[part 1 of 3: package /STLASWCs]
AUTOSAR XML (schema 00044)
package /STLASWCs
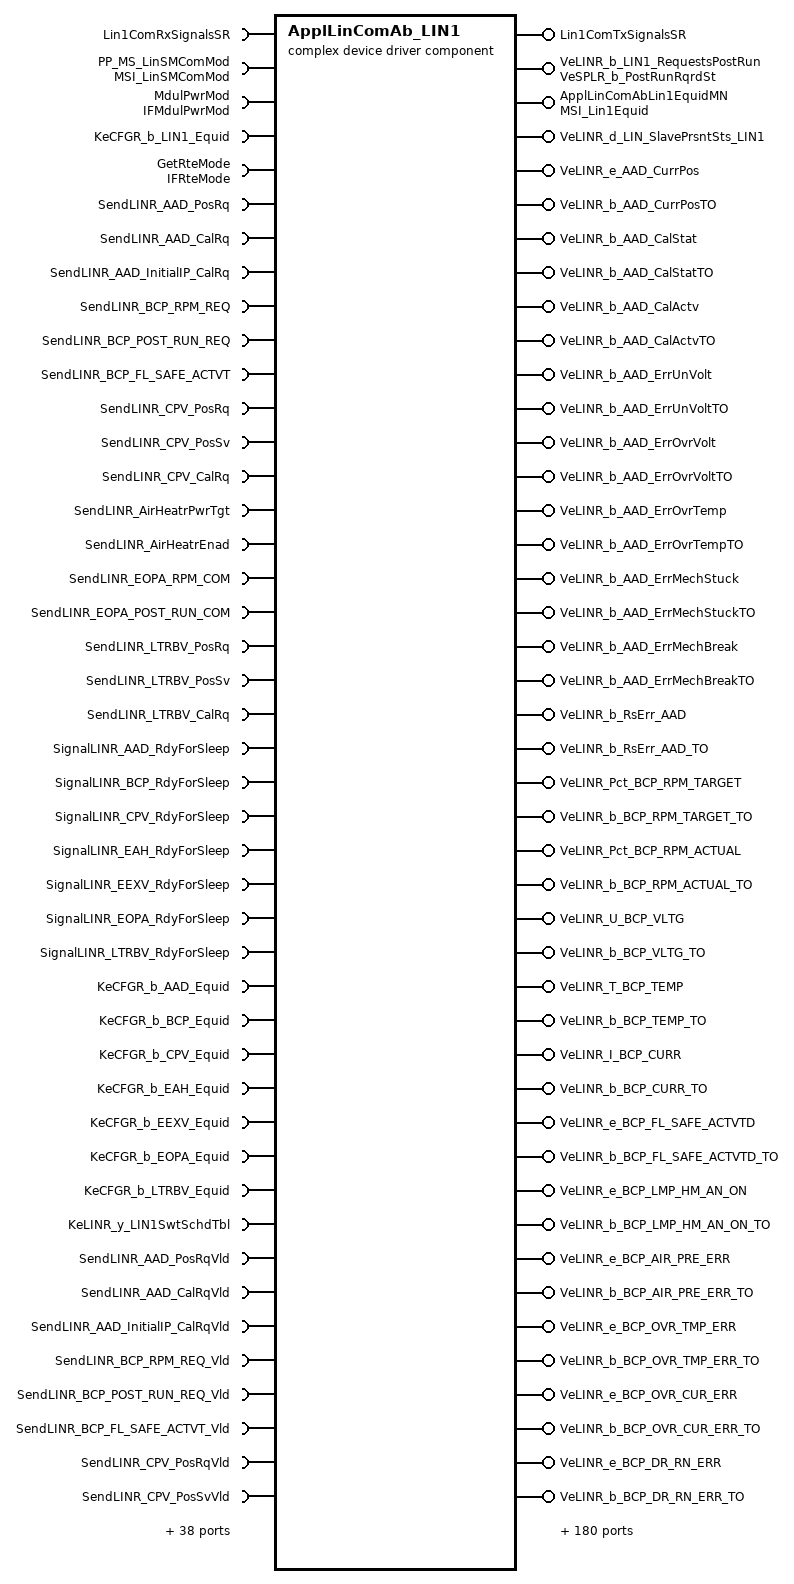
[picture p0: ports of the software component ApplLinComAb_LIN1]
  complex device driver sw component type ApplLinComAb_LIN1  # Application CAN Communication Abstraction Component - is responsible with receiving and sending CAN data from/to the lower BSW COM layers
    provide port Lin1ComTxSignalsSR: provided-interface=Lin1ComTxSignalsSR
      provided-com-specs:
        data-element=COMTXL_AAD_PosRq_ECM_AAD_DEMAND_Lin1, init-value=constant-reference=COMTXL_AAD_PosRq_ECM_AAD_DEMAND_Lin1_Init
        data-element=COMTXL_AAD_CalRq_ECM_AAD_DEMAND_Lin1, init-value=constant-reference=COMTXL_AAD_CalRq_ECM_AAD_DEMAND_Lin1_Init
        data-element=COMTXL_AAD_InitialIP_CalRq_ECM_AAD_DEMAND_Lin1, init-value=constant-reference=COMTXL_AAD_InitialIP_CalRq_ECM_AAD_DEMAND_Lin1_Init
        data-element=COMTXL_BCP_RPM_REQ_BCP_REQ_Lin1, init-value=constant-reference=COMTXL_BCP_RPM_REQ_BCP_REQ_Lin1_Init
        data-element=COMTXL_BCP_POST_RUN_REQ_BCP_REQ_Lin1, init-value=constant-reference=COMTXL_BCP_POST_RUN_REQ_BCP_REQ_Lin1_Init
        data-element=COMTXL_BCP_FL_SAFE_ACTVT_BCP_REQ_Lin1, init-value=constant-reference=COMTXL_BCP_FL_SAFE_ACTVT_BCP_REQ_Lin1_Init
        data-element=COMTXL_CPV_PosRq_CPV_REQ_Lin1, init-value=constant-reference=COMTXL_CPV_PosRq_CPV_REQ_Lin1_Init
        data-element=COMTXL_CPV_PosSv_CPV_REQ_Lin1, init-value=constant-reference=COMTXL_CPV_PosSv_CPV_REQ_Lin1_Init
        data-element=COMTXL_CPV_CalRq_CPV_REQ_Lin1, init-value=constant-reference=COMTXL_CPV_CalRq_CPV_REQ_Lin1_Init
        data-element=COMTXL_AirHeatrPwrTgt_HVEAHLIN18Fr03_Lin1, init-value=constant-reference=COMTXL_AirHeatrPwrTgt_HVEAHLIN18Fr03_Lin1_Init
        data-element=COMTXL_AirHeatrEnad_HVEAHLIN18Fr03_Lin1, init-value=constant-reference=COMTXL_AirHeatrEnad_HVEAHLIN18Fr03_Lin1_Init
        data-element=COMTXL_EOPA_RPM_COM_EOPA_REQ_Lin1, init-value=constant-reference=COMTXL_EOPA_RPM_COM_EOPA_REQ_Lin1_Init
        data-element=COMTXL_EOPA_POST_RUN_COM_EOPA_REQ_Lin1, init-value=constant-reference=COMTXL_EOPA_POST_RUN_COM_EOPA_REQ_Lin1_Init
        data-element=COMTXL_LTRBV_PosRq_LTRBV_REQ_Lin1, init-value=constant-reference=COMTXL_LTRBV_PosRq_LTRBV_REQ_Lin1_Init
        data-element=COMTXL_LTRBV_PosSv_LTRBV_REQ_Lin1, init-value=constant-reference=COMTXL_LTRBV_PosSv_LTRBV_REQ_Lin1_Init
        data-element=COMTXL_LTRBV_CalRq_LTRBV_REQ_Lin1, init-value=constant-reference=COMTXL_LTRBV_CalRq_LTRBV_REQ_Lin1_Init
        data-element=COMTXL_EEXV_PosRq_EEXV_REQ_Lin1, init-value=constant-reference=COMTXL_EEXV_PosRq_EEXV_REQ_Lin1_Init
        data-element=COMTXL_EEXV_CalCmd_EEXV_REQ_Lin1, init-value=constant-reference=COMTXL_EEXV_CalCmd_EEXV_REQ_Lin1_Init
        data-element=COMTXL_EXVM_PosRq_EXVM_REQ_Lin1, init-value=constant-reference=COMTXL_EXVM_PosRq_EXVM_REQ_Lin1_Init
        data-element=COMTXL_EXVM_CalCmd_EXVM_REQ_Lin1, init-value=constant-reference=COMTXL_EXVM_CalCmd_EXVM_REQ_Lin1_Init
        data-element=COMTXL_Control_TargetPos_FCPS_CoolantValve_Control_Lin1, init-value=constant-reference=COMTXL_Control_TargetPos_FCPS_CoolantValve_Control_Lin1_Init
        data-element=COMTXL_Control_Reserved1_FCPS_CoolantValve_Control_Lin1, init-value=constant-reference=COMTXL_Control_Reserved1_FCPS_CoolantValve_Control_Lin1_Init
        data-element=COMTXL_Control_BlockDetEnbl_FCPS_CoolantValve_Control_Lin1, init-value=constant-reference=COMTXL_Control_BlockDetEnbl_FCPS_CoolantValve_Control_Lin1_Init
        data-element=COMTXL_Control_DiagFunctnValue_FCPS_CoolantValve_Control_Lin1, init-value=constant-reference=COMTXL_Control_DiagFunctnValue_FCPS_CoolantValve_Control_Lin1_Init
        data-element=COMTXL_Control_Reserved{2..6}_FCPS_CoolantValve_Control_Lin1, init-value=constant-reference=COMTXL_Control_Reserved{2..6}_FCPS_CoolantValve_Control_Lin1_Init
    provide port VeLINR_b_LIN1_RequestsPostRun: nonqueued-sender-com-spec{data-element=VeSPLR_b_PostRunRqrdSt, init-value=1}, provided-interface=VeSPLR_b_PostRunRqrdSt  # Indicates LIN is ready for power down
    36 x require port:
      Lin1ComRxSignalsSR: required-interface=Lin1ComRxSignalsSR
        required-com-specs:
          data-element=COMRXL_AAD_CurrPos_AAD_ECM_STATUS_Lin1, alive-timeout=2.5, handle-never-received=true, init-value=constant-reference=COMRXL_AAD_CurrPos_AAD_ECM_STATUS_Lin1_Init
          data-element=COMRXL_AAD_CalStat_AAD_ECM_STATUS_Lin1, alive-timeout=2.5, handle-never-received=true, init-value=constant-reference=COMRXL_AAD_CalStat_AAD_ECM_STATUS_Lin1_Init
          data-element=COMRXL_AAD_CalActv_AAD_ECM_STATUS_Lin1, alive-timeout=2.5, handle-never-received=true, init-value=constant-reference=COMRXL_AAD_CalActv_AAD_ECM_STATUS_Lin1_Init
          data-element=COMRXL_AAD_ErrUnVolt_AAD_ECM_STATUS_Lin1, alive-timeout=2.5, handle-never-received=true, init-value=constant-reference=COMRXL_AAD_ErrUnVolt_AAD_ECM_STATUS_Lin1_Init
          data-element=COMRXL_AAD_ErrOvrVolt_AAD_ECM_STATUS_Lin1, alive-timeout=2.5, handle-never-received=true, init-value=constant-reference=COMRXL_AAD_ErrOvrVolt_AAD_ECM_STATUS_Lin1_Init
          data-element=COMRXL_AAD_ErrOvrTemp_AAD_ECM_STATUS_Lin1, alive-timeout=2.5, handle-never-received=true, init-value=constant-reference=COMRXL_AAD_ErrOvrTemp_AAD_ECM_STATUS_Lin1_Init
          data-element=COMRXL_AAD_ErrMechStuck_AAD_ECM_STATUS_Lin1, alive-timeout=2.5, handle-never-received=true, init-value=constant-reference=COMRXL_AAD_ErrMechStuck_AAD_ECM_STATUS_Lin1_Init
          data-element=COMRXL_AAD_ErrMechBreak_AAD_ECM_STATUS_Lin1, alive-timeout=2.5, handle-never-received=true, init-value=constant-reference=COMRXL_AAD_ErrMechBreak_AAD_ECM_STATUS_Lin1_Init
          data-element=COMRXL_RsErr_AAD_AAD_ECM_STATUS_Lin1, alive-timeout=2.5, handle-never-received=true, init-value=constant-reference=COMRXL_RsErr_AAD_AAD_ECM_STATUS_Lin1_Init
          data-element=COMRXL_BCP_RPM_TARGET_BCP_STAT_Lin1, alive-timeout=2.5, handle-never-received=true, init-value=constant-reference=COMRXL_BCP_RPM_TARGET_BCP_STAT_Lin1_Init
          data-element=COMRXL_BCP_RPM_ACTUAL_BCP_STAT_Lin1, alive-timeout=2.5, handle-never-received=true, init-value=constant-reference=COMRXL_BCP_RPM_ACTUAL_BCP_STAT_Lin1_Init
          data-element=COMRXL_BCP_VLTG_BCP_STAT_Lin1, alive-timeout=2.5, handle-never-received=true, init-value=constant-reference=COMRXL_BCP_VLTG_BCP_STAT_Lin1_Init
          data-element=COMRXL_BCP_TEMP_BCP_STAT_Lin1, alive-timeout=2.5, handle-never-received=true, init-value=constant-reference=COMRXL_BCP_TEMP_BCP_STAT_Lin1_Init
          data-element=COMRXL_BCP_CURR_BCP_STAT_Lin1, alive-timeout=2.5, handle-never-received=true, init-value=constant-reference=COMRXL_BCP_CURR_BCP_STAT_Lin1_Init
          data-element=COMRXL_BCP_FL_SAFE_ACTVTD_BCP_STAT_Lin1, alive-timeout=2.5, handle-never-received=true, init-value=constant-reference=COMRXL_BCP_FL_SAFE_ACTVTD_BCP_STAT_Lin1_Init
          data-element=COMRXL_BCP_LMP_HM_AN_ON_BCP_STAT_Lin1, alive-timeout=2.5, handle-never-received=true, init-value=constant-reference=COMRXL_BCP_LMP_HM_AN_ON_BCP_STAT_Lin1_Init
          data-element=COMRXL_BCP_AIR_PRE_ERR_BCP_STAT_Lin1, alive-timeout=2.5, handle-never-received=true, init-value=constant-reference=COMRXL_BCP_AIR_PRE_ERR_BCP_STAT_Lin1_Init
          data-element=COMRXL_BCP_OVR_TMP_ERR_BCP_STAT_Lin1, alive-timeout=2.5, handle-never-received=true, init-value=constant-reference=COMRXL_BCP_OVR_TMP_ERR_BCP_STAT_Lin1_Init
          data-element=COMRXL_BCP_OVR_CUR_ERR_BCP_STAT_Lin1, alive-timeout=2.5, handle-never-received=true, init-value=constant-reference=COMRXL_BCP_OVR_CUR_ERR_BCP_STAT_Lin1_Init
          data-element=COMRXL_BCP_DR_RN_ERR_BCP_STAT_Lin1, alive-timeout=2.5, handle-never-received=true, init-value=constant-reference=COMRXL_BCP_DR_RN_ERR_BCP_STAT_Lin1_Init
          data-element=COMRXL_BCP_VLTG_ERR_BCP_STAT_Lin1, alive-timeout=2.5, handle-never-received=true, init-value=constant-reference=COMRXL_BCP_VLTG_ERR_BCP_STAT_Lin1_Init
          data-element=COMRXL_BCP_DBLK_ACTV_BCP_STAT_Lin1, alive-timeout=2.5, handle-never-received=true, init-value=constant-reference=COMRXL_BCP_DBLK_ACTV_BCP_STAT_Lin1_Init
          data-element=COMRXL_BCP_MONTRNG_RPM_BCP_STAT_Lin1, alive-timeout=2.5, handle-never-received=true, init-value=constant-reference=COMRXL_BCP_MONTRNG_RPM_BCP_STAT_Lin1_Init
          data-element=COMRXL_BCP_NODE_ERR_BCP_STAT_Lin1, alive-timeout=2.5, handle-never-received=true, init-value=constant-reference=COMRXL_BCP_NODE_ERR_BCP_STAT_Lin1_Init
          data-element=COMRXL_BCP_POST_RUN_STAT_BCP_STAT_Lin1, alive-timeout=2.5, handle-never-received=true, init-value=constant-reference=COMRXL_BCP_POST_RUN_STAT_BCP_STAT_Lin1_Init
          data-element=COMRXL_RsErr_BCP_PUMP_BCP_STAT_Lin1, alive-timeout=2.5, handle-never-received=true, init-value=constant-reference=COMRXL_RsErr_BCP_PUMP_BCP_STAT_Lin1_Init
          data-element=COMRXL_BCP_VERSION_BCP_VER_Lin1, alive-timeout=2.5, handle-never-received=true, init-value=constant-reference=COMRXL_BCP_VERSION_BCP_VER_Lin1_Init
          data-element=COMRXL_BCP_SUPPLIER_BCP_VER_Lin1, alive-timeout=2.5, handle-never-received=true, init-value=constant-reference=COMRXL_BCP_SUPPLIER_BCP_VER_Lin1_Init
          data-element=COMRXL_CPV_PosAct_CPV_STAT_V2_Lin1, alive-timeout=2.5, handle-never-received=true, init-value=constant-reference=COMRXL_CPV_PosAct_CPV_STAT_V2_Lin1_Init
          data-element=COMRXL_CPV_ERR_CPV_STAT_V2_Lin1, alive-timeout=2.5, handle-never-received=true, init-value=constant-reference=COMRXL_CPV_ERR_CPV_STAT_V2_Lin1_Init
          data-element=COMRXL_CPV_Sts_CPV_STAT_V2_Lin1, alive-timeout=2.5, handle-never-received=true, init-value=constant-reference=COMRXL_CPV_Sts_CPV_STAT_V2_Lin1_Init
          data-element=COMRXL_RsErr_CPV_CPV_STAT_V2_Lin1, alive-timeout=2.5, handle-never-received=true, init-value=constant-reference=COMRXL_RsErr_CPV_CPV_STAT_V2_Lin1_Init
          data-element=COMRXL_AirHeatrICns_HVEAHLIN18Fr01_Lin1, alive-timeout=2.5, handle-never-received=true, init-value=constant-reference=COMRXL_AirHeatrICns_HVEAHLIN18Fr01_Lin1_Init
          data-element=COMRXL_AirHeatrHVmeas_HVEAHLIN18Fr01_Lin1, alive-timeout=2.5, handle-never-received=true, init-value=constant-reference=COMRXL_AirHeatrHVmeas_HVEAHLIN18Fr01_Lin1_Init
          data-element=COMRXL_AirHeatrPCBTemp_HVEAHLIN18Fr01_Lin1, alive-timeout=2.5, handle-never-received=true, init-value=constant-reference=COMRXL_AirHeatrPCBTemp_HVEAHLIN18Fr01_Lin1_Init
          data-element=COMRXL_AirHeatrCoreTemp_HVEAHLIN18Fr01_Lin1, alive-timeout=2.5, handle-never-received=true, init-value=constant-reference=COMRXL_AirHeatrCoreTemp_HVEAHLIN18Fr01_Lin1_Init
          data-element=COMRXL_RsErr_EAH_HVEAHLIN18Fr02_Lin1, alive-timeout=2.5, handle-never-received=true, init-value=constant-reference=COMRXL_RsErr_EAH_HVEAHLIN18Fr02_Lin1_Init
          data-element=COMRXL_AirHeatrWarnFltInCom_HVEAHLIN18Fr02_Lin1, alive-timeout=2.5, handle-never-received=true, init-value=constant-reference=COMRXL_AirHeatrWarnFltInCom_HVEAHLIN18Fr02_Lin1_Init
          data-element=COMRXL_AirHeatrWarnHvOutOfRng_HVEAHLIN18Fr02_Lin1, alive-timeout=2.5, handle-never-received=true, init-value=constant-reference=COMRXL_AirHeatrWarnHvOutOfRng_HVEAHLIN18Fr02_Lin1_Init
          data-element=COMRXL_AirHeatrWarnULoOutOfRng_HVEAHLIN18Fr02_Lin1, alive-timeout=2.5, handle-never-received=true, init-value=constant-reference=COMRXL_AirHeatrWarnULoOutOfRng_HVEAHLIN18Fr02_Lin1_Init
          data-element=COMRXL_AirHeatrWarnTmpOvrheatg_HVEAHLIN18Fr02_Lin1, alive-timeout=2.5, handle-never-received=true, init-value=constant-reference=COMRXL_AirHeatrWarnTmpOvrheatg_HVEAHLIN18Fr02_Lin1_Init
          data-element=COMRXL_AirHeatrWarnICnsOutOfRng_HVEAHLIN18Fr02_Lin1, alive-timeout=2.5, handle-never-received=true, init-value=constant-reference=COMRXL_AirHeatrWarnICnsOutOfRng_HVEAHLIN18Fr02_Lin1_Init
          data-element=COMRXL_AirHeatrDmgIntHwProtn_HVEAHLIN18Fr02_Lin1, alive-timeout=2.5, handle-never-received=true, init-value=constant-reference=COMRXL_AirHeatrDmgIntHwProtn_HVEAHLIN18Fr02_Lin1_Init
          data-element=COMRXL_AirHeatrDmgPCBTmpSnsrFlt_HVEAHLIN18Fr02_Lin1, alive-timeout=2.5, handle-never-received=true, init-value=constant-reference=COMRXL_AirHeatrDmgPCBTmpSnsrFlt_HVEAHLIN18Fr02_Lin1_Init
          data-element=COMRXL_AirHeatrDmgCircForDrvrShoOrOpen_HVEAHLIN18Fr02_Lin1, alive-timeout=2.5, handle-never-received=true, init-value=constant-reference=COMRXL_AirHeatrDmgCircForDrvrShoOrOpen_HVEAHLIN18Fr02_Lin1_Init
          data-element=COMRXL_AirHeatrDmgHVISnsrFlt_HVEAHLIN18Fr02_Lin1, alive-timeout=2.5, handle-never-received=true, init-value=constant-reference=COMRXL_AirHeatrDmgHVISnsrFlt_HVEAHLIN18Fr02_Lin1_Init
          data-element=COMRXL_AirHeatrDmgMemErr_HVEAHLIN18Fr02_Lin1, alive-timeout=2.5, handle-never-received=true, init-value=constant-reference=COMRXL_AirHeatrDmgMemErr_HVEAHLIN18Fr02_Lin1_Init
          data-element=COMRXL_AirHeatrDmgHtrCoreTmpSnsrFlt_HVEAHLIN18Fr02_Lin1, alive-timeout=2.5, handle-never-received=true, init-value=constant-reference=COMRXL_AirHeatrDmgHtrCoreTmpSnsrFlt_HVEAHLIN18Fr02_Lin1_Init
          data-element=COMRXL_AirHeatrWarnPCBOvrTmp_HVEAHLIN18Fr02_Lin1, alive-timeout=2.5, handle-never-received=true, init-value=constant-reference=COMRXL_AirHeatrWarnPCBOvrTmp_HVEAHLIN18Fr02_Lin1_Init
          data-element=COMRXL_AirHeatrWarnHtrCoreOvrTmp_HVEAHLIN18Fr02_Lin1, alive-timeout=2.5, handle-never-received=true, init-value=constant-reference=COMRXL_AirHeatrWarnHtrCoreOvrTmp_HVEAHLIN18Fr02_Lin1_Init
          data-element=COMRXL_EOPA_RPM_TGT_EOPA_STAT_Lin1, alive-timeout=2.5, handle-never-received=true, init-value=constant-reference=COMRXL_EOPA_RPM_TGT_EOPA_STAT_Lin1_Init
          data-element=COMRXL_EOPA_RPM_ACTL_EOPA_STAT_Lin1, alive-timeout=2.5, handle-never-received=true, init-value=constant-reference=COMRXL_EOPA_RPM_ACTL_EOPA_STAT_Lin1_Init
          data-element=COMRXL_EOPA_VLTG_EOPA_STAT_Lin1, alive-timeout=2.5, handle-never-received=true, init-value=constant-reference=COMRXL_EOPA_VLTG_EOPA_STAT_Lin1_Init
          data-element=COMRXL_EOPA_TEMP_EOPA_STAT_Lin1, alive-timeout=2.5, handle-never-received=true, init-value=constant-reference=COMRXL_EOPA_TEMP_EOPA_STAT_Lin1_Init
          data-element=COMRXL_EOPA_CURR_EOPA_STAT_Lin1, alive-timeout=2.5, handle-never-received=true, init-value=constant-reference=COMRXL_EOPA_CURR_EOPA_STAT_Lin1_Init
          data-element=COMRXL_EOPA_LOW_TMP_STAT_EOPA_STAT_Lin1, alive-timeout=2.5, handle-never-received=true, init-value=constant-reference=COMRXL_EOPA_LOW_TMP_STAT_EOPA_STAT_Lin1_Init
          data-element=COMRXL_EOPA_MONTRNG_RPM_EOPA_STAT_Lin1, alive-timeout=2.5, handle-never-received=true, init-value=constant-reference=COMRXL_EOPA_MONTRNG_RPM_EOPA_STAT_Lin1_Init
          data-element=COMRXL_EOPA_LMP_HM_AN_ON_EOPA_STAT_Lin1, alive-timeout=2.5, handle-never-received=true, init-value=constant-reference=COMRXL_EOPA_LMP_HM_AN_ON_EOPA_STAT_Lin1_Init
          data-element=COMRXL_EOPA_OV_TMP_ER_EOPA_STAT_Lin1, alive-timeout=2.5, handle-never-received=true, init-value=constant-reference=COMRXL_EOPA_OV_TMP_ER_EOPA_STAT_Lin1_Init
          data-element=COMRXL_EOPA_OV_CUR_ER_EOPA_STAT_Lin1, alive-timeout=2.5, handle-never-received=true, init-value=constant-reference=COMRXL_EOPA_OV_CUR_ER_EOPA_STAT_Lin1_Init
          data-element=COMRXL_EOPA_DR_RN_ER_EOPA_STAT_Lin1, alive-timeout=2.5, handle-never-received=true, init-value=constant-reference=COMRXL_EOPA_DR_RN_ER_EOPA_STAT_Lin1_Init
          data-element=COMRXL_EOPA_VLTG_ER_EOPA_STAT_Lin1, alive-timeout=2.5, handle-never-received=true, init-value=constant-reference=COMRXL_EOPA_VLTG_ER_EOPA_STAT_Lin1_Init
          data-element=COMRXL_EOPA_Stall_Event_EOPA_STAT_Lin1, alive-timeout=2.5, handle-never-received=true, init-value=constant-reference=COMRXL_EOPA_Stall_Event_EOPA_STAT_Lin1_Init
          data-element=COMRXL_EOPA_POST_RUN_STAT_EOPA_STAT_Lin1, alive-timeout=2.5, handle-never-received=true, init-value=constant-reference=COMRXL_EOPA_POST_RUN_STAT_EOPA_STAT_Lin1_Init
          data-element=COMRXL_RsErr_EOPA_EOPA_STAT_Lin1, alive-timeout=2.5, handle-never-received=true, init-value=constant-reference=COMRXL_RsErr_EOPA_EOPA_STAT_Lin1_Init
          data-element=COMRXL_EOPA_OIL_TEMP_EOPA_STAT2_Lin1, alive-timeout=2.5, handle-never-received=true, init-value=constant-reference=COMRXL_EOPA_OIL_TEMP_EOPA_STAT2_Lin1_Init
          data-element=COMRXL_EOPA_HW_VER_EOPA_VER_Lin1, alive-timeout=2.5, handle-never-received=true, init-value=constant-reference=COMRXL_EOPA_HW_VER_EOPA_VER_Lin1_Init
          data-element=COMRXL_EOPA_SW_VER_EOPA_VER_Lin1, alive-timeout=2.5, handle-never-received=true, init-value=constant-reference=COMRXL_EOPA_SW_VER_EOPA_VER_Lin1_Init
          data-element=COMRXL_LTRBV_PosAct_LTRBV_STAT_Lin1, alive-timeout=2.5, handle-never-received=true, init-value=constant-reference=COMRXL_LTRBV_PosAct_LTRBV_STAT_Lin1_Init
          data-element=COMRXL_LTRBV_ERR_LTRBV_STAT_Lin1, alive-timeout=2.5, handle-never-received=true, init-value=constant-reference=COMRXL_LTRBV_ERR_LTRBV_STAT_Lin1_Init
          data-element=COMRXL_LTRBV_MotorVolt_LTRBV_STAT_Lin1, alive-timeout=2.5, handle-never-received=true, init-value=constant-reference=COMRXL_LTRBV_MotorVolt_LTRBV_STAT_Lin1_Init
          data-element=COMRXL_LTRBV_Sts_LTRBV_STAT_Lin1, alive-timeout=2.5, handle-never-received=true, init-value=constant-reference=COMRXL_LTRBV_Sts_LTRBV_STAT_Lin1_Init
          data-element=COMRXL_RsErr_LTRBV_LTRBV_STAT_Lin1, alive-timeout=2.5, handle-never-received=true, init-value=constant-reference=COMRXL_RsErr_LTRBV_LTRBV_STAT_Lin1_Init
          data-element=COMRXL_CPV_MotorVolt_CPV_STAT_V2_Lin1, alive-timeout=2.5, handle-never-received=true, init-value=constant-reference=COMRXL_CPV_MotorVolt_CPV_STAT_V2_Lin1_Init
          data-element=COMRXL_CPV_CalStat_CPV_STAT_V2_Lin1, alive-timeout=2.5, handle-never-received=true, init-value=constant-reference=COMRXL_CPV_CalStat_CPV_STAT_V2_Lin1_Init
          data-element=COMRXL_AirHeatrSts_HVEAHLIN18Fr01_Lin1, alive-timeout=2.5, handle-never-received=true, init-value=constant-reference=COMRXL_AirHeatrSts_HVEAHLIN18Fr01_Lin1_Init
          data-element=COMRXL_AirHeatrPwrCns_HVEAHLIN18Fr01_Lin1, alive-timeout=2.5, handle-never-received=true, init-value=constant-reference=COMRXL_AirHeatrPwrCns_HVEAHLIN18Fr01_Lin1_Init
          data-element=COMRXL_EEXV_PosAct_EEXV_STAT_Lin1, alive-timeout=2.5, handle-never-received=true, init-value=constant-reference=COMRXL_EEXV_PosAct_EEXV_STAT_Lin1_Init
          data-element=COMRXL_EEXV_CalStat_EEXV_STAT_Lin1, alive-timeout=2.5, handle-never-received=true, init-value=constant-reference=COMRXL_EEXV_CalStat_EEXV_STAT_Lin1_Init
          data-element=COMRXL_EEXV_CalRq_EEXV_STAT_Lin1, alive-timeout=2.5, handle-never-received=true, init-value=constant-reference=COMRXL_EEXV_CalRq_EEXV_STAT_Lin1_Init
          data-element=COMRXL_RsErr_EEXV_EEXV_STAT_Lin1, alive-timeout=2.5, handle-never-received=true, init-value=constant-reference=COMRXL_RsErr_EEXV_EEXV_STAT_Lin1_Init
          data-element=COMRXL_EEXV_Sts_EEXV_STAT_Lin1, alive-timeout=2.5, handle-never-received=true, init-value=constant-reference=COMRXL_EEXV_Sts_EEXV_STAT_Lin1_Init
          data-element=COMRXL_EEXV_ERR_EEXV_STAT_Lin1, alive-timeout=2.5, handle-never-received=true, init-value=constant-reference=COMRXL_EEXV_ERR_EEXV_STAT_Lin1_Init
          data-element=COMRXL_EEXV_SupplyVolt_EEXV_STAT_Lin1, alive-timeout=2.5, handle-never-received=true, init-value=constant-reference=COMRXL_EEXV_SupplyVolt_EEXV_STAT_Lin1_Init
          data-element=COMRXL_EEXV_Refrigerant_Pressure_EEXV_STAT_Lin1, alive-timeout=2.5, handle-never-received=true, init-value=constant-reference=COMRXL_EEXV_Refrigerant_Pressure_EEXV_STAT_Lin1_Init
          data-element=COMRXL_EEXV_Board_Temp_EEXV_STAT_Lin1, alive-timeout=2.5, handle-never-received=true, init-value=constant-reference=COMRXL_EEXV_Board_Temp_EEXV_STAT_Lin1_Init
          data-element=COMRXL_EEXV_Refrigerant_Temp_EEXV_STAT_Lin1, alive-timeout=2.5, handle-never-received=true, init-value=constant-reference=COMRXL_EEXV_Refrigerant_Temp_EEXV_STAT_Lin1_Init
          data-element=COMRXL_EXVM_PosAct_EXVM_STAT_Lin1, alive-timeout=2.5, handle-never-received=true, init-value=constant-reference=COMRXL_EXVM_PosAct_EXVM_STAT_Lin1_Init
          data-element=COMRXL_EXVM_CalStat_EXVM_STAT_Lin1, alive-timeout=2.5, handle-never-received=true, init-value=constant-reference=COMRXL_EXVM_CalStat_EXVM_STAT_Lin1_Init
          data-element=COMRXL_EXVM_CalRq_EXVM_STAT_Lin1, alive-timeout=2.5, handle-never-received=true, init-value=constant-reference=COMRXL_EXVM_CalRq_EXVM_STAT_Lin1_Init
          data-element=COMRXL_RsErr_EXVM_EXVM_STAT_Lin1, alive-timeout=2.5, handle-never-received=true, init-value=constant-reference=COMRXL_RsErr_EXVM_EXVM_STAT_Lin1_Init
          data-element=COMRXL_EXVM_Sts_EXVM_STAT_Lin1, alive-timeout=2.5, handle-never-received=true, init-value=constant-reference=COMRXL_EXVM_Sts_EXVM_STAT_Lin1_Init
          data-element=COMRXL_EXVM_ERR_EXVM_STAT_Lin1, alive-timeout=2.5, handle-never-received=true, init-value=constant-reference=COMRXL_EXVM_ERR_EXVM_STAT_Lin1_Init
          data-element=COMRXL_EXVM_SupplyVolt_EXVM_STAT_Lin1, alive-timeout=2.5, handle-never-received=true, init-value=constant-reference=COMRXL_EXVM_SupplyVolt_EXVM_STAT_Lin1_Init
          data-element=COMRXL_EXVM_Refrigerant_Pressure_EXVM_STAT_Lin1, alive-timeout=2.5, handle-never-received=true, init-value=constant-reference=COMRXL_EXVM_Refrigerant_Pressure_EXVM_STAT_Lin1_Init
          data-element=COMRXL_EXVM_Board_Temp_EXVM_STAT_Lin1, alive-timeout=2.5, handle-never-received=true, init-value=constant-reference=COMRXL_EXVM_Board_Temp_EXVM_STAT_Lin1_Init
          data-element=COMRXL_EXVM_Refrigerant_Temp_EXVM_STAT_Lin1, alive-timeout=2.5, handle-never-received=true, init-value=constant-reference=COMRXL_EXVM_Refrigerant_Temp_EXVM_STAT_Lin1_Init
          data-element=COMRXL_LTRBV_CalStat_LTRBV_STAT_Lin1, alive-timeout=2.5, handle-never-received=true, init-value=constant-reference=COMRXL_LTRBV_CalStat_LTRBV_STAT_Lin1_Init
          data-element=COMRXL_CoolantValve_ErrLinCom_CoolantValve_Com_Lin1, alive-timeout=2.5, handle-never-received=true, init-value=constant-reference=COMRXL_CoolantValve_ErrLinCom_CoolantValve_Com_Lin1_Init
          data-element=COMRXL_CoolantValve_ErrPosition_CoolantValve_Com_Lin1, alive-timeout=2.5, handle-never-received=true, init-value=constant-reference=COMRXL_CoolantValve_ErrPosition_CoolantValve_Com_Lin1_Init
          data-element=COMRXL_CoolantValve_SelfCalReq_CoolantValve_Com_Lin1, alive-timeout=2.5, handle-never-received=true, init-value=constant-reference=COMRXL_CoolantValve_SelfCalReq_CoolantValve_Com_Lin1_Init
          data-element=COMRXL_CoolantValve_SystemState_CoolantValve_Com_Lin1, alive-timeout=2.5, handle-never-received=true, init-value=constant-reference=COMRXL_CoolantValve_SystemState_CoolantValve_Com_Lin1_Init
          data-element=COMRXL_CoolantValve_EcuVoltage_CoolantValve_Com_Lin1, alive-timeout=2.5, handle-never-received=true, init-value=constant-reference=COMRXL_CoolantValve_EcuVoltage_CoolantValve_Com_Lin1_Init
          data-element=COMRXL_CoolantValve_ActuatorPositionTrgt_CoolantValve_Com_Lin1, alive-timeout=2.5, handle-never-received=true, init-value=constant-reference=COMRXL_CoolantValve_ActuatorPositionTrgt_CoolantValve_Com_Lin1_Init
          data-element=COMRXL_CoolantValve_ActuatorPositionAct_CoolantValve_Com_Lin1, alive-timeout=2.5, handle-never-received=true, init-value=constant-reference=COMRXL_CoolantValve_ActuatorPositionAct_CoolantValve_Com_Lin1_Init
          data-element=COMRXL_CoolantValve_EcuTemperatur_CoolantValve_Com_Lin1, alive-timeout=2.5, handle-never-received=true, init-value=constant-reference=COMRXL_CoolantValve_EcuTemperatur_CoolantValve_Com_Lin1_Init
          data-element=COMRXL_CoolantValve_Err_Motor_CoolantValve_Com_Lin1, alive-timeout=2.5, handle-never-received=true, init-value=constant-reference=COMRXL_CoolantValve_Err_Motor_CoolantValve_Com_Lin1_Init
          data-element=COMRXL_CoolantValve_Err_Voltage_CoolantValve_Com_Lin1, alive-timeout=2.5, handle-never-received=true, init-value=constant-reference=COMRXL_CoolantValve_Err_Voltage_CoolantValve_Com_Lin1_Init
          data-element=COMRXL_CoolantValve_Err_Ecu_CoolantValve_Com_Lin1, alive-timeout=2.5, handle-never-received=true, init-value=constant-reference=COMRXL_CoolantValve_Err_Ecu_CoolantValve_Com_Lin1_Init
          data-element=COMRXL_CoolantValve_ResponseError_CoolantValve_Com_Lin1, alive-timeout=2.5, handle-never-received=true, init-value=constant-reference=COMRXL_CoolantValve_ResponseError_CoolantValve_Com_Lin1_Init
      PP_MS_LinSMComMod: mode-switch-receiver-com-spec=MDGP_MSI_LinSMComMod, required-interface=MSI_LinSMComMod  # Mode switch port used to indicate Linsm comm state
      MdulPwrMod: mode-switch-receiver-com-spec=AppMode_MDGP_ESH_Mode, required-interface=IFMdulPwrMod  # Mode switch port used to indicate ECU state
      KeCFGR_b_LIN1_Equid: parameter-require-com-spec{init-value=Value:1, parameter=KeCFGR_b_LIN1_Equid}, required-interface=KeCFGR_b_LIN1_Equid
      GetRteMode: client-com-spec=GetMODR_b_InPostRunMode, required-interface=IFRteMode
      SendLINR_AAD_PosRq: nonqueued-receiver-com-spec{data-element=SendLINR_AAD_PosRq, init-value=SendLINR_AAD_PosRqValue:15}, required-interface=SendLINR_AAD_PosRq
      SendLINR_AAD_CalRq: nonqueued-receiver-com-spec{data-element=SendLINR_AAD_CalRq, init-value=SendLINR_AAD_CalRqValue:0}, required-interface=SendLINR_AAD_CalRq
      SendLINR_AAD_InitialIP_CalRq: nonqueued-receiver-com-spec{data-element=SendLINR_AAD_InitialIP_CalRq, init-value=0}, required-interface=SendLINR_AAD_InitialIP_CalRq
      SendLINR_BCP_RPM_REQ: nonqueued-receiver-com-spec{data-element=SendLINR_BCP_RPM_REQ, init-value=SendLINR_BCP_RPM_REQValue:100.3935}, required-interface=SendLINR_BCP_RPM_REQ
      SendLINR_BCP_POST_RUN_REQ: nonqueued-receiver-com-spec{data-element=SendLINR_BCP_POST_RUN_REQ, init-value=SendLINR_BCP_POST_RUN_REQValue:7}, required-interface=SendLINR_BCP_POST_RUN_REQ
      SendLINR_BCP_FL_SAFE_ACTVT: nonqueued-receiver-com-spec{data-element=SendLINR_BCP_FL_SAFE_ACTVT, init-value=SendLINR_BCP_FL_SAFE_ACTVTValue:3}, required-interface=SendLINR_BCP_FL_SAFE_ACTVT
      SendLINR_CPV_PosRq: nonqueued-receiver-com-spec{data-element=SendLINR_CPV_PosRq, init-value=SendLINR_CPV_PosRqValue:0}, required-interface=SendLINR_CPV_PosRq
      SendLINR_CPV_PosSv: nonqueued-receiver-com-spec{data-element=SendLINR_CPV_PosSv, init-value=SendLINR_CPV_PosSvValue:0}, required-interface=SendLINR_CPV_PosSv
      SendLINR_CPV_CalRq: nonqueued-receiver-com-spec{data-element=SendLINR_CPV_CalRq, init-value=SendLINR_CPV_CalRqValue:0}, required-interface=SendLINR_CPV_CalRq
      SendLINR_AirHeatrPwrTgt: nonqueued-receiver-com-spec{data-element=SendLINR_AirHeatrPwrTgt, init-value=SendLINR_AirHeatrPwrTgtValue:255}, required-interface=SendLINR_AirHeatrPwrTgt
      SendLINR_AirHeatrEnad: nonqueued-receiver-com-spec{data-element=SendLINR_AirHeatrEnad, init-value=SendLINR_AirHeatrEnadValue:0}, required-interface=SendLINR_AirHeatrEnad
      SendLINR_EOPA_RPM_COM: nonqueued-receiver-com-spec{data-element=SendLINR_EOPA_RPM_COM, init-value=SendLINR_EOPA_RPM_COMValue:6120}, required-interface=SendLINR_EOPA_RPM_COM
      SendLINR_EOPA_POST_RUN_COM: nonqueued-receiver-com-spec{data-element=SendLINR_EOPA_POST_RUN_COM, init-value=SendLINR_EOPA_POST_RUN_COMValue:7}, required-interface=SendLINR_EOPA_POST_RUN_COM
      SendLINR_LTRBV_PosRq: nonqueued-receiver-com-spec{data-element=SendLINR_LTRBV_PosRq, init-value=SendLINR_LTRBV_PosRqValue:0}, required-interface=SendLINR_LTRBV_PosRq
      SendLINR_LTRBV_PosSv: nonqueued-receiver-com-spec{data-element=SendLINR_LTRBV_PosSv, init-value=SendLINR_LTRBV_PosSvValue:0}, required-interface=SendLINR_LTRBV_PosSv
      SendLINR_LTRBV_CalRq: nonqueued-receiver-com-spec{data-element=SendLINR_LTRBV_CalRq, init-value=SendLINR_LTRBV_CalRqValue:0}, required-interface=SendLINR_LTRBV_CalRq
      SignalLINR_AAD_RdyForSleep: nonqueued-receiver-com-spec{data-element=SignalLINR_AAD_RdyForSleep, init-value=SignalLINR_AAD_RdyForSleepValue:0}, required-interface=SignalLINR_AAD_RdyForSleep
      SignalLINR_BCP_RdyForSleep: nonqueued-receiver-com-spec{data-element=SignalLINR_BCP_RdyForSleep, init-value=SignalLINR_BCP_RdyForSleepValue:0}, required-interface=SignalLINR_BCP_RdyForSleep
      SignalLINR_CPV_RdyForSleep: nonqueued-receiver-com-spec{data-element=SignalLINR_CPV_RdyForSleep, init-value=SignalLINR_CPV_RdyForSleepValue:0}, required-interface=SignalLINR_CPV_RdyForSleep
      SignalLINR_EAH_RdyForSleep: nonqueued-receiver-com-spec{data-element=SignalLINR_EAH_RdyForSleep, init-value=SignalLINR_EAH_RdyForSleepValue:0}, required-interface=SignalLINR_EAH_RdyForSleep
      SignalLINR_EEXV_RdyForSleep: nonqueued-receiver-com-spec{data-element=SignalLINR_EEXV_RdyForSleep, init-value=SignalLINR_EEXV_RdyForSleepValue:0}, required-interface=SignalLINR_EEXV_RdyForSleep
      SignalLINR_EOPA_RdyForSleep: nonqueued-receiver-com-spec{data-element=SignalLINR_EOPA_RdyForSleep, init-value=SignalLINR_EOPA_RdyForSleepValue:0}, required-interface=SignalLINR_EOPA_RdyForSleep
      SignalLINR_LTRBV_RdyForSleep: nonqueued-receiver-com-spec{data-element=SignalLINR_LTRBV_RdyForSleep, init-value=SignalLINR_LTRBV_RdyForSleepValue:0}, required-interface=SignalLINR_LTRBV_RdyForSleep
      KeCFGR_b_AAD_Equid: parameter-require-com-spec{init-value=Value:0, parameter=KeCFGR_b_AAD_Equid}, required-interface=KeCFGR_b_AAD_Equid
      KeCFGR_b_BCP_Equid: parameter-require-com-spec{init-value=Value:0, parameter=KeCFGR_b_BCP_Equid}, required-interface=KeCFGR_b_BCP_Equid
      KeCFGR_b_CPV_Equid: parameter-require-com-spec{init-value=Value:0, parameter=KeCFGR_b_CPV_Equid}, required-interface=KeCFGR_b_CPV_Equid
      KeCFGR_b_EAH_Equid: parameter-require-com-spec{init-value=Value:0, parameter=KeCFGR_b_EAH_Equid}, required-interface=KeCFGR_b_EAH_Equid
      KeCFGR_b_EEXV_Equid: parameter-require-com-spec{init-value=Value:0, parameter=KeCFGR_b_EEXV_Equid}, required-interface=KeCFGR_b_EEXV_Equid
      KeCFGR_b_EOPA_Equid: parameter-require-com-spec{init-value=Value:0, parameter=KeCFGR_b_EOPA_Equid}, required-interface=KeCFGR_b_EOPA_Equid
      KeCFGR_b_LTRBV_Equid: parameter-require-com-spec{init-value=Value:0, parameter=KeCFGR_b_LTRBV_Equid}, required-interface=KeCFGR_b_LTRBV_Equid
      KeLINR_y_LIN1SwtSchdTbl: parameter-require-com-spec{init-value=Value:0, parameter=KeLINR_y_LIN1SwtSchdTbl}, required-interface=KeLINR_y_LIN1SwtSchdTbl
    148 x provide port:
      ApplLinComAbLin1EquidMN: mode-switch-sender-com-spec{mode-group=MDGP_MSI_Lin1Equid, queue-length=1}, provided-interface=MSI_Lin1Equid
      VeLINR_d_LIN_SlavePrsntSts_LIN1: nonqueued-sender-com-spec{data-element=VeLINR_d_LIN_SlavePrsntSts_LIN1, init-value=Value:0}, provided-interface=VeLINR_d_LIN_SlavePrsntSts_LIN1
      VeLINR_e_AAD_CurrPos: nonqueued-sender-com-spec{data-element=VeLINR_e_AAD_CurrPos, init-value=VeLINR_e_AAD_CurrPosValue:15}, provided-interface=VeLINR_e_AAD_CurrPos
      VeLINR_b_AAD_CurrPosTO: nonqueued-sender-com-spec{data-element=VeLINR_b_AAD_CurrPosTO, init-value=VeLINR_b_AAD_CurrPosTOValue:0}, provided-interface=VeLINR_b_AAD_CurrPosTO
      VeLINR_b_AAD_CalStat: nonqueued-sender-com-spec{data-element=VeLINR_b_AAD_CalStat, init-value=VeLINR_b_AAD_CalStatValue:0}, provided-interface=VeLINR_b_AAD_CalStat
      VeLINR_b_AAD_CalStatTO: nonqueued-sender-com-spec{data-element=VeLINR_b_AAD_CalStatTO, init-value=VeLINR_b_AAD_CalStatTOValue:0}, provided-interface=VeLINR_b_AAD_CalStatTO
      VeLINR_b_AAD_CalActv: nonqueued-sender-com-spec{data-element=VeLINR_b_AAD_CalActv, init-value=VeLINR_b_AAD_CalActvValue:0}, provided-interface=VeLINR_b_AAD_CalActv
      VeLINR_b_AAD_CalActvTO: nonqueued-sender-com-spec{data-element=VeLINR_b_AAD_CalActvTO, init-value=VeLINR_b_AAD_CalActvTOValue:0}, provided-interface=VeLINR_b_AAD_CalActvTO
      VeLINR_b_AAD_ErrUnVolt: nonqueued-sender-com-spec{data-element=VeLINR_b_AAD_ErrUnVolt, init-value=VeLINR_b_AAD_ErrUnVoltValue:0}, provided-interface=VeLINR_b_AAD_ErrUnVolt
      VeLINR_b_AAD_ErrUnVoltTO: nonqueued-sender-com-spec{data-element=VeLINR_b_AAD_ErrUnVoltTO, init-value=VeLINR_b_AAD_ErrUnVoltTOValue:0}, provided-interface=VeLINR_b_AAD_ErrUnVoltTO
      VeLINR_b_AAD_ErrOvrVolt: nonqueued-sender-com-spec{data-element=VeLINR_b_AAD_ErrOvrVolt, init-value=VeLINR_b_AAD_ErrOvrVoltValue:0}, provided-interface=VeLINR_b_AAD_ErrOvrVolt
      VeLINR_b_AAD_ErrOvrVoltTO: nonqueued-sender-com-spec{data-element=VeLINR_b_AAD_ErrOvrVoltTO, init-value=VeLINR_b_AAD_ErrOvrVoltTOValue:0}, provided-interface=VeLINR_b_AAD_ErrOvrVoltTO
      VeLINR_b_AAD_ErrOvrTemp: nonqueued-sender-com-spec{data-element=VeLINR_b_AAD_ErrOvrTemp, init-value=VeLINR_b_AAD_ErrOvrTempValue:0}, provided-interface=VeLINR_b_AAD_ErrOvrTemp
      VeLINR_b_AAD_ErrOvrTempTO: nonqueued-sender-com-spec{data-element=VeLINR_b_AAD_ErrOvrTempTO, init-value=VeLINR_b_AAD_ErrOvrTempTOValue:0}, provided-interface=VeLINR_b_AAD_ErrOvrTempTO
      VeLINR_b_AAD_ErrMechStuck: nonqueued-sender-com-spec{data-element=VeLINR_b_AAD_ErrMechStuck, init-value=VeLINR_b_AAD_ErrMechStuckValue:0}, provided-interface=VeLINR_b_AAD_ErrMechStuck
      VeLINR_b_AAD_ErrMechStuckTO: nonqueued-sender-com-spec{data-element=VeLINR_b_AAD_ErrMechStuckTO, init-value=VeLINR_b_AAD_ErrMechStuckTOValue:0}, provided-interface=VeLINR_b_AAD_ErrMechStuckTO
      VeLINR_b_AAD_ErrMechBreak: nonqueued-sender-com-spec{data-element=VeLINR_b_AAD_ErrMechBreak, init-value=VeLINR_b_AAD_ErrMechBreakValue:0}, provided-interface=VeLINR_b_AAD_ErrMechBreak
      VeLINR_b_AAD_ErrMechBreakTO: nonqueued-sender-com-spec{data-element=VeLINR_b_AAD_ErrMechBreakTO, init-value=VeLINR_b_AAD_ErrMechBreakTOValue:0}, provided-interface=VeLINR_b_AAD_ErrMechBreakTO
      VeLINR_b_RsErr_AAD: nonqueued-sender-com-spec{data-element=VeLINR_b_RsErr_AAD, init-value=VeLINR_b_RsErr_AADValue:0}, provided-interface=VeLINR_b_RsErr_AAD
      VeLINR_b_RsErr_AAD_TO: nonqueued-sender-com-spec{data-element=VeLINR_b_RsErr_AAD_TO, init-value=VeLINR_b_RsErr_AAD_TOValue:0}, provided-interface=VeLINR_b_RsErr_AAD_TO
      VeLINR_Pct_BCP_RPM_TARGET: nonqueued-sender-com-spec{data-element=VeLINR_Pct_BCP_RPM_TARGET, init-value=VeLINR_Pct_BCP_RPM_TARGETValue:100.3935}, provided-interface=VeLINR_Pct_BCP_RPM_TARGET
      VeLINR_b_BCP_RPM_TARGET_TO: nonqueued-sender-com-spec{data-element=VeLINR_b_BCP_RPM_TARGET_TO, init-value=VeLINR_b_BCP_RPM_TARGET_TOValue:0}, provided-interface=VeLINR_b_BCP_RPM_TARGET_TO
      VeLINR_Pct_BCP_RPM_ACTUAL: nonqueued-sender-com-spec{data-element=VeLINR_Pct_BCP_RPM_ACTUAL, init-value=VeLINR_Pct_BCP_RPM_ACTUALValue:100.3935}, provided-interface=VeLINR_Pct_BCP_RPM_ACTUAL
      VeLINR_b_BCP_RPM_ACTUAL_TO: nonqueued-sender-com-spec{data-element=VeLINR_b_BCP_RPM_ACTUAL_TO, init-value=VeLINR_b_BCP_RPM_ACTUAL_TOValue:0}, provided-interface=VeLINR_b_BCP_RPM_ACTUAL_TO
      VeLINR_U_BCP_VLTG: nonqueued-sender-com-spec{data-element=VeLINR_U_BCP_VLTG, init-value=VeLINR_U_BCP_VLTGValue:25.5}, provided-interface=VeLINR_U_BCP_VLTG
      VeLINR_b_BCP_VLTG_TO: nonqueued-sender-com-spec{data-element=VeLINR_b_BCP_VLTG_TO, init-value=VeLINR_b_BCP_VLTG_TOValue:0}, provided-interface=VeLINR_b_BCP_VLTG_TO
      VeLINR_T_BCP_TEMP: nonqueued-sender-com-spec{data-element=VeLINR_T_BCP_TEMP, init-value=VeLINR_T_BCP_TEMPValue:205}, provided-interface=VeLINR_T_BCP_TEMP
      VeLINR_b_BCP_TEMP_TO: nonqueued-sender-com-spec{data-element=VeLINR_b_BCP_TEMP_TO, init-value=VeLINR_b_BCP_TEMP_TOValue:0}, provided-interface=VeLINR_b_BCP_TEMP_TO
      VeLINR_I_BCP_CURR: nonqueued-sender-com-spec{data-element=VeLINR_I_BCP_CURR, init-value=VeLINR_I_BCP_CURRValue:51}, provided-interface=VeLINR_I_BCP_CURR
      VeLINR_b_BCP_CURR_TO: nonqueued-sender-com-spec{data-element=VeLINR_b_BCP_CURR_TO, init-value=VeLINR_b_BCP_CURR_TOValue:0}, provided-interface=VeLINR_b_BCP_CURR_TO
      VeLINR_e_BCP_FL_SAFE_ACTVTD: nonqueued-sender-com-spec{data-element=VeLINR_e_BCP_FL_SAFE_ACTVTD, init-value=VeLINR_e_BCP_FL_SAFE_ACTVTDValue:3}, provided-interface=VeLINR_e_BCP_FL_SAFE_ACTVTD
      VeLINR_b_BCP_FL_SAFE_ACTVTD_TO: nonqueued-sender-com-spec{data-element=VeLINR_b_BCP_FL_SAFE_ACTVTD_TO, init-value=VeLINR_b_BCP_FL_SAFE_ACTVTD_TOValue:0}, provided-interface=VeLINR_b_BCP_FL_SAFE_ACTVTD_TO
      VeLINR_e_BCP_LMP_HM_AN_ON: nonqueued-sender-com-spec{data-element=VeLINR_e_BCP_LMP_HM_AN_ON, init-value=VeLINR_e_BCP_LMP_HM_AN_ONValue:3}, provided-interface=VeLINR_e_BCP_LMP_HM_AN_ON
      VeLINR_b_BCP_LMP_HM_AN_ON_TO: nonqueued-sender-com-spec{data-element=VeLINR_b_BCP_LMP_HM_AN_ON_TO, init-value=VeLINR_b_BCP_LMP_HM_AN_ON_TOValue:0}, provided-interface=VeLINR_b_BCP_LMP_HM_AN_ON_TO
      VeLINR_e_BCP_AIR_PRE_ERR: nonqueued-sender-com-spec{data-element=VeLINR_e_BCP_AIR_PRE_ERR, init-value=VeLINR_e_BCP_AIR_PRE_ERRValue:3}, provided-interface=VeLINR_e_BCP_AIR_PRE_ERR
      VeLINR_b_BCP_AIR_PRE_ERR_TO: nonqueued-sender-com-spec{data-element=VeLINR_b_BCP_AIR_PRE_ERR_TO, init-value=VeLINR_b_BCP_AIR_PRE_ERR_TOValue:0}, provided-interface=VeLINR_b_BCP_AIR_PRE_ERR_TO
      VeLINR_e_BCP_OVR_TMP_ERR: nonqueued-sender-com-spec{data-element=VeLINR_e_BCP_OVR_TMP_ERR, init-value=VeLINR_e_BCP_OVR_TMP_ERRValue:3}, provided-interface=VeLINR_e_BCP_OVR_TMP_ERR
      VeLINR_b_BCP_OVR_TMP_ERR_TO: nonqueued-sender-com-spec{data-element=VeLINR_b_BCP_OVR_TMP_ERR_TO, init-value=VeLINR_b_BCP_OVR_TMP_ERR_TOValue:0}, provided-interface=VeLINR_b_BCP_OVR_TMP_ERR_TO
      VeLINR_e_BCP_OVR_CUR_ERR: nonqueued-sender-com-spec{data-element=VeLINR_e_BCP_OVR_CUR_ERR, init-value=VeLINR_e_BCP_OVR_CUR_ERRValue:3}, provided-interface=VeLINR_e_BCP_OVR_CUR_ERR
      VeLINR_b_BCP_OVR_CUR_ERR_TO: nonqueued-sender-com-spec{data-element=VeLINR_b_BCP_OVR_CUR_ERR_TO, init-value=VeLINR_b_BCP_OVR_CUR_ERR_TOValue:0}, provided-interface=VeLINR_b_BCP_OVR_CUR_ERR_TO
      VeLINR_e_BCP_DR_RN_ERR: nonqueued-sender-com-spec{data-element=VeLINR_e_BCP_DR_RN_ERR, init-value=VeLINR_e_BCP_DR_RN_ERRValue:3}, provided-interface=VeLINR_e_BCP_DR_RN_ERR
      VeLINR_b_BCP_DR_RN_ERR_TO: nonqueued-sender-com-spec{data-element=VeLINR_b_BCP_DR_RN_ERR_TO, init-value=VeLINR_b_BCP_DR_RN_ERR_TOValue:0}, provided-interface=VeLINR_b_BCP_DR_RN_ERR_TO
      VeLINR_e_BCP_VLTG_ERR: nonqueued-sender-com-spec{data-element=VeLINR_e_BCP_VLTG_ERR, init-value=VeLINR_e_BCP_VLTG_ERRValue:3}, provided-interface=VeLINR_e_BCP_VLTG_ERR
      VeLINR_b_BCP_VLTG_ERR_TO: nonqueued-sender-com-spec{data-element=VeLINR_b_BCP_VLTG_ERR_TO, init-value=VeLINR_b_BCP_VLTG_ERR_TOValue:0}, provided-interface=VeLINR_b_BCP_VLTG_ERR_TO
      VeLINR_e_BCP_DBLK_ACTV: nonqueued-sender-com-spec{data-element=VeLINR_e_BCP_DBLK_ACTV, init-value=VeLINR_e_BCP_DBLK_ACTVValue:3}, provided-interface=VeLINR_e_BCP_DBLK_ACTV
      VeLINR_b_BCP_DBLK_ACTV_TO: nonqueued-sender-com-spec{data-element=VeLINR_b_BCP_DBLK_ACTV_TO, init-value=VeLINR_b_BCP_DBLK_ACTV_TOValue:0}, provided-interface=VeLINR_b_BCP_DBLK_ACTV_TO
      VeLINR_e_BCP_MONTRNG_RPM: nonqueued-sender-com-spec{data-element=VeLINR_e_BCP_MONTRNG_RPM, init-value=VeLINR_e_BCP_MONTRNG_RPMValue:3}, provided-interface=VeLINR_e_BCP_MONTRNG_RPM
      VeLINR_b_BCP_MONTRNG_RPM_TO: nonqueued-sender-com-spec{data-element=VeLINR_b_BCP_MONTRNG_RPM_TO, init-value=VeLINR_b_BCP_MONTRNG_RPM_TOValue:0}, provided-interface=VeLINR_b_BCP_MONTRNG_RPM_TO
      VeLINR_e_BCP_NODE_ERR: nonqueued-sender-com-spec{data-element=VeLINR_e_BCP_NODE_ERR, init-value=VeLINR_e_BCP_NODE_ERRValue:3}, provided-interface=VeLINR_e_BCP_NODE_ERR
      VeLINR_b_BCP_NODE_ERR_TO: nonqueued-sender-com-spec{data-element=VeLINR_b_BCP_NODE_ERR_TO, init-value=VeLINR_b_BCP_NODE_ERR_TOValue:0}, provided-interface=VeLINR_b_BCP_NODE_ERR_TO
      VeLINR_e_BCP_POST_RUN_STAT: nonqueued-sender-com-spec{data-element=VeLINR_e_BCP_POST_RUN_STAT, init-value=VeLINR_e_BCP_POST_RUN_STATValue:7}, provided-interface=VeLINR_e_BCP_POST_RUN_STAT
      VeLINR_b_BCP_POST_RUN_STAT_TO: nonqueued-sender-com-spec{data-element=VeLINR_b_BCP_POST_RUN_STAT_TO, init-value=VeLINR_b_BCP_POST_RUN_STAT_TOValue:0}, provided-interface=VeLINR_b_BCP_POST_RUN_STAT_TO
      VeLINR_b_RsErr_BCP_PUMP: nonqueued-sender-com-spec{data-element=VeLINR_b_RsErr_BCP_PUMP, init-value=VeLINR_b_RsErr_BCP_PUMPValue:0}, provided-interface=VeLINR_b_RsErr_BCP_PUMP
      VeLINR_b_RsErr_BCP_PUMP_TO: nonqueued-sender-com-spec{data-element=VeLINR_b_RsErr_BCP_PUMP_TO, init-value=VeLINR_b_RsErr_BCP_PUMP_TOValue:0}, provided-interface=VeLINR_b_RsErr_BCP_PUMP_TO
      VeLINR_y_BCP_VERSION: nonqueued-sender-com-spec{data-element=VeLINR_y_BCP_VERSION, init-value=VeLINR_y_BCP_VERSIONValue:255}, provided-interface=VeLINR_y_BCP_VERSION
      VeLINR_b_BCP_VERSION_TO: nonqueued-sender-com-spec{data-element=VeLINR_b_BCP_VERSION_TO, init-value=VeLINR_b_BCP_VERSION_TOValue:0}, provided-interface=VeLINR_b_BCP_VERSION_TO
      VeLINR_e_BCP_SUPPLIER: nonqueued-sender-com-spec{data-element=VeLINR_e_BCP_SUPPLIER, init-value=VeLINR_e_BCP_SUPPLIERValue:0}, provided-interface=VeLINR_e_BCP_SUPPLIER
      VeLINR_b_BCP_SUPPLIER_TO: nonqueued-sender-com-spec{data-element=VeLINR_b_BCP_SUPPLIER_TO, init-value=VeLINR_b_BCP_SUPPLIER_TOValue:0}, provided-interface=VeLINR_b_BCP_SUPPLIER_TO
      VeLINR_Pct_CPV_PosAct: nonqueued-sender-com-spec{data-element=VeLINR_Pct_CPV_PosAct, init-value=VeLINR_Pct_CPV_PosActValue:0}, provided-interface=VeLINR_Pct_CPV_PosAct
      VeLINR_b_CPV_PosActTO: nonqueued-sender-com-spec{data-element=VeLINR_b_CPV_PosActTO, init-value=VeLINR_b_CPV_PosActTOValue:0}, provided-interface=VeLINR_b_CPV_PosActTO
      VeLINR_e_CPV_ERR: nonqueued-sender-com-spec{data-element=VeLINR_e_CPV_ERR, init-value=VeLINR_e_CPV_ERRValue:0}, provided-interface=VeLINR_e_CPV_ERR
      VeLINR_b_CPV_ERR_TO: nonqueued-sender-com-spec{data-element=VeLINR_b_CPV_ERR_TO, init-value=VeLINR_b_CPV_ERR_TOValue:0}, provided-interface=VeLINR_b_CPV_ERR_TO
      VeLINR_e_CPV_Sts: nonqueued-sender-com-spec{data-element=VeLINR_e_CPV_Sts, init-value=VeLINR_e_CPV_StsValue:0}, provided-interface=VeLINR_e_CPV_Sts
      VeLINR_b_CPV_StsTO: nonqueued-sender-com-spec{data-element=VeLINR_b_CPV_StsTO, init-value=VeLINR_b_CPV_StsTOValue:0}, provided-interface=VeLINR_b_CPV_StsTO
      VeLINR_b_RsErr_CPV: nonqueued-sender-com-spec{data-element=VeLINR_b_RsErr_CPV, init-value=VeLINR_b_RsErr_CPVValue:0}, provided-interface=VeLINR_b_RsErr_CPV
      VeLINR_b_RsErr_CPV_TO: nonqueued-sender-com-spec{data-element=VeLINR_b_RsErr_CPV_TO, init-value=VeLINR_b_RsErr_CPV_TOValue:0}, provided-interface=VeLINR_b_RsErr_CPV_TO
      VeLINR_I_AirHeatrICns: nonqueued-sender-com-spec{data-element=VeLINR_I_AirHeatrICns, init-value=VeLINR_I_AirHeatrICnsValue:63.75}, provided-interface=VeLINR_I_AirHeatrICns
      VeLINR_b_AirHeatrICnsTO: nonqueued-sender-com-spec{data-element=VeLINR_b_AirHeatrICnsTO, init-value=VeLINR_b_AirHeatrICnsTOValue:0}, provided-interface=VeLINR_b_AirHeatrICnsTO
      VeLINR_U_AirHeatrHVmeas: nonqueued-sender-com-spec{data-element=VeLINR_U_AirHeatrHVmeas, init-value=VeLINR_U_AirHeatrHVmeasValue:1023}, provided-interface=VeLINR_U_AirHeatrHVmeas
      VeLINR_b_AirHeatrHVmeasTO: nonqueued-sender-com-spec{data-element=VeLINR_b_AirHeatrHVmeasTO, init-value=VeLINR_b_AirHeatrHVmeasTOValue:0}, provided-interface=VeLINR_b_AirHeatrHVmeasTO
      VeLINR_T_AirHeatrPCBTemp: nonqueued-sender-com-spec{data-element=VeLINR_T_AirHeatrPCBTemp, init-value=VeLINR_T_AirHeatrPCBTempValue:215}, provided-interface=VeLINR_T_AirHeatrPCBTemp
      VeLINR_b_AirHeatrPCBTempTO: nonqueued-sender-com-spec{data-element=VeLINR_b_AirHeatrPCBTempTO, init-value=VeLINR_b_AirHeatrPCBTempTOValue:0}, provided-interface=VeLINR_b_AirHeatrPCBTempTO
      VeLINR_T_AirHeatrCoreTemp: nonqueued-sender-com-spec{data-element=VeLINR_T_AirHeatrCoreTemp, init-value=VeLINR_T_AirHeatrCoreTempValue:215}, provided-interface=VeLINR_T_AirHeatrCoreTemp
      VeLINR_b_AirHeatrCoreTempTO: nonqueued-sender-com-spec{data-element=VeLINR_b_AirHeatrCoreTempTO, init-value=VeLINR_b_AirHeatrCoreTempTOValue:0}, provided-interface=VeLINR_b_AirHeatrCoreTempTO
      VeLINR_b_RsErr_EAH: nonqueued-sender-com-spec{data-element=VeLINR_b_RsErr_EAH, init-value=VeLINR_b_RsErr_EAHValue:0}, provided-interface=VeLINR_b_RsErr_EAH
      VeLINR_b_RsErr_EAH_TO: nonqueued-sender-com-spec{data-element=VeLINR_b_RsErr_EAH_TO, init-value=VeLINR_b_RsErr_EAH_TOValue:0}, provided-interface=VeLINR_b_RsErr_EAH_TO
      VeLINR_e_AirHeatrWarnFltInCom: nonqueued-sender-com-spec{data-element=VeLINR_e_AirHeatrWarnFltInCom, init-value=VeLINR_e_AirHeatrWarnFltInComValue:3}, provided-interface=VeLINR_e_AirHeatrWarnFltInCom
      VeLINR_b_AirHeatrWarnFltInComTO: nonqueued-sender-com-spec{data-element=VeLINR_b_AirHeatrWarnFltInComTO, init-value=VeLINR_b_AirHeatrWarnFltInComTOValue:0}, provided-interface=VeLINR_b_AirHeatrWarnFltInComTO
      VeLINR_e_AirHeatrWarnHvOutOfRng: nonqueued-sender-com-spec{data-element=VeLINR_e_AirHeatrWarnHvOutOfRng, init-value=VeLINR_e_AirHeatrWarnHvOutOfRngValue:3}, provided-interface=VeLINR_e_AirHeatrWarnHvOutOfRng
      VeLINR_b_AirHeatrWarnHvOutOfRngTO: nonqueued-sender-com-spec{data-element=VeLINR_b_AirHeatrWarnHvOutOfRngTO, init-value=VeLINR_b_AirHeatrWarnHvOutOfRngTOValue:0}, provided-interface=VeLINR_b_AirHeatrWarnHvOutOfRngTO
      VeLINR_e_AirHtrWarnULoOutOfRng: nonqueued-sender-com-spec{data-element=VeLINR_e_AirHtrWarnULoOutOfRng, init-value=VeLINR_e_AirHtrWarnULoOutOfRngValue:3}, provided-interface=VeLINR_e_AirHtrWarnULoOutOfRng
      VeLINR_b_AirHtrWarnULoOutOfRngTO: nonqueued-sender-com-spec{data-element=VeLINR_b_AirHtrWarnULoOutOfRngTO, init-value=VeLINR_b_AirHtrWarnULoOutOfRngTOValue:0}, provided-interface=VeLINR_b_AirHtrWarnULoOutOfRngTO
      VeLINR_e_AirHtrWarnTmpOvrheatg: nonqueued-sender-com-spec{data-element=VeLINR_e_AirHtrWarnTmpOvrheatg, init-value=VeLINR_e_AirHtrWarnTmpOvrheatgValue:3}, provided-interface=VeLINR_e_AirHtrWarnTmpOvrheatg
      VeLINR_b_AirHtrWarnTmpOvrheatgTO: nonqueued-sender-com-spec{data-element=VeLINR_b_AirHtrWarnTmpOvrheatgTO, init-value=VeLINR_b_AirHtrWarnTmpOvrheatgTOValue:0}, provided-interface=VeLINR_b_AirHtrWarnTmpOvrheatgTO
      VeLINR_e_AirHtrWarnICnsOutOfRng: nonqueued-sender-com-spec{data-element=VeLINR_e_AirHtrWarnICnsOutOfRng, init-value=VeLINR_e_AirHtrWarnICnsOutOfRngValue:3}, provided-interface=VeLINR_e_AirHtrWarnICnsOutOfRng
      VeLINR_b_AirHtrWarnICnsOutOfRngTO: nonqueued-sender-com-spec{data-element=VeLINR_b_AirHtrWarnICnsOutOfRngTO, init-value=VeLINR_b_AirHtrWarnICnsOutOfRngTOValue:0}, provided-interface=VeLINR_b_AirHtrWarnICnsOutOfRngTO
      VeLINR_e_AirHeatrDmgIntHwProtn: nonqueued-sender-com-spec{data-element=VeLINR_e_AirHeatrDmgIntHwProtn, init-value=VeLINR_e_AirHeatrDmgIntHwProtnValue:3}, provided-interface=VeLINR_e_AirHeatrDmgIntHwProtn
      VeLINR_b_AirHeatrDmgIntHwProtnTO: nonqueued-sender-com-spec{data-element=VeLINR_b_AirHeatrDmgIntHwProtnTO, init-value=VeLINR_b_AirHeatrDmgIntHwProtnTOValue:0}, provided-interface=VeLINR_b_AirHeatrDmgIntHwProtnTO
      VeLINR_e_AirHtrDmgPCBTmpSnsrFlt: nonqueued-sender-com-spec{data-element=VeLINR_e_AirHtrDmgPCBTmpSnsrFlt, init-value=VeLINR_e_AirHtrDmgPCBTmpSnsrFltValue:3}, provided-interface=VeLINR_e_AirHtrDmgPCBTmpSnsrFlt
      VeLINR_b_AirHtrDmgPCBTmpSnsrFltTO: nonqueued-sender-com-spec{data-element=VeLINR_b_AirHtrDmgPCBTmpSnsrFltTO, init-value=VeLINR_b_AirHtrDmgPCBTmpSnsrFltTOValue:0}, provided-interface=VeLINR_b_AirHtrDmgPCBTmpSnsrFltTO
      VeLINR_e_AirHtrDmgCirDrvrShoOpn: nonqueued-sender-com-spec{data-element=VeLINR_e_AirHtrDmgCirDrvrShoOpn, init-value=VeLINR_e_AirHtrDmgCirDrvrShoOpnValue:3}, provided-interface=VeLINR_e_AirHtrDmgCirDrvrShoOpn
      VeLINR_b_AirHtrDmgCirDrvrShoOpnTO: nonqueued-sender-com-spec{data-element=VeLINR_b_AirHtrDmgCirDrvrShoOpnTO, init-value=VeLINR_b_AirHtrDmgCirDrvrShoOpnTOValue:0}, provided-interface=VeLINR_b_AirHtrDmgCirDrvrShoOpnTO
      VeLINR_e_AirHeatrDmgHVISnsrFlt: nonqueued-sender-com-spec{data-element=VeLINR_e_AirHeatrDmgHVISnsrFlt, init-value=VeLINR_e_AirHeatrDmgHVISnsrFltValue:3}, provided-interface=VeLINR_e_AirHeatrDmgHVISnsrFlt
      VeLINR_b_AirHeatrDmgHVISnsrFltTO: nonqueued-sender-com-spec{data-element=VeLINR_b_AirHeatrDmgHVISnsrFltTO, init-value=VeLINR_b_AirHeatrDmgHVISnsrFltTOValue:0}, provided-interface=VeLINR_b_AirHeatrDmgHVISnsrFltTO
      VeLINR_e_AirHeatrDmgMemErr: nonqueued-sender-com-spec{data-element=VeLINR_e_AirHeatrDmgMemErr, init-value=VeLINR_e_AirHeatrDmgMemErrValue:3}, provided-interface=VeLINR_e_AirHeatrDmgMemErr
      VeLINR_b_AirHeatrDmgMemErrTO: nonqueued-sender-com-spec{data-element=VeLINR_b_AirHeatrDmgMemErrTO, init-value=VeLINR_b_AirHeatrDmgMemErrTOValue:0}, provided-interface=VeLINR_b_AirHeatrDmgMemErrTO
      VeLINR_e_AirHtrDmgHtrCorTS_Flt: nonqueued-sender-com-spec{data-element=VeLINR_e_AirHtrDmgHtrCorTS_Flt, init-value=VeLINR_e_AirHtrDmgHtrCorTS_FltValue:3}, provided-interface=VeLINR_e_AirHtrDmgHtrCorTS_Flt
      VeLINR_b_AirHtrDmgHtrCorTS_FltTO: nonqueued-sender-com-spec{data-element=VeLINR_b_AirHtrDmgHtrCorTS_FltTO, init-value=VeLINR_b_AirHtrDmgHtrCorTS_FltTOValue:0}, provided-interface=VeLINR_b_AirHtrDmgHtrCorTS_FltTO
      VeLINR_e_AirHeatrWarnPCBOvrTmp: nonqueued-sender-com-spec{data-element=VeLINR_e_AirHeatrWarnPCBOvrTmp, init-value=VeLINR_e_AirHeatrWarnPCBOvrTmpValue:3}, provided-interface=VeLINR_e_AirHeatrWarnPCBOvrTmp
      VeLINR_b_AirHeatrWarnPCBOvrTmpTO: nonqueued-sender-com-spec{data-element=VeLINR_b_AirHeatrWarnPCBOvrTmpTO, init-value=VeLINR_b_AirHeatrWarnPCBOvrTmpTOValue:0}, provided-interface=VeLINR_b_AirHeatrWarnPCBOvrTmpTO
      VeLINR_e_AirHtrWrnHtrCorOvrTmp: nonqueued-sender-com-spec{data-element=VeLINR_e_AirHtrWrnHtrCorOvrTmp, init-value=VeLINR_e_AirHtrWrnHtrCorOvrTmpValue:3}, provided-interface=VeLINR_e_AirHtrWrnHtrCorOvrTmp
      VeLINR_b_AirHtrWrnHtrCorOvrTmpTO: nonqueued-sender-com-spec{data-element=VeLINR_b_AirHtrWrnHtrCorOvrTmpTO, init-value=VeLINR_b_AirHtrWrnHtrCorOvrTmpTOValue:0}, provided-interface=VeLINR_b_AirHtrWrnHtrCorOvrTmpTO
      VeLINR_e_EOPA_RPM_TGT: nonqueued-sender-com-spec{data-element=VeLINR_e_EOPA_RPM_TGT, init-value=VeLINR_e_EOPA_RPM_TGTValue:6120}, provided-interface=VeLINR_e_EOPA_RPM_TGT
      VeLINR_b_EOPA_RPM_TGT_TO: nonqueued-sender-com-spec{data-element=VeLINR_b_EOPA_RPM_TGT_TO, init-value=VeLINR_b_EOPA_RPM_TGT_TOValue:0}, provided-interface=VeLINR_b_EOPA_RPM_TGT_TO
      VeLINR_e_EOPA_RPM_ACTL: nonqueued-sender-com-spec{data-element=VeLINR_e_EOPA_RPM_ACTL, init-value=VeLINR_e_EOPA_RPM_ACTLValue:6120}, provided-interface=VeLINR_e_EOPA_RPM_ACTL
      VeLINR_b_EOPA_RPM_ACTL_TO: nonqueued-sender-com-spec{data-element=VeLINR_b_EOPA_RPM_ACTL_TO, init-value=VeLINR_b_EOPA_RPM_ACTL_TOValue:0}, provided-interface=VeLINR_b_EOPA_RPM_ACTL_TO
      VeLINR_U_EOPA_VLTG: nonqueued-sender-com-spec{data-element=VeLINR_U_EOPA_VLTG, init-value=VeLINR_U_EOPA_VLTGValue:25.5}, provided-interface=VeLINR_U_EOPA_VLTG
      VeLINR_b_EOPA_VLTG_TO: nonqueued-sender-com-spec{data-element=VeLINR_b_EOPA_VLTG_TO, init-value=VeLINR_b_EOPA_VLTG_TOValue:0}, provided-interface=VeLINR_b_EOPA_VLTG_TO
      VeLINR_T_EOPA_TEMP: nonqueued-sender-com-spec{data-element=VeLINR_T_EOPA_TEMP, init-value=VeLINR_T_EOPA_TEMPValue:205}, provided-interface=VeLINR_T_EOPA_TEMP
      VeLINR_b_EOPA_TEMP_TO: nonqueued-sender-com-spec{data-element=VeLINR_b_EOPA_TEMP_TO, init-value=VeLINR_b_EOPA_TEMP_TOValue:0}, provided-interface=VeLINR_b_EOPA_TEMP_TO
      VeLINR_I_EOPA_CURR: nonqueued-sender-com-spec{data-element=VeLINR_I_EOPA_CURR, init-value=VeLINR_I_EOPA_CURRValue:51}, provided-interface=VeLINR_I_EOPA_CURR
      VeLINR_b_EOPA_CURR_TO: nonqueued-sender-com-spec{data-element=VeLINR_b_EOPA_CURR_TO, init-value=VeLINR_b_EOPA_CURR_TOValue:0}, provided-interface=VeLINR_b_EOPA_CURR_TO
      VeLINR_e_EOPA_LOW_TMP_STAT: nonqueued-sender-com-spec{data-element=VeLINR_e_EOPA_LOW_TMP_STAT, init-value=VeLINR_e_EOPA_LOW_TMP_STATValue:3}, provided-interface=VeLINR_e_EOPA_LOW_TMP_STAT
      VeLINR_b_EOPA_LOW_TMP_STAT_TO: nonqueued-sender-com-spec{data-element=VeLINR_b_EOPA_LOW_TMP_STAT_TO, init-value=VeLINR_b_EOPA_LOW_TMP_STAT_TOValue:0}, provided-interface=VeLINR_b_EOPA_LOW_TMP_STAT_TO
      VeLINR_e_EOPA_MONTRNG_RPM: nonqueued-sender-com-spec{data-element=VeLINR_e_EOPA_MONTRNG_RPM, init-value=VeLINR_e_EOPA_MONTRNG_RPMValue:3}, provided-interface=VeLINR_e_EOPA_MONTRNG_RPM
      VeLINR_b_EOPA_MONTRNG_RPM_TO: nonqueued-sender-com-spec{data-element=VeLINR_b_EOPA_MONTRNG_RPM_TO, init-value=VeLINR_b_EOPA_MONTRNG_RPM_TOValue:0}, provided-interface=VeLINR_b_EOPA_MONTRNG_RPM_TO
      VeLINR_e_EOPA_LMP_HM_AN_ON: nonqueued-sender-com-spec{data-element=VeLINR_e_EOPA_LMP_HM_AN_ON, init-value=VeLINR_e_EOPA_LMP_HM_AN_ONValue:3}, provided-interface=VeLINR_e_EOPA_LMP_HM_AN_ON
      VeLINR_b_EOPA_LMP_HM_AN_ON_TO: nonqueued-sender-com-spec{data-element=VeLINR_b_EOPA_LMP_HM_AN_ON_TO, init-value=VeLINR_b_EOPA_LMP_HM_AN_ON_TOValue:0}, provided-interface=VeLINR_b_EOPA_LMP_HM_AN_ON_TO
      VeLINR_e_EOPA_OV_TMP_ER: nonqueued-sender-com-spec{data-element=VeLINR_e_EOPA_OV_TMP_ER, init-value=VeLINR_e_EOPA_OV_TMP_ERValue:3}, provided-interface=VeLINR_e_EOPA_OV_TMP_ER
      VeLINR_b_EOPA_OV_TMP_ER_TO: nonqueued-sender-com-spec{data-element=VeLINR_b_EOPA_OV_TMP_ER_TO, init-value=VeLINR_b_EOPA_OV_TMP_ER_TOValue:0}, provided-interface=VeLINR_b_EOPA_OV_TMP_ER_TO
      VeLINR_e_EOPA_OV_CUR_ER: nonqueued-sender-com-spec{data-element=VeLINR_e_EOPA_OV_CUR_ER, init-value=VeLINR_e_EOPA_OV_CUR_ERValue:3}, provided-interface=VeLINR_e_EOPA_OV_CUR_ER
      VeLINR_b_EOPA_OV_CUR_ER_TO: nonqueued-sender-com-spec{data-element=VeLINR_b_EOPA_OV_CUR_ER_TO, init-value=VeLINR_b_EOPA_OV_CUR_ER_TOValue:0}, provided-interface=VeLINR_b_EOPA_OV_CUR_ER_TO
      VeLINR_e_EOPA_DR_RN_ER: nonqueued-sender-com-spec{data-element=VeLINR_e_EOPA_DR_RN_ER, init-value=VeLINR_e_EOPA_DR_RN_ERValue:3}, provided-interface=VeLINR_e_EOPA_DR_RN_ER
      VeLINR_b_EOPA_DR_RN_ER_TO: nonqueued-sender-com-spec{data-element=VeLINR_b_EOPA_DR_RN_ER_TO, init-value=VeLINR_b_EOPA_DR_RN_ER_TOValue:0}, provided-interface=VeLINR_b_EOPA_DR_RN_ER_TO
      VeLINR_e_EOPA_VLTG_ER: nonqueued-sender-com-spec{data-element=VeLINR_e_EOPA_VLTG_ER, init-value=VeLINR_e_EOPA_VLTG_ERValue:3}, provided-interface=VeLINR_e_EOPA_VLTG_ER
      VeLINR_b_EOPA_VLTG_ER_TO: nonqueued-sender-com-spec{data-element=VeLINR_b_EOPA_VLTG_ER_TO, init-value=VeLINR_b_EOPA_VLTG_ER_TOValue:0}, provided-interface=VeLINR_b_EOPA_VLTG_ER_TO
      VeLINR_e_EOPA_Stall_Event: nonqueued-sender-com-spec{data-element=VeLINR_e_EOPA_Stall_Event, init-value=VeLINR_e_EOPA_Stall_EventValue:3}, provided-interface=VeLINR_e_EOPA_Stall_Event
      VeLINR_b_EOPA_Stall_EventTO: nonqueued-sender-com-spec{data-element=VeLINR_b_EOPA_Stall_EventTO, init-value=VeLINR_b_EOPA_Stall_EventTOValue:0}, provided-interface=VeLINR_b_EOPA_Stall_EventTO
      VeLINR_e_EOPA_POST_RUN_STAT: nonqueued-sender-com-spec{data-element=VeLINR_e_EOPA_POST_RUN_STAT, init-value=VeLINR_e_EOPA_POST_RUN_STATValue:7}, provided-interface=VeLINR_e_EOPA_POST_RUN_STAT
      VeLINR_b_EOPA_POST_RUN_STAT_TO: nonqueued-sender-com-spec{data-element=VeLINR_b_EOPA_POST_RUN_STAT_TO, init-value=VeLINR_b_EOPA_POST_RUN_STAT_TOValue:0}, provided-interface=VeLINR_b_EOPA_POST_RUN_STAT_TO
      VeLINR_b_RsErr_EOPA: nonqueued-sender-com-spec{data-element=VeLINR_b_RsErr_EOPA, init-value=VeLINR_b_RsErr_EOPAValue:0}, provided-interface=VeLINR_b_RsErr_EOPA
      VeLINR_b_RsErr_EOPA_TO: nonqueued-sender-com-spec{data-element=VeLINR_b_RsErr_EOPA_TO, init-value=VeLINR_b_RsErr_EOPA_TOValue:0}, provided-interface=VeLINR_b_RsErr_EOPA_TO
      VeLINR_T_EOPA_OIL_TEMP: nonqueued-sender-com-spec{data-element=VeLINR_T_EOPA_OIL_TEMP, init-value=VeLINR_T_EOPA_OIL_TEMPValue:205}, provided-interface=VeLINR_T_EOPA_OIL_TEMP
      VeLINR_b_EOPA_OIL_TEMP_TO: nonqueued-sender-com-spec{data-element=VeLINR_b_EOPA_OIL_TEMP_TO, init-value=VeLINR_b_EOPA_OIL_TEMP_TOValue:0}, provided-interface=VeLINR_b_EOPA_OIL_TEMP_TO
      VeLINR_y_EOPA_HW_VER: nonqueued-sender-com-spec{data-element=VeLINR_y_EOPA_HW_VER, init-value=VeLINR_y_EOPA_HW_VERValue:255}, provided-interface=VeLINR_y_EOPA_HW_VER
      VeLINR_b_EOPA_HW_VER_TO: nonqueued-sender-com-spec{data-element=VeLINR_b_EOPA_HW_VER_TO, init-value=VeLINR_b_EOPA_HW_VER_TOValue:0}, provided-interface=VeLINR_b_EOPA_HW_VER_TO
      VeLINR_y_EOPA_SW_VER: nonqueued-sender-com-spec{data-element=VeLINR_y_EOPA_SW_VER, init-value=VeLINR_y_EOPA_SW_VERValue:255}, provided-interface=VeLINR_y_EOPA_SW_VER
      VeLINR_b_EOPA_SW_VER_TO: nonqueued-sender-com-spec{data-element=VeLINR_b_EOPA_SW_VER_TO, init-value=VeLINR_b_EOPA_SW_VER_TOValue:0}, provided-interface=VeLINR_b_EOPA_SW_VER_TO
      VeLINR_Pct_LTRBV_PosAct: nonqueued-sender-com-spec{data-element=VeLINR_Pct_LTRBV_PosAct, init-value=VeLINR_Pct_LTRBV_PosActValue:0}, provided-interface=VeLINR_Pct_LTRBV_PosAct
      VeLINR_b_LTRBV_PosActTO: nonqueued-sender-com-spec{data-element=VeLINR_b_LTRBV_PosActTO, init-value=VeLINR_b_LTRBV_PosActTOValue:0}, provided-interface=VeLINR_b_LTRBV_PosActTO
      VeLINR_e_LTRBV_ERR: nonqueued-sender-com-spec{data-element=VeLINR_e_LTRBV_ERR, init-value=VeLINR_e_LTRBV_ERRValue:0}, provided-interface=VeLINR_e_LTRBV_ERR
      VeLINR_b_LTRBV_ERR_TO: nonqueued-sender-com-spec{data-element=VeLINR_b_LTRBV_ERR_TO, init-value=VeLINR_b_LTRBV_ERR_TOValue:0}, provided-interface=VeLINR_b_LTRBV_ERR_TO
      VeLINR_U_LTRBV_MotorVolt: nonqueued-sender-com-spec{data-element=VeLINR_U_LTRBV_MotorVolt, init-value=VeLINR_U_LTRBV_MotorVoltValue:0}, provided-interface=VeLINR_U_LTRBV_MotorVolt
      VeLINR_b_LTRBV_MotorVoltTO: nonqueued-sender-com-spec{data-element=VeLINR_b_LTRBV_MotorVoltTO, init-value=VeLINR_b_LTRBV_MotorVoltTOValue:0}, provided-interface=VeLINR_b_LTRBV_MotorVoltTO
      VeLINR_e_LTRBV_Sts: nonqueued-sender-com-spec{data-element=VeLINR_e_LTRBV_Sts, init-value=VeLINR_e_LTRBV_StsValue:0}, provided-interface=VeLINR_e_LTRBV_Sts
      VeLINR_b_LTRBV_StsTO: nonqueued-sender-com-spec{data-element=VeLINR_b_LTRBV_StsTO, init-value=VeLINR_b_LTRBV_StsTOValue:0}, provided-interface=VeLINR_b_LTRBV_StsTO
      VeLINR_b_RsErr_LTRBV: nonqueued-sender-com-spec{data-element=VeLINR_b_RsErr_LTRBV, init-value=VeLINR_b_RsErr_LTRBVValue:0}, provided-interface=VeLINR_b_RsErr_LTRBV
      VeLINR_b_RsErr_LTRBV_TO: nonqueued-sender-com-spec{data-element=VeLINR_b_RsErr_LTRBV_TO, init-value=VeLINR_b_RsErr_LTRBV_TOValue:0}, provided-interface=VeLINR_b_RsErr_LTRBV_TO
    16 x require port:
      SendLINR_AAD_PosRqVld: nonqueued-receiver-com-spec{data-element=SendLINR_AAD_PosRqVld, init-value=SendLINR_AAD_PosRqVldValue:1}, required-interface=SendLINR_AAD_PosRqVld
      SendLINR_AAD_CalRqVld: nonqueued-receiver-com-spec{data-element=SendLINR_AAD_CalRqVld, init-value=SendLINR_AAD_CalRqVldValue:1}, required-interface=SendLINR_AAD_CalRqVld
      SendLINR_AAD_InitialIP_CalRqVld: nonqueued-receiver-com-spec{data-element=SendLINR_AAD_InitialIP_CalRqVld, init-value=1}, required-interface=SendLINR_AAD_InitialIP_CalRqVld
      SendLINR_BCP_RPM_REQ_Vld: nonqueued-receiver-com-spec{data-element=SendLINR_BCP_RPM_REQ_Vld, init-value=SendLINR_BCP_RPM_REQ_VldValue:1}, required-interface=SendLINR_BCP_RPM_REQ_Vld
      SendLINR_BCP_POST_RUN_REQ_Vld: nonqueued-receiver-com-spec{data-element=SendLINR_BCP_POST_RUN_REQ_Vld, init-value=SendLINR_BCP_POST_RUN_REQ_VldValue:1}, required-interface=SendLINR_BCP_POST_RUN_REQ_Vld
      SendLINR_BCP_FL_SAFE_ACTVT_Vld: nonqueued-receiver-com-spec{data-element=SendLINR_BCP_FL_SAFE_ACTVT_Vld, init-value=SendLINR_BCP_FL_SAFE_ACTVT_VldValue:1}, required-interface=SendLINR_BCP_FL_SAFE_ACTVT_Vld
      SendLINR_CPV_PosRqVld: nonqueued-receiver-com-spec{data-element=SendLINR_CPV_PosRqVld, init-value=SendLINR_CPV_PosRqVldValue:1}, required-interface=SendLINR_CPV_PosRqVld
      SendLINR_CPV_PosSvVld: nonqueued-receiver-com-spec{data-element=SendLINR_CPV_PosSvVld, init-value=SendLINR_CPV_PosSvVldValue:1}, required-interface=SendLINR_CPV_PosSvVld
      SendLINR_CPV_CalRqVld: nonqueued-receiver-com-spec{data-element=SendLINR_CPV_CalRqVld, init-value=SendLINR_CPV_CalRqVldValue:1}, required-interface=SendLINR_CPV_CalRqVld
      SendLINR_AirHeatrPwrTgtVld: nonqueued-receiver-com-spec{data-element=SendLINR_AirHeatrPwrTgtVld, init-value=SendLINR_AirHeatrPwrTgtVldValue:1}, required-interface=SendLINR_AirHeatrPwrTgtVld
      SendLINR_AirHeatrEnadVld: nonqueued-receiver-com-spec{data-element=SendLINR_AirHeatrEnadVld, init-value=SendLINR_AirHeatrEnadVldValue:1}, required-interface=SendLINR_AirHeatrEnadVld
      SendLINR_EOPA_RPM_COM_Vld: nonqueued-receiver-com-spec{data-element=SendLINR_EOPA_RPM_COM_Vld, init-value=SendLINR_EOPA_RPM_COM_VldValue:1}, required-interface=SendLINR_EOPA_RPM_COM_Vld
      SendLINR_EOPA_POST_RUN_COM_Vld: nonqueued-receiver-com-spec{data-element=SendLINR_EOPA_POST_RUN_COM_Vld, init-value=SendLINR_EOPA_POST_RUN_COM_VldValue:1}, required-interface=SendLINR_EOPA_POST_RUN_COM_Vld
      SendLINR_LTRBV_PosRqVld: nonqueued-receiver-com-spec{data-element=SendLINR_LTRBV_PosRqVld, init-value=SendLINR_LTRBV_PosRqVldValue:1}, required-interface=SendLINR_LTRBV_PosRqVld
      SendLINR_LTRBV_PosSvVld: nonqueued-receiver-com-spec{data-element=SendLINR_LTRBV_PosSvVld, init-value=SendLINR_LTRBV_PosSvVldValue:1}, required-interface=SendLINR_LTRBV_PosSvVld
      SendLINR_LTRBV_CalRqVld: nonqueued-receiver-com-spec{data-element=SendLINR_LTRBV_CalRqVld, init-value=SendLINR_LTRBV_CalRqVldValue:1}, required-interface=SendLINR_LTRBV_CalRqVld
    50 x provide port:
      VeLINR_U_CPV_MotorVolt: nonqueued-sender-com-spec{data-element=VeLINR_U_CPV_MotorVolt, init-value=VeLINR_U_CPV_MotorVoltValue:0}, provided-interface=VeLINR_U_CPV_MotorVolt
      VeLINR_b_CPV_MotorVoltTO: nonqueued-sender-com-spec{data-element=VeLINR_b_CPV_MotorVoltTO, init-value=VeLINR_b_CPV_MotorVoltTOValue:0}, provided-interface=VeLINR_b_CPV_MotorVoltTO
      VeLINR_e_CPV_CalStat: nonqueued-sender-com-spec{data-element=VeLINR_e_CPV_CalStat, init-value=VeLINR_e_CPV_CalStatValue:0}, provided-interface=VeLINR_e_CPV_CalStat
      VeLINR_b_CPV_CalStatTO: nonqueued-sender-com-spec{data-element=VeLINR_b_CPV_CalStatTO, init-value=VeLINR_b_CPV_CalStatTOValue:0}, provided-interface=VeLINR_b_CPV_CalStatTO
      VeLINR_e_AirHeatrSts: nonqueued-sender-com-spec{data-element=VeLINR_e_AirHeatrSts, init-value=VeLINR_e_AirHeatrStsValue:0}, provided-interface=VeLINR_e_AirHeatrSts
      VeLINR_b_AirHeatrStsTO: nonqueued-sender-com-spec{data-element=VeLINR_b_AirHeatrStsTO, init-value=VeLINR_b_AirHeatrStsTOValue:0}, provided-interface=VeLINR_b_AirHeatrStsTO
      VeLINR_Pct_AirHeatrPwrCns: nonqueued-sender-com-spec{data-element=VeLINR_Pct_AirHeatrPwrCns, init-value=VeLINR_Pct_AirHeatrPwrCnsValue:255}, provided-interface=VeLINR_Pct_AirHeatrPwrCns
      VeLINR_b_AirHeatrPwrCnsTO: nonqueued-sender-com-spec{data-element=VeLINR_b_AirHeatrPwrCnsTO, init-value=VeLINR_b_AirHeatrPwrCnsTOValue:0}, provided-interface=VeLINR_b_AirHeatrPwrCnsTO
      VeLINR_Pct_EEXV_PosAct: nonqueued-sender-com-spec{data-element=VeLINR_Pct_EEXV_PosAct, init-value=VeLINR_Pct_EEXV_PosActValue:0}, provided-interface=VeLINR_Pct_EEXV_PosAct
      VeLINR_b_EEXV_PosActTO: nonqueued-sender-com-spec{data-element=VeLINR_b_EEXV_PosActTO, init-value=VeLINR_b_EEXV_PosActTOValue:0}, provided-interface=VeLINR_b_EEXV_PosActTO
      VeLINR_e_EEXV_CalStat: nonqueued-sender-com-spec{data-element=VeLINR_e_EEXV_CalStat, init-value=VeLINR_e_EEXV_CalStatValue:0}, provided-interface=VeLINR_e_EEXV_CalStat
      VeLINR_b_EEXV_CalStatTO: nonqueued-sender-com-spec{data-element=VeLINR_b_EEXV_CalStatTO, init-value=VeLINR_b_EEXV_CalStatTOValue:0}, provided-interface=VeLINR_b_EEXV_CalStatTO
      VeLINR_b_EEXV_CalRq: nonqueued-sender-com-spec{data-element=VeLINR_b_EEXV_CalRq, init-value=VeLINR_b_EEXV_CalRqValue:0}, provided-interface=VeLINR_b_EEXV_CalRq
      VeLINR_b_EEXV_CalRqTO: nonqueued-sender-com-spec{data-element=VeLINR_b_EEXV_CalRqTO, init-value=VeLINR_b_EEXV_CalRqTOValue:0}, provided-interface=VeLINR_b_EEXV_CalRqTO
      VeLINR_b_RsErr_EEXV: nonqueued-sender-com-spec{data-element=VeLINR_b_RsErr_EEXV, init-value=VeLINR_b_RsErr_EEXVValue:0}, provided-interface=VeLINR_b_RsErr_EEXV
      VeLINR_b_RsErr_EEXV_TO: nonqueued-sender-com-spec{data-element=VeLINR_b_RsErr_EEXV_TO, init-value=VeLINR_b_RsErr_EEXV_TOValue:0}, provided-interface=VeLINR_b_RsErr_EEXV_TO
      VeLINR_e_EEXV_Sts: nonqueued-sender-com-spec{data-element=VeLINR_e_EEXV_Sts, init-value=VeLINR_e_EEXV_StsValue:0}, provided-interface=VeLINR_e_EEXV_Sts
      VeLINR_b_EEXV_StsTO: nonqueued-sender-com-spec{data-element=VeLINR_b_EEXV_StsTO, init-value=VeLINR_b_EEXV_StsTOValue:0}, provided-interface=VeLINR_b_EEXV_StsTO
      VeLINR_e_EEXV_ERR: nonqueued-sender-com-spec{data-element=VeLINR_e_EEXV_ERR, init-value=VeLINR_e_EEXV_ERRValue:0}, provided-interface=VeLINR_e_EEXV_ERR
      VeLINR_b_EEXV_ERR_TO: nonqueued-sender-com-spec{data-element=VeLINR_b_EEXV_ERR_TO, init-value=VeLINR_b_EEXV_ERR_TOValue:0}, provided-interface=VeLINR_b_EEXV_ERR_TO
      VeLINR_U_EEXV_SupplyVolt: nonqueued-sender-com-spec{data-element=VeLINR_U_EEXV_SupplyVolt, init-value=VeLINR_U_EEXV_SupplyVoltValue:0}, provided-interface=VeLINR_U_EEXV_SupplyVolt
      VeLINR_b_EEXV_SupplyVoltTO: nonqueued-sender-com-spec{data-element=VeLINR_b_EEXV_SupplyVoltTO, init-value=VeLINR_b_EEXV_SupplyVoltTOValue:0}, provided-interface=VeLINR_b_EEXV_SupplyVoltTO
      VeLINR_e_EEXV_Refrig_Pressure: nonqueued-sender-com-spec{data-element=VeLINR_e_EEXV_Refrig_Pressure, init-value=VeLINR_e_EEXV_Refrig_PressureValue:1638.3}, provided-interface=VeLINR_e_EEXV_Refrig_Pressure
      VeLINR_b_EEXV_Refrig_PressureTO: nonqueued-sender-com-spec{data-element=VeLINR_b_EEXV_Refrig_PressureTO, init-value=VeLINR_b_EEXV_Refrig_PressureTOValue:0}, provided-interface=VeLINR_b_EEXV_Refrig_PressureTO
      VeLINR_T_EEXV_Board_Temp: nonqueued-sender-com-spec{data-element=VeLINR_T_EEXV_Board_Temp, init-value=VeLINR_T_EEXV_Board_TempValue:-40}, provided-interface=VeLINR_T_EEXV_Board_Temp
      VeLINR_b_EEXV_Board_TempTO: nonqueued-sender-com-spec{data-element=VeLINR_b_EEXV_Board_TempTO, init-value=VeLINR_b_EEXV_Board_TempTOValue:0}, provided-interface=VeLINR_b_EEXV_Board_TempTO
      VeLINR_e_EEXV_Refrigerant_Temp: nonqueued-sender-com-spec{data-element=VeLINR_e_EEXV_Refrigerant_Temp, init-value=VeLINR_e_EEXV_Refrigerant_TempValue:-40}, provided-interface=VeLINR_e_EEXV_Refrigerant_Temp
      VeLINR_b_EEXV_Refrigerant_TempTO: nonqueued-sender-com-spec{data-element=VeLINR_b_EEXV_Refrigerant_TempTO, init-value=VeLINR_b_EEXV_Refrigerant_TempTOValue:0}, provided-interface=VeLINR_b_EEXV_Refrigerant_TempTO
      VeLINR_Pct_EXVM_PosAct: nonqueued-sender-com-spec{data-element=VeLINR_Pct_EXVM_PosAct, init-value=VeLINR_Pct_EXVM_PosActValue:0}, provided-interface=VeLINR_Pct_EXVM_PosAct
      VeLINR_b_EXVM_PosActTO: nonqueued-sender-com-spec{data-element=VeLINR_b_EXVM_PosActTO, init-value=VeLINR_b_EXVM_PosActTOValue:0}, provided-interface=VeLINR_b_EXVM_PosActTO
      VeLINR_e_EXVM_CalStat: nonqueued-sender-com-spec{data-element=VeLINR_e_EXVM_CalStat, init-value=VeLINR_e_EXVM_CalStatValue:0}, provided-interface=VeLINR_e_EXVM_CalStat
      VeLINR_b_EXVM_CalStatTO: nonqueued-sender-com-spec{data-element=VeLINR_b_EXVM_CalStatTO, init-value=VeLINR_b_EXVM_CalStatTOValue:0}, provided-interface=VeLINR_b_EXVM_CalStatTO
      VeLINR_b_EXVM_CalRq: nonqueued-sender-com-spec{data-element=VeLINR_b_EXVM_CalRq, init-value=VeLINR_b_EXVM_CalRqValue:0}, provided-interface=VeLINR_b_EXVM_CalRq
      VeLINR_b_EXVM_CalRqTO: nonqueued-sender-com-spec{data-element=VeLINR_b_EXVM_CalRqTO, init-value=VeLINR_b_EXVM_CalRqTOValue:0}, provided-interface=VeLINR_b_EXVM_CalRqTO
      VeLINR_b_RsErr_EXVM: nonqueued-sender-com-spec{data-element=VeLINR_b_RsErr_EXVM, init-value=VeLINR_b_RsErr_EXVMValue:0}, provided-interface=VeLINR_b_RsErr_EXVM
      VeLINR_b_RsErr_EXVM_TO: nonqueued-sender-com-spec{data-element=VeLINR_b_RsErr_EXVM_TO, init-value=VeLINR_b_RsErr_EXVM_TOValue:0}, provided-interface=VeLINR_b_RsErr_EXVM_TO
      VeLINR_e_EXVM_Sts: nonqueued-sender-com-spec{data-element=VeLINR_e_EXVM_Sts, init-value=VeLINR_e_EXVM_StsValue:0}, provided-interface=VeLINR_e_EXVM_Sts
      VeLINR_b_EXVM_StsTO: nonqueued-sender-com-spec{data-element=VeLINR_b_EXVM_StsTO, init-value=VeLINR_b_EXVM_StsTOValue:0}, provided-interface=VeLINR_b_EXVM_StsTO
      VeLINR_e_EXVM_ERR: nonqueued-sender-com-spec{data-element=VeLINR_e_EXVM_ERR, init-value=VeLINR_e_EXVM_ERRValue:0}, provided-interface=VeLINR_e_EXVM_ERR
      VeLINR_b_EXVM_ERR_TO: nonqueued-sender-com-spec{data-element=VeLINR_b_EXVM_ERR_TO, init-value=VeLINR_b_EXVM_ERR_TOValue:0}, provided-interface=VeLINR_b_EXVM_ERR_TO
      VeLINR_U_EXVM_SupplyVolt: nonqueued-sender-com-spec{data-element=VeLINR_U_EXVM_SupplyVolt, init-value=VeLINR_U_EXVM_SupplyVoltValue:0}, provided-interface=VeLINR_U_EXVM_SupplyVolt
      VeLINR_b_EXVM_SupplyVoltTO: nonqueued-sender-com-spec{data-element=VeLINR_b_EXVM_SupplyVoltTO, init-value=VeLINR_b_EXVM_SupplyVoltTOValue:0}, provided-interface=VeLINR_b_EXVM_SupplyVoltTO
      VeLINR_e_EXVM_Refrig_Pressure: nonqueued-sender-com-spec{data-element=VeLINR_e_EXVM_Refrig_Pressure, init-value=VeLINR_e_EXVM_Refrig_PressureValue:1638.3}, provided-interface=VeLINR_e_EXVM_Refrig_Pressure
      VeLINR_b_EXVM_Refrig_PressureTO: nonqueued-sender-com-spec{data-element=VeLINR_b_EXVM_Refrig_PressureTO, init-value=VeLINR_b_EXVM_Refrig_PressureTOValue:0}, provided-interface=VeLINR_b_EXVM_Refrig_PressureTO
      VeLINR_T_EXVM_Board_Temp: nonqueued-sender-com-spec{data-element=VeLINR_T_EXVM_Board_Temp, init-value=VeLINR_T_EXVM_Board_TempValue:-40}, provided-interface=VeLINR_T_EXVM_Board_Temp
      VeLINR_b_EXVM_Board_TempTO: nonqueued-sender-com-spec{data-element=VeLINR_b_EXVM_Board_TempTO, init-value=VeLINR_b_EXVM_Board_TempTOValue:0}, provided-interface=VeLINR_b_EXVM_Board_TempTO
      VeLINR_e_EXVM_Refrigerant_Temp: nonqueued-sender-com-spec{data-element=VeLINR_e_EXVM_Refrigerant_Temp, init-value=VeLINR_e_EXVM_Refrigerant_TempValue:-40}, provided-interface=VeLINR_e_EXVM_Refrigerant_Temp
      VeLINR_b_EXVM_Refrigerant_TempTO: nonqueued-sender-com-spec{data-element=VeLINR_b_EXVM_Refrigerant_TempTO, init-value=VeLINR_b_EXVM_Refrigerant_TempTOValue:0}, provided-interface=VeLINR_b_EXVM_Refrigerant_TempTO
      VeLINR_e_LTRBV_CalStat: nonqueued-sender-com-spec{data-element=VeLINR_e_LTRBV_CalStat, init-value=VeLINR_e_LTRBV_CalStatValue:0}, provided-interface=VeLINR_e_LTRBV_CalStat
      VeLINR_b_LTRBV_CalStatTO: nonqueued-sender-com-spec{data-element=VeLINR_b_LTRBV_CalStatTO, init-value=VeLINR_b_LTRBV_CalStatTOValue:0}, provided-interface=VeLINR_b_LTRBV_CalStatTO
    10 x require port:
      SendLINR_EEXV_PosRq: nonqueued-receiver-com-spec{data-element=SendLINR_EEXV_PosRq, init-value=SendLINR_EEXV_PosRqValue:0}, required-interface=SendLINR_EEXV_PosRq
      SendLINR_EEXV_PosRqVld: nonqueued-receiver-com-spec{data-element=SendLINR_EEXV_PosRqVld, init-value=SendLINR_EEXV_PosRqVldValue:1}, required-interface=SendLINR_EEXV_PosRqVld
      SendLINR_EEXV_CalCmd: nonqueued-receiver-com-spec{data-element=SendLINR_EEXV_CalCmd, init-value=SendLINR_EEXV_CalCmdValue:0}, required-interface=SendLINR_EEXV_CalCmd
      SendLINR_EEXV_CalCmdVld: nonqueued-receiver-com-spec{data-element=SendLINR_EEXV_CalCmdVld, init-value=SendLINR_EEXV_CalCmdVldValue:1}, required-interface=SendLINR_EEXV_CalCmdVld
      SendLINR_EXVM_PosRq: nonqueued-receiver-com-spec{data-element=SendLINR_EXVM_PosRq, init-value=SendLINR_EXVM_PosRqValue:0}, required-interface=SendLINR_EXVM_PosRq
      SendLINR_EXVM_PosRqVld: nonqueued-receiver-com-spec{data-element=SendLINR_EXVM_PosRqVld, init-value=SendLINR_EXVM_PosRqVldValue:1}, required-interface=SendLINR_EXVM_PosRqVld
      SendLINR_EXVM_CalCmd: nonqueued-receiver-com-spec{data-element=SendLINR_EXVM_CalCmd, init-value=SendLINR_EXVM_CalCmdValue:0}, required-interface=SendLINR_EXVM_CalCmd
      SendLINR_EXVM_CalCmdVld: nonqueued-receiver-com-spec{data-element=SendLINR_EXVM_CalCmdVld, init-value=SendLINR_EXVM_CalCmdVldValue:1}, required-interface=SendLINR_EXVM_CalCmdVld
      SignalLINR_EXVM_RdyForSleep: nonqueued-receiver-com-spec{data-element=SignalLINR_EXVM_RdyForSleep, init-value=SignalLINR_EXVM_RdyForSleepValue:0}, required-interface=SignalLINR_EXVM_RdyForSleep
      KeCFGR_b_EXVM_Equid: parameter-require-com-spec{init-value=Value:0, parameter=KeCFGR_b_EXVM_Equid}, required-interface=KeCFGR_b_EXVM_Equid
    24 x provide port:
      VeLINR_e_CoolantValve_ErrLinCom: nonqueued-sender-com-spec{data-element=VeLINR_e_CoolantValve_ErrLinCom, init-value=VeLINR_e_CoolantValve_ErrLinComValue:0}, provided-interface=VeLINR_e_CoolantValve_ErrLinCom
      VeLINR_b_CoolantValve_ErrLinComTO: nonqueued-sender-com-spec{data-element=VeLINR_b_CoolantValve_ErrLinComTO, init-value=VeLINR_b_CoolantValve_ErrLinComTOValue:0}, provided-interface=VeLINR_b_CoolantValve_ErrLinComTO
      VeLINR_e_CoolantValve_ErrPos: nonqueued-sender-com-spec{data-element=VeLINR_e_CoolantValve_ErrPos, init-value=VeLINR_e_CoolantValve_ErrPosValue:0}, provided-interface=VeLINR_e_CoolantValve_ErrPos
      VeLINR_b_CoolantValve_ErrPosTO: nonqueued-sender-com-spec{data-element=VeLINR_b_CoolantValve_ErrPosTO, init-value=VeLINR_b_CoolantValve_ErrPosTOValue:0}, provided-interface=VeLINR_b_CoolantValve_ErrPosTO
      VeLINR_b_CoolantVal_SelfCalReq: nonqueued-sender-com-spec{data-element=VeLINR_b_CoolantVal_SelfCalReq, init-value=VeLINR_b_CoolantVal_SelfCalReqValue:0}, provided-interface=VeLINR_b_CoolantVal_SelfCalReq
      VeLINR_b_CoolantVal_SelfCalReqTO: nonqueued-sender-com-spec{data-element=VeLINR_b_CoolantVal_SelfCalReqTO, init-value=VeLINR_b_CoolantVal_SelfCalReqTOValue:0}, provided-interface=VeLINR_b_CoolantVal_SelfCalReqTO
      VeLINR_e_CoolantVal_SystemState: nonqueued-sender-com-spec{data-element=VeLINR_e_CoolantVal_SystemState, init-value=VeLINR_e_CoolantVal_SystemStateValue:0}, provided-interface=VeLINR_e_CoolantVal_SystemState
      VeLINR_b_CoolantVal_SystemStateTO: nonqueued-sender-com-spec{data-element=VeLINR_b_CoolantVal_SystemStateTO, init-value=VeLINR_b_CoolantVal_SystemStateTOValue:0}, provided-interface=VeLINR_b_CoolantVal_SystemStateTO
      VeLINR_y_CoolantVal_EcuVoltage: nonqueued-sender-com-spec{data-element=VeLINR_y_CoolantVal_EcuVoltage, init-value=VeLINR_y_CoolantVal_EcuVoltageValue:0}, provided-interface=VeLINR_y_CoolantVal_EcuVoltage
      VeLINR_b_CoolantVal_EcuVoltageTO: nonqueued-sender-com-spec{data-element=VeLINR_b_CoolantVal_EcuVoltageTO, init-value=VeLINR_b_CoolantVal_EcuVoltageTOValue:0}, provided-interface=VeLINR_b_CoolantVal_EcuVoltageTO
      VeLINR_d_CoolVal_ActuatPosTrgt: nonqueued-sender-com-spec{data-element=VeLINR_d_CoolVal_ActuatPosTrgt, init-value=VeLINR_d_CoolVal_ActuatPosTrgtValue:0}, provided-interface=VeLINR_d_CoolVal_ActuatPosTrgt
      VeLINR_b_CoolVal_ActuatPosTrgtTO: nonqueued-sender-com-spec{data-element=VeLINR_b_CoolVal_ActuatPosTrgtTO, init-value=VeLINR_b_CoolVal_ActuatPosTrgtTOValue:0}, provided-interface=VeLINR_b_CoolVal_ActuatPosTrgtTO
      VeLINR_d_CoolantVal_ActuPosAct: nonqueued-sender-com-spec{data-element=VeLINR_d_CoolantVal_ActuPosAct, init-value=VeLINR_d_CoolantVal_ActuPosActValue:0}, provided-interface=VeLINR_d_CoolantVal_ActuPosAct
      VeLINR_b_CoolantVal_ActuPosActTO: nonqueued-sender-com-spec{data-element=VeLINR_b_CoolantVal_ActuPosActTO, init-value=VeLINR_b_CoolantVal_ActuPosActTOValue:0}, provided-interface=VeLINR_b_CoolantVal_ActuPosActTO
      VeLINR_y_CoolantValve_EcuTemp: nonqueued-sender-com-spec{data-element=VeLINR_y_CoolantValve_EcuTemp, init-value=VeLINR_y_CoolantValve_EcuTempValue:-40}, provided-interface=VeLINR_y_CoolantValve_EcuTemp
      VeLINR_b_CoolantValve_EcuTempTO: nonqueued-sender-com-spec{data-element=VeLINR_b_CoolantValve_EcuTempTO, init-value=VeLINR_b_CoolantValve_EcuTempTOValue:0}, provided-interface=VeLINR_b_CoolantValve_EcuTempTO
      VeLINR_e_CoolantValve_Err_Motor: nonqueued-sender-com-spec{data-element=VeLINR_e_CoolantValve_Err_Motor, init-value=VeLINR_e_CoolantValve_Err_MotorValue:0}, provided-interface=VeLINR_e_CoolantValve_Err_Motor
      VeLINR_b_CoolantValve_Err_MotorTO: nonqueued-sender-com-spec{data-element=VeLINR_b_CoolantValve_Err_MotorTO, init-value=VeLINR_b_CoolantValve_Err_MotorTOValue:0}, provided-interface=VeLINR_b_CoolantValve_Err_MotorTO
      VeLINR_e_CoolantValve_Err_Volt: nonqueued-sender-com-spec{data-element=VeLINR_e_CoolantValve_Err_Volt, init-value=VeLINR_e_CoolantValve_Err_VoltValue:0}, provided-interface=VeLINR_e_CoolantValve_Err_Volt
      VeLINR_b_CoolantValve_Err_VoltTO: nonqueued-sender-com-spec{data-element=VeLINR_b_CoolantValve_Err_VoltTO, init-value=VeLINR_b_CoolantValve_Err_VoltTOValue:0}, provided-interface=VeLINR_b_CoolantValve_Err_VoltTO
      VeLINR_e_CoolantValve_Err_Ecu: nonqueued-sender-com-spec{data-element=VeLINR_e_CoolantValve_Err_Ecu, init-value=VeLINR_e_CoolantValve_Err_EcuValue:0}, provided-interface=VeLINR_e_CoolantValve_Err_Ecu
      VeLINR_b_CoolantValve_Err_EcuTO: nonqueued-sender-com-spec{data-element=VeLINR_b_CoolantValve_Err_EcuTO, init-value=VeLINR_b_CoolantValve_Err_EcuTOValue:0}, provided-interface=VeLINR_b_CoolantValve_Err_EcuTO
      VeLINR_b_CoolantVal_ResponseErr: nonqueued-sender-com-spec{data-element=VeLINR_b_CoolantVal_ResponseErr, init-value=VeLINR_b_CoolantVal_ResponseErrValue:0}, provided-interface=VeLINR_b_CoolantVal_ResponseErr
      VeLINR_b_CoolantVal_ResponseErrTO: nonqueued-sender-com-spec{data-element=VeLINR_b_CoolantVal_ResponseErrTO, init-value=VeLINR_b_CoolantVal_ResponseErrTOValue:0}, provided-interface=VeLINR_b_CoolantVal_ResponseErrTO
    20 x require port:
      SendLINR_Control_TargetPos: nonqueued-receiver-com-spec{data-element=SendLINR_Control_TargetPos, init-value=SendLINR_Control_TargetPosValue:0}, required-interface=SendLINR_Control_TargetPos
      SendLINR_Control_TargetPosVld: nonqueued-receiver-com-spec{data-element=SendLINR_Control_TargetPosVld, init-value=SendLINR_Control_TargetPosVldValue:1}, required-interface=SendLINR_Control_TargetPosVld
      SendLINR_Control_Reserved1: nonqueued-receiver-com-spec{data-element=SendLINR_Control_Reserved1, init-value=SendLINR_Control_Reserved1Value:0}, required-interface=SendLINR_Control_Reserved1
      SendLINR_Control_Reserved1Vld: nonqueued-receiver-com-spec{data-element=SendLINR_Control_Reserved1Vld, init-value=SendLINR_Control_Reserved1VldValue:1}, required-interface=SendLINR_Control_Reserved1Vld
      SendLINR_Control_BlockDetEnbl: nonqueued-receiver-com-spec{data-element=SendLINR_Control_BlockDetEnbl, init-value=SendLINR_Control_BlockDetEnblValue:0}, required-interface=SendLINR_Control_BlockDetEnbl
      SendLINR_Control_BlockDetEnblVld: nonqueued-receiver-com-spec{data-element=SendLINR_Control_BlockDetEnblVld, init-value=SendLINR_Control_BlockDetEnblVldValue:1}, required-interface=SendLINR_Control_BlockDetEnblVld
      SendLINR_Control_DiagFunctnVal: nonqueued-receiver-com-spec{data-element=SendLINR_Control_DiagFunctnVal, init-value=SendLINR_Control_DiagFunctnValValue:0}, required-interface=SendLINR_Control_DiagFunctnVal
      SendLINR_Control_DiagFunctnValVld: nonqueued-receiver-com-spec{data-element=SendLINR_Control_DiagFunctnValVld, init-value=SendLINR_Control_DiagFunctnValVldValue:1}, required-interface=SendLINR_Control_DiagFunctnValVld
      SendLINR_Control_Reserved2: nonqueued-receiver-com-spec{data-element=SendLINR_Control_Reserved2, init-value=SendLINR_Control_Reserved2Value:0}, required-interface=SendLINR_Control_Reserved2
      SendLINR_Control_Reserved2Vld: nonqueued-receiver-com-spec{data-element=SendLINR_Control_Reserved2Vld, init-value=SendLINR_Control_Reserved2VldValue:1}, required-interface=SendLINR_Control_Reserved2Vld
      SendLINR_Control_Reserved3: nonqueued-receiver-com-spec{data-element=SendLINR_Control_Reserved3, init-value=SendLINR_Control_Reserved3Value:0}, required-interface=SendLINR_Control_Reserved3
      SendLINR_Control_Reserved3Vld: nonqueued-receiver-com-spec{data-element=SendLINR_Control_Reserved3Vld, init-value=SendLINR_Control_Reserved3VldValue:1}, required-interface=SendLINR_Control_Reserved3Vld
      SendLINR_Control_Reserved4: nonqueued-receiver-com-spec{data-element=SendLINR_Control_Reserved4, init-value=SendLINR_Control_Reserved4Value:0}, required-interface=SendLINR_Control_Reserved4
      SendLINR_Control_Reserved4Vld: nonqueued-receiver-com-spec{data-element=SendLINR_Control_Reserved4Vld, init-value=SendLINR_Control_Reserved4VldValue:1}, required-interface=SendLINR_Control_Reserved4Vld
      SendLINR_Control_Reserved5: nonqueued-receiver-com-spec{data-element=SendLINR_Control_Reserved5, init-value=SendLINR_Control_Reserved5Value:0}, required-interface=SendLINR_Control_Reserved5
      SendLINR_Control_Reserved5Vld: nonqueued-receiver-com-spec{data-element=SendLINR_Control_Reserved5Vld, init-value=SendLINR_Control_Reserved5VldValue:1}, required-interface=SendLINR_Control_Reserved5Vld
      SendLINR_Control_Reserved6: nonqueued-receiver-com-spec{data-element=SendLINR_Control_Reserved6, init-value=SendLINR_Control_Reserved6Value:0}, required-interface=SendLINR_Control_Reserved6
      SendLINR_Control_Reserved6Vld: nonqueued-receiver-com-spec{data-element=SendLINR_Control_Reserved6Vld, init-value=SendLINR_Control_Reserved6VldValue:1}, required-interface=SendLINR_Control_Reserved6Vld
      SignalLINR_HTRBV_RdyForSleep: nonqueued-receiver-com-spec{data-element=SignalLINR_HTRBV_RdyForSleep, init-value=SignalLINR_HTRBV_RdyForSleepValue:0}, required-interface=SignalLINR_HTRBV_RdyForSleep
      KeCFGR_b_HTRBV_Equid: parameter-require-com-spec{init-value=Value:0, parameter=KeCFGR_b_HTRBV_Equid}, required-interface=KeCFGR_b_HTRBV_Equid
    behavior IBApplLinComAb_LIN1: data-type-mapping=[MG_LinEquid_Mapping, ADTtoIDTMapping, BswMMappingSet], handle-termination-and-restart=NO-SUPPORT
      init event IninEve: start-on-event=ApplLinComAb_LIN1Inin
      swc mode switch event MSELinsmComMod: disabled-mode=[MdulPwrMod.AppMode_MDGP_ESH_Mode.POSTRUN, MdulPwrMod.AppMode_MDGP_ESH_Mode.SHUTDOWN], start-on-event=LinsmComModSetScheduleTbl, activation=ON-ENTRY, mode=PP_MS_LinSMComMod.MDGP_MSI_LinSMComMod.LinSMComMod_FULL_COMM  # Triggered when Linsm goes to FULL COMM mode. Used to set the schedule table based on the equipped/learned state of the slaves.
      swc mode switch event MSELinsmInNoComMod: start-on-event=LinsmComModNotifyRdyToPwrDwn, activation=ON-ENTRY, mode=PP_MS_LinSMComMod.MDGP_MSI_LinSMComMod.LinSMComMod_NO_COMM  # When LinSM goes to NO COMM mode
        disabled-mode:
          MdulPwrMod.AppMode_MDGP_ESH_Mode.RUN
          MdulPwrMod.AppMode_MDGP_ESH_Mode.STARTUP
          MdulPwrMod.AppMode_MDGP_ESH_Mode.WAKEUP
      swc mode switch event MSEMdulInPostrun: start-on-event=LinsmComModPostrun, activation=ON-ENTRY, mode=MdulPwrMod.AppMode_MDGP_ESH_Mode.POSTRUN
      9 x data received event:
        DRESignalLINR_AAD_RdyForSleep: start-on-event=SignalLINR_AAD_RdyForSleep, data=SignalLINR_AAD_RdyForSleep.SignalLINR_AAD_RdyForSleep
          disabled-mode:
            MdulPwrMod.AppMode_MDGP_ESH_Mode.RUN
            MdulPwrMod.AppMode_MDGP_ESH_Mode.STARTUP
            MdulPwrMod.AppMode_MDGP_ESH_Mode.SHUTDOWN
            MdulPwrMod.AppMode_MDGP_ESH_Mode.WAKEUP
        DRESignalLINR_BCP_RdyForSleep: start-on-event=SignalLINR_BCP_RdyForSleep, data=SignalLINR_BCP_RdyForSleep.SignalLINR_BCP_RdyForSleep
          disabled-mode:
            MdulPwrMod.AppMode_MDGP_ESH_Mode.RUN
            MdulPwrMod.AppMode_MDGP_ESH_Mode.STARTUP
            MdulPwrMod.AppMode_MDGP_ESH_Mode.SHUTDOWN
            MdulPwrMod.AppMode_MDGP_ESH_Mode.WAKEUP
        DRESignalLINR_CPV_RdyForSleep: start-on-event=SignalLINR_CPV_RdyForSleep, data=SignalLINR_CPV_RdyForSleep.SignalLINR_CPV_RdyForSleep
          disabled-mode:
            MdulPwrMod.AppMode_MDGP_ESH_Mode.RUN
            MdulPwrMod.AppMode_MDGP_ESH_Mode.STARTUP
            MdulPwrMod.AppMode_MDGP_ESH_Mode.SHUTDOWN
            MdulPwrMod.AppMode_MDGP_ESH_Mode.WAKEUP
        DRESignalLINR_EAH_RdyForSleep: start-on-event=SignalLINR_EAH_RdyForSleep, data=SignalLINR_EAH_RdyForSleep.SignalLINR_EAH_RdyForSleep
          disabled-mode:
            MdulPwrMod.AppMode_MDGP_ESH_Mode.RUN
            MdulPwrMod.AppMode_MDGP_ESH_Mode.STARTUP
            MdulPwrMod.AppMode_MDGP_ESH_Mode.SHUTDOWN
            MdulPwrMod.AppMode_MDGP_ESH_Mode.WAKEUP
        DRESignalLINR_EEXV_RdyForSleep: start-on-event=SignalLINR_EEXV_RdyForSleep, data=SignalLINR_EEXV_RdyForSleep.SignalLINR_EEXV_RdyForSleep
          disabled-mode:
            MdulPwrMod.AppMode_MDGP_ESH_Mode.RUN
            MdulPwrMod.AppMode_MDGP_ESH_Mode.STARTUP
            MdulPwrMod.AppMode_MDGP_ESH_Mode.SHUTDOWN
            MdulPwrMod.AppMode_MDGP_ESH_Mode.WAKEUP
        DRESignalLINR_EOPA_RdyForSleep: start-on-event=SignalLINR_EOPA_RdyForSleep, data=SignalLINR_EOPA_RdyForSleep.SignalLINR_EOPA_RdyForSleep
          disabled-mode:
            MdulPwrMod.AppMode_MDGP_ESH_Mode.RUN
            MdulPwrMod.AppMode_MDGP_ESH_Mode.STARTUP
            MdulPwrMod.AppMode_MDGP_ESH_Mode.SHUTDOWN
            MdulPwrMod.AppMode_MDGP_ESH_Mode.WAKEUP
        DRESignalLINR_EXVM_RdyForSleep: start-on-event=SignalLINR_EXVM_RdyForSleep, data=SignalLINR_EXVM_RdyForSleep.SignalLINR_EXVM_RdyForSleep
          disabled-mode:
            MdulPwrMod.AppMode_MDGP_ESH_Mode.RUN
            MdulPwrMod.AppMode_MDGP_ESH_Mode.STARTUP
            MdulPwrMod.AppMode_MDGP_ESH_Mode.SHUTDOWN
            MdulPwrMod.AppMode_MDGP_ESH_Mode.WAKEUP
        DRESignalLINR_LTRBV_RdyForSleep: start-on-event=SignalLINR_LTRBV_RdyForSleep, data=SignalLINR_LTRBV_RdyForSleep.SignalLINR_LTRBV_RdyForSleep
          disabled-mode:
            MdulPwrMod.AppMode_MDGP_ESH_Mode.RUN
            MdulPwrMod.AppMode_MDGP_ESH_Mode.STARTUP
            MdulPwrMod.AppMode_MDGP_ESH_Mode.SHUTDOWN
            MdulPwrMod.AppMode_MDGP_ESH_Mode.WAKEUP
        DRECOMRXL_AAD_CurrPos_AAD_ECM_STATUS_Lin1: start-on-event=COMRXL_AAD_CurrPos_AAD_ECM_STATUS_Lin1_Received, data=Lin1ComRxSignalsSR.COMRXL_AAD_CurrPos_AAD_ECM_STATUS_Lin1
      data receive error event DEECOMRXL_AAD_CurrPos_AAD_ECM_STATUS_Lin1: start-on-event=COMRXL_AAD_CurrPos_AAD_ECM_STATUS_Lin1_Error, data=Lin1ComRxSignalsSR.COMRXL_AAD_CurrPos_AAD_ECM_STATUS_Lin1
      data received event DRECOMRXL_AAD_CalStat_AAD_ECM_STATUS_Lin1: start-on-event=COMRXL_AAD_CalStat_AAD_ECM_STATUS_Lin1_Received, data=Lin1ComRxSignalsSR.COMRXL_AAD_CalStat_AAD_ECM_STATUS_Lin1
      data receive error event DEECOMRXL_AAD_CalStat_AAD_ECM_STATUS_Lin1: start-on-event=COMRXL_AAD_CalStat_AAD_ECM_STATUS_Lin1_Error, data=Lin1ComRxSignalsSR.COMRXL_AAD_CalStat_AAD_ECM_STATUS_Lin1
      data received event DRECOMRXL_AAD_CalActv_AAD_ECM_STATUS_Lin1: start-on-event=COMRXL_AAD_CalActv_AAD_ECM_STATUS_Lin1_Received, data=Lin1ComRxSignalsSR.COMRXL_AAD_CalActv_AAD_ECM_STATUS_Lin1
      data receive error event DEECOMRXL_AAD_CalActv_AAD_ECM_STATUS_Lin1: start-on-event=COMRXL_AAD_CalActv_AAD_ECM_STATUS_Lin1_Error, data=Lin1ComRxSignalsSR.COMRXL_AAD_CalActv_AAD_ECM_STATUS_Lin1
      data received event DRECOMRXL_AAD_ErrUnVolt_AAD_ECM_STATUS_Lin1: start-on-event=COMRXL_AAD_ErrUnVolt_AAD_ECM_STATUS_Lin1_Received, data=Lin1ComRxSignalsSR.COMRXL_AAD_ErrUnVolt_AAD_ECM_STATUS_Lin1
      data receive error event DEECOMRXL_AAD_ErrUnVolt_AAD_ECM_STATUS_Lin1: start-on-event=COMRXL_AAD_ErrUnVolt_AAD_ECM_STATUS_Lin1_Error, data=Lin1ComRxSignalsSR.COMRXL_AAD_ErrUnVolt_AAD_ECM_STATUS_Lin1
      data received event DRECOMRXL_AAD_ErrOvrVolt_AAD_ECM_STATUS_Lin1: start-on-event=COMRXL_AAD_ErrOvrVolt_AAD_ECM_STATUS_Lin1_Received, data=Lin1ComRxSignalsSR.COMRXL_AAD_ErrOvrVolt_AAD_ECM_STATUS_Lin1
      data receive error event DEECOMRXL_AAD_ErrOvrVolt_AAD_ECM_STATUS_Lin1: start-on-event=COMRXL_AAD_ErrOvrVolt_AAD_ECM_STATUS_Lin1_Error, data=Lin1ComRxSignalsSR.COMRXL_AAD_ErrOvrVolt_AAD_ECM_STATUS_Lin1
      data received event DRECOMRXL_AAD_ErrOvrTemp_AAD_ECM_STATUS_Lin1: start-on-event=COMRXL_AAD_ErrOvrTemp_AAD_ECM_STATUS_Lin1_Received, data=Lin1ComRxSignalsSR.COMRXL_AAD_ErrOvrTemp_AAD_ECM_STATUS_Lin1
      data receive error event DEECOMRXL_AAD_ErrOvrTemp_AAD_ECM_STATUS_Lin1: start-on-event=COMRXL_AAD_ErrOvrTemp_AAD_ECM_STATUS_Lin1_Error, data=Lin1ComRxSignalsSR.COMRXL_AAD_ErrOvrTemp_AAD_ECM_STATUS_Lin1
      data received event DRECOMRXL_AAD_ErrMechStuck_AAD_ECM_STATUS_Lin1: start-on-event=COMRXL_AAD_ErrMechStuck_AAD_ECM_STATUS_Lin1_Received, data=Lin1ComRxSignalsSR.COMRXL_AAD_ErrMechStuck_AAD_ECM_STATUS_Lin1
      data receive error event DEECOMRXL_AAD_ErrMechStuck_AAD_ECM_STATUS_Lin1: start-on-event=COMRXL_AAD_ErrMechStuck_AAD_ECM_STATUS_Lin1_Error, data=Lin1ComRxSignalsSR.COMRXL_AAD_ErrMechStuck_AAD_ECM_STATUS_Lin1
      data received event DRECOMRXL_AAD_ErrMechBreak_AAD_ECM_STATUS_Lin1: start-on-event=COMRXL_AAD_ErrMechBreak_AAD_ECM_STATUS_Lin1_Received, data=Lin1ComRxSignalsSR.COMRXL_AAD_ErrMechBreak_AAD_ECM_STATUS_Lin1
      data receive error event DEECOMRXL_AAD_ErrMechBreak_AAD_ECM_STATUS_Lin1: start-on-event=COMRXL_AAD_ErrMechBreak_AAD_ECM_STATUS_Lin1_Error, data=Lin1ComRxSignalsSR.COMRXL_AAD_ErrMechBreak_AAD_ECM_STATUS_Lin1
      data received event DRECOMRXL_RsErr_AAD_AAD_ECM_STATUS_Lin1: start-on-event=COMRXL_RsErr_AAD_AAD_ECM_STATUS_Lin1_Received, data=Lin1ComRxSignalsSR.COMRXL_RsErr_AAD_AAD_ECM_STATUS_Lin1
      data receive error event DEECOMRXL_RsErr_AAD_AAD_ECM_STATUS_Lin1: start-on-event=COMRXL_RsErr_AAD_AAD_ECM_STATUS_Lin1_Error, data=Lin1ComRxSignalsSR.COMRXL_RsErr_AAD_AAD_ECM_STATUS_Lin1
      data received event DRECOMRXL_BCP_RPM_TARGET_BCP_STAT_Lin1: start-on-event=COMRXL_BCP_RPM_TARGET_BCP_STAT_Lin1_Received, data=Lin1ComRxSignalsSR.COMRXL_BCP_RPM_TARGET_BCP_STAT_Lin1
      data receive error event DEECOMRXL_BCP_RPM_TARGET_BCP_STAT_Lin1: start-on-event=COMRXL_BCP_RPM_TARGET_BCP_STAT_Lin1_Error, data=Lin1ComRxSignalsSR.COMRXL_BCP_RPM_TARGET_BCP_STAT_Lin1
      data received event DRECOMRXL_BCP_RPM_ACTUAL_BCP_STAT_Lin1: start-on-event=COMRXL_BCP_RPM_ACTUAL_BCP_STAT_Lin1_Received, data=Lin1ComRxSignalsSR.COMRXL_BCP_RPM_ACTUAL_BCP_STAT_Lin1
      data receive error event DEECOMRXL_BCP_RPM_ACTUAL_BCP_STAT_Lin1: start-on-event=COMRXL_BCP_RPM_ACTUAL_BCP_STAT_Lin1_Error, data=Lin1ComRxSignalsSR.COMRXL_BCP_RPM_ACTUAL_BCP_STAT_Lin1
      data received event DRECOMRXL_BCP_VLTG_BCP_STAT_Lin1: start-on-event=COMRXL_BCP_VLTG_BCP_STAT_Lin1_Received, data=Lin1ComRxSignalsSR.COMRXL_BCP_VLTG_BCP_STAT_Lin1
      data receive error event DEECOMRXL_BCP_VLTG_BCP_STAT_Lin1: start-on-event=COMRXL_BCP_VLTG_BCP_STAT_Lin1_Error, data=Lin1ComRxSignalsSR.COMRXL_BCP_VLTG_BCP_STAT_Lin1
      data received event DRECOMRXL_BCP_TEMP_BCP_STAT_Lin1: start-on-event=COMRXL_BCP_TEMP_BCP_STAT_Lin1_Received, data=Lin1ComRxSignalsSR.COMRXL_BCP_TEMP_BCP_STAT_Lin1
      data receive error event DEECOMRXL_BCP_TEMP_BCP_STAT_Lin1: start-on-event=COMRXL_BCP_TEMP_BCP_STAT_Lin1_Error, data=Lin1ComRxSignalsSR.COMRXL_BCP_TEMP_BCP_STAT_Lin1
      data received event DRECOMRXL_BCP_CURR_BCP_STAT_Lin1: start-on-event=COMRXL_BCP_CURR_BCP_STAT_Lin1_Received, data=Lin1ComRxSignalsSR.COMRXL_BCP_CURR_BCP_STAT_Lin1
      data receive error event DEECOMRXL_BCP_CURR_BCP_STAT_Lin1: start-on-event=COMRXL_BCP_CURR_BCP_STAT_Lin1_Error, data=Lin1ComRxSignalsSR.COMRXL_BCP_CURR_BCP_STAT_Lin1
      data received event DRECOMRXL_BCP_FL_SAFE_ACTVTD_BCP_STAT_Lin1: start-on-event=COMRXL_BCP_FL_SAFE_ACTVTD_BCP_STAT_Lin1_Received, data=Lin1ComRxSignalsSR.COMRXL_BCP_FL_SAFE_ACTVTD_BCP_STAT_Lin1
      data receive error event DEECOMRXL_BCP_FL_SAFE_ACTVTD_BCP_STAT_Lin1: start-on-event=COMRXL_BCP_FL_SAFE_ACTVTD_BCP_STAT_Lin1_Error, data=Lin1ComRxSignalsSR.COMRXL_BCP_FL_SAFE_ACTVTD_BCP_STAT_Lin1
      data received event DRECOMRXL_BCP_LMP_HM_AN_ON_BCP_STAT_Lin1: start-on-event=COMRXL_BCP_LMP_HM_AN_ON_BCP_STAT_Lin1_Received, data=Lin1ComRxSignalsSR.COMRXL_BCP_LMP_HM_AN_ON_BCP_STAT_Lin1
      data receive error event DEECOMRXL_BCP_LMP_HM_AN_ON_BCP_STAT_Lin1: start-on-event=COMRXL_BCP_LMP_HM_AN_ON_BCP_STAT_Lin1_Error, data=Lin1ComRxSignalsSR.COMRXL_BCP_LMP_HM_AN_ON_BCP_STAT_Lin1
      data received event DRECOMRXL_BCP_AIR_PRE_ERR_BCP_STAT_Lin1: start-on-event=COMRXL_BCP_AIR_PRE_ERR_BCP_STAT_Lin1_Received, data=Lin1ComRxSignalsSR.COMRXL_BCP_AIR_PRE_ERR_BCP_STAT_Lin1
      data receive error event DEECOMRXL_BCP_AIR_PRE_ERR_BCP_STAT_Lin1: start-on-event=COMRXL_BCP_AIR_PRE_ERR_BCP_STAT_Lin1_Error, data=Lin1ComRxSignalsSR.COMRXL_BCP_AIR_PRE_ERR_BCP_STAT_Lin1
      data received event DRECOMRXL_BCP_OVR_TMP_ERR_BCP_STAT_Lin1: start-on-event=COMRXL_BCP_OVR_TMP_ERR_BCP_STAT_Lin1_Received, data=Lin1ComRxSignalsSR.COMRXL_BCP_OVR_TMP_ERR_BCP_STAT_Lin1
      data receive error event DEECOMRXL_BCP_OVR_TMP_ERR_BCP_STAT_Lin1: start-on-event=COMRXL_BCP_OVR_TMP_ERR_BCP_STAT_Lin1_Error, data=Lin1ComRxSignalsSR.COMRXL_BCP_OVR_TMP_ERR_BCP_STAT_Lin1
      data received event DRECOMRXL_BCP_OVR_CUR_ERR_BCP_STAT_Lin1: start-on-event=COMRXL_BCP_OVR_CUR_ERR_BCP_STAT_Lin1_Received, data=Lin1ComRxSignalsSR.COMRXL_BCP_OVR_CUR_ERR_BCP_STAT_Lin1
      data receive error event DEECOMRXL_BCP_OVR_CUR_ERR_BCP_STAT_Lin1: start-on-event=COMRXL_BCP_OVR_CUR_ERR_BCP_STAT_Lin1_Error, data=Lin1ComRxSignalsSR.COMRXL_BCP_OVR_CUR_ERR_BCP_STAT_Lin1
      data received event DRECOMRXL_BCP_DR_RN_ERR_BCP_STAT_Lin1: start-on-event=COMRXL_BCP_DR_RN_ERR_BCP_STAT_Lin1_Received, data=Lin1ComRxSignalsSR.COMRXL_BCP_DR_RN_ERR_BCP_STAT_Lin1
      data receive error event DEECOMRXL_BCP_DR_RN_ERR_BCP_STAT_Lin1: start-on-event=COMRXL_BCP_DR_RN_ERR_BCP_STAT_Lin1_Error, data=Lin1ComRxSignalsSR.COMRXL_BCP_DR_RN_ERR_BCP_STAT_Lin1
      data received event DRECOMRXL_BCP_VLTG_ERR_BCP_STAT_Lin1: start-on-event=COMRXL_BCP_VLTG_ERR_BCP_STAT_Lin1_Received, data=Lin1ComRxSignalsSR.COMRXL_BCP_VLTG_ERR_BCP_STAT_Lin1
      data receive error event DEECOMRXL_BCP_VLTG_ERR_BCP_STAT_Lin1: start-on-event=COMRXL_BCP_VLTG_ERR_BCP_STAT_Lin1_Error, data=Lin1ComRxSignalsSR.COMRXL_BCP_VLTG_ERR_BCP_STAT_Lin1
      data received event DRECOMRXL_BCP_DBLK_ACTV_BCP_STAT_Lin1: start-on-event=COMRXL_BCP_DBLK_ACTV_BCP_STAT_Lin1_Received, data=Lin1ComRxSignalsSR.COMRXL_BCP_DBLK_ACTV_BCP_STAT_Lin1
      data receive error event DEECOMRXL_BCP_DBLK_ACTV_BCP_STAT_Lin1: start-on-event=COMRXL_BCP_DBLK_ACTV_BCP_STAT_Lin1_Error, data=Lin1ComRxSignalsSR.COMRXL_BCP_DBLK_ACTV_BCP_STAT_Lin1
      data received event DRECOMRXL_BCP_MONTRNG_RPM_BCP_STAT_Lin1: start-on-event=COMRXL_BCP_MONTRNG_RPM_BCP_STAT_Lin1_Received, data=Lin1ComRxSignalsSR.COMRXL_BCP_MONTRNG_RPM_BCP_STAT_Lin1
      data receive error event DEECOMRXL_BCP_MONTRNG_RPM_BCP_STAT_Lin1: start-on-event=COMRXL_BCP_MONTRNG_RPM_BCP_STAT_Lin1_Error, data=Lin1ComRxSignalsSR.COMRXL_BCP_MONTRNG_RPM_BCP_STAT_Lin1
      data received event DRECOMRXL_BCP_NODE_ERR_BCP_STAT_Lin1: start-on-event=COMRXL_BCP_NODE_ERR_BCP_STAT_Lin1_Received, data=Lin1ComRxSignalsSR.COMRXL_BCP_NODE_ERR_BCP_STAT_Lin1
      data receive error event DEECOMRXL_BCP_NODE_ERR_BCP_STAT_Lin1: start-on-event=COMRXL_BCP_NODE_ERR_BCP_STAT_Lin1_Error, data=Lin1ComRxSignalsSR.COMRXL_BCP_NODE_ERR_BCP_STAT_Lin1
      data received event DRECOMRXL_BCP_POST_RUN_STAT_BCP_STAT_Lin1: start-on-event=COMRXL_BCP_POST_RUN_STAT_BCP_STAT_Lin1_Received, data=Lin1ComRxSignalsSR.COMRXL_BCP_POST_RUN_STAT_BCP_STAT_Lin1
      data receive error event DEECOMRXL_BCP_POST_RUN_STAT_BCP_STAT_Lin1: start-on-event=COMRXL_BCP_POST_RUN_STAT_BCP_STAT_Lin1_Error, data=Lin1ComRxSignalsSR.COMRXL_BCP_POST_RUN_STAT_BCP_STAT_Lin1
      data received event DRECOMRXL_RsErr_BCP_PUMP_BCP_STAT_Lin1: start-on-event=COMRXL_RsErr_BCP_PUMP_BCP_STAT_Lin1_Received, data=Lin1ComRxSignalsSR.COMRXL_RsErr_BCP_PUMP_BCP_STAT_Lin1
      data receive error event DEECOMRXL_RsErr_BCP_PUMP_BCP_STAT_Lin1: start-on-event=COMRXL_RsErr_BCP_PUMP_BCP_STAT_Lin1_Error, data=Lin1ComRxSignalsSR.COMRXL_RsErr_BCP_PUMP_BCP_STAT_Lin1
      data received event DRECOMRXL_BCP_VERSION_BCP_VER_Lin1: start-on-event=COMRXL_BCP_VERSION_BCP_VER_Lin1_Received, data=Lin1ComRxSignalsSR.COMRXL_BCP_VERSION_BCP_VER_Lin1
      data receive error event DEECOMRXL_BCP_VERSION_BCP_VER_Lin1: start-on-event=COMRXL_BCP_VERSION_BCP_VER_Lin1_Error, data=Lin1ComRxSignalsSR.COMRXL_BCP_VERSION_BCP_VER_Lin1
      data received event DRECOMRXL_BCP_SUPPLIER_BCP_VER_Lin1: start-on-event=COMRXL_BCP_SUPPLIER_BCP_VER_Lin1_Received, data=Lin1ComRxSignalsSR.COMRXL_BCP_SUPPLIER_BCP_VER_Lin1
      data receive error event DEECOMRXL_BCP_SUPPLIER_BCP_VER_Lin1: start-on-event=COMRXL_BCP_SUPPLIER_BCP_VER_Lin1_Error, data=Lin1ComRxSignalsSR.COMRXL_BCP_SUPPLIER_BCP_VER_Lin1
      data received event DRECOMRXL_CPV_PosAct_CPV_STAT_V2_Lin1: start-on-event=COMRXL_CPV_PosAct_CPV_STAT_V2_Lin1_Received, data=Lin1ComRxSignalsSR.COMRXL_CPV_PosAct_CPV_STAT_V2_Lin1
      data receive error event DEECOMRXL_CPV_PosAct_CPV_STAT_V2_Lin1: start-on-event=COMRXL_CPV_PosAct_CPV_STAT_V2_Lin1_Error, data=Lin1ComRxSignalsSR.COMRXL_CPV_PosAct_CPV_STAT_V2_Lin1
      data received event DRECOMRXL_CPV_ERR_CPV_STAT_V2_Lin1: start-on-event=COMRXL_CPV_ERR_CPV_STAT_V2_Lin1_Received, data=Lin1ComRxSignalsSR.COMRXL_CPV_ERR_CPV_STAT_V2_Lin1
      data receive error event DEECOMRXL_CPV_ERR_CPV_STAT_V2_Lin1: start-on-event=COMRXL_CPV_ERR_CPV_STAT_V2_Lin1_Error, data=Lin1ComRxSignalsSR.COMRXL_CPV_ERR_CPV_STAT_V2_Lin1
      data received event DRECOMRXL_CPV_Sts_CPV_STAT_V2_Lin1: start-on-event=COMRXL_CPV_Sts_CPV_STAT_V2_Lin1_Received, data=Lin1ComRxSignalsSR.COMRXL_CPV_Sts_CPV_STAT_V2_Lin1
      data receive error event DEECOMRXL_CPV_Sts_CPV_STAT_V2_Lin1: start-on-event=COMRXL_CPV_Sts_CPV_STAT_V2_Lin1_Error, data=Lin1ComRxSignalsSR.COMRXL_CPV_Sts_CPV_STAT_V2_Lin1
      data received event DRECOMRXL_RsErr_CPV_CPV_STAT_V2_Lin1: start-on-event=COMRXL_RsErr_CPV_CPV_STAT_V2_Lin1_Received, data=Lin1ComRxSignalsSR.COMRXL_RsErr_CPV_CPV_STAT_V2_Lin1
      data receive error event DEECOMRXL_RsErr_CPV_CPV_STAT_V2_Lin1: start-on-event=COMRXL_RsErr_CPV_CPV_STAT_V2_Lin1_Error, data=Lin1ComRxSignalsSR.COMRXL_RsErr_CPV_CPV_STAT_V2_Lin1
      data received event DRECOMRXL_AirHeatrICns_HVEAHLIN18Fr01_Lin1: start-on-event=COMRXL_AirHeatrICns_HVEAHLIN18Fr01_Lin1_Received, data=Lin1ComRxSignalsSR.COMRXL_AirHeatrICns_HVEAHLIN18Fr01_Lin1
      data receive error event DEECOMRXL_AirHeatrICns_HVEAHLIN18Fr01_Lin1: start-on-event=COMRXL_AirHeatrICns_HVEAHLIN18Fr01_Lin1_Error, data=Lin1ComRxSignalsSR.COMRXL_AirHeatrICns_HVEAHLIN18Fr01_Lin1
      data received event DRECOMRXL_AirHeatrHVmeas_HVEAHLIN18Fr01_Lin1: start-on-event=COMRXL_AirHeatrHVmeas_HVEAHLIN18Fr01_Lin1_Received, data=Lin1ComRxSignalsSR.COMRXL_AirHeatrHVmeas_HVEAHLIN18Fr01_Lin1
      data receive error event DEECOMRXL_AirHeatrHVmeas_HVEAHLIN18Fr01_Lin1: start-on-event=COMRXL_AirHeatrHVmeas_HVEAHLIN18Fr01_Lin1_Error, data=Lin1ComRxSignalsSR.COMRXL_AirHeatrHVmeas_HVEAHLIN18Fr01_Lin1
      data received event DRECOMRXL_AirHeatrPCBTemp_HVEAHLIN18Fr01_Lin1: start-on-event=COMRXL_AirHeatrPCBTemp_HVEAHLIN18Fr01_Lin1_Received, data=Lin1ComRxSignalsSR.COMRXL_AirHeatrPCBTemp_HVEAHLIN18Fr01_Lin1
      data receive error event DEECOMRXL_AirHeatrPCBTemp_HVEAHLIN18Fr01_Lin1: start-on-event=COMRXL_AirHeatrPCBTemp_HVEAHLIN18Fr01_Lin1_Error, data=Lin1ComRxSignalsSR.COMRXL_AirHeatrPCBTemp_HVEAHLIN18Fr01_Lin1
      data received event DRECOMRXL_AirHeatrCoreTemp_HVEAHLIN18Fr01_Lin1: start-on-event=COMRXL_AirHeatrCoreTemp_HVEAHLIN18Fr01_Lin1_Received, data=Lin1ComRxSignalsSR.COMRXL_AirHeatrCoreTemp_HVEAHLIN18Fr01_Lin1
      data receive error event DEECOMRXL_AirHeatrCoreTemp_HVEAHLIN18Fr01_Lin1: start-on-event=COMRXL_AirHeatrCoreTemp_HVEAHLIN18Fr01_Lin1_Error, data=Lin1ComRxSignalsSR.COMRXL_AirHeatrCoreTemp_HVEAHLIN18Fr01_Lin1
      data received event DRECOMRXL_RsErr_EAH_HVEAHLIN18Fr02_Lin1: start-on-event=COMRXL_RsErr_EAH_HVEAHLIN18Fr02_Lin1_Received, data=Lin1ComRxSignalsSR.COMRXL_RsErr_EAH_HVEAHLIN18Fr02_Lin1
      data receive error event DEECOMRXL_RsErr_EAH_HVEAHLIN18Fr02_Lin1: start-on-event=COMRXL_RsErr_EAH_HVEAHLIN18Fr02_Lin1_Error, data=Lin1ComRxSignalsSR.COMRXL_RsErr_EAH_HVEAHLIN18Fr02_Lin1
      data received event DRECOMRXL_AirHeatrWarnFltInCom_HVEAHLIN18Fr02_Lin1: start-on-event=COMRXL_AirHeatrWarnFltInCom_HVEAHLIN18Fr02_Lin1_Received, data=Lin1ComRxSignalsSR.COMRXL_AirHeatrWarnFltInCom_HVEAHLIN18Fr02_Lin1
      data receive error event DEECOMRXL_AirHeatrWarnFltInCom_HVEAHLIN18Fr02_Lin1: start-on-event=COMRXL_AirHeatrWarnFltInCom_HVEAHLIN18Fr02_Lin1_Error, data=Lin1ComRxSignalsSR.COMRXL_AirHeatrWarnFltInCom_HVEAHLIN18Fr02_Lin1
      data received event DRECOMRXL_AirHeatrWarnHvOutOfRng_HVEAHLIN18Fr02_Lin1: start-on-event=COMRXL_AirHeatrWarnHvOutOfRng_HVEAHLIN18Fr02_Lin1_Received, data=Lin1ComRxSignalsSR.COMRXL_AirHeatrWarnHvOutOfRng_HVEAHLIN18Fr02_Lin1
      data receive error event DEECOMRXL_AirHeatrWarnHvOutOfRng_HVEAHLIN18Fr02_Lin1: start-on-event=COMRXL_AirHeatrWarnHvOutOfRng_HVEAHLIN18Fr02_Lin1_Error, data=Lin1ComRxSignalsSR.COMRXL_AirHeatrWarnHvOutOfRng_HVEAHLIN18Fr02_Lin1
      data received event DRECOMRXL_AirHeatrWarnULoOutOfRng_HVEAHLIN18Fr02_Lin1: start-on-event=COMRXL_AirHeatrWarnULoOutOfRng_HVEAHLIN18Fr02_Lin1_Received, data=Lin1ComRxSignalsSR.COMRXL_AirHeatrWarnULoOutOfRng_HVEAHLIN18Fr02_Lin1
      data receive error event DEECOMRXL_AirHeatrWarnULoOutOfRng_HVEAHLIN18Fr02_Lin1: start-on-event=COMRXL_AirHeatrWarnULoOutOfRng_HVEAHLIN18Fr02_Lin1_Error, data=Lin1ComRxSignalsSR.COMRXL_AirHeatrWarnULoOutOfRng_HVEAHLIN18Fr02_Lin1
      data received event DRECOMRXL_AirHeatrWarnTmpOvrheatg_HVEAHLIN18Fr02_Lin1: start-on-event=COMRXL_AirHeatrWarnTmpOvrheatg_HVEAHLIN18Fr02_Lin1_Received, data=Lin1ComRxSignalsSR.COMRXL_AirHeatrWarnTmpOvrheatg_HVEAHLIN18Fr02_Lin1
      data receive error event DEECOMRXL_AirHeatrWarnTmpOvrheatg_HVEAHLIN18Fr02_Lin1: start-on-event=COMRXL_AirHeatrWarnTmpOvrheatg_HVEAHLIN18Fr02_Lin1_Error, data=Lin1ComRxSignalsSR.COMRXL_AirHeatrWarnTmpOvrheatg_HVEAHLIN18Fr02_Lin1
      data received event DRECOMRXL_AirHeatrWarnICnsOutOfRng_HVEAHLIN18Fr02_Lin1: start-on-event=COMRXL_AirHeatrWarnICnsOutOfRng_HVEAHLIN18Fr02_Lin1_Received, data=Lin1ComRxSignalsSR.COMRXL_AirHeatrWarnICnsOutOfRng_HVEAHLIN18Fr02_Lin1
      data receive error event DEECOMRXL_AirHeatrWarnICnsOutOfRng_HVEAHLIN18Fr02_Lin1: start-on-event=COMRXL_AirHeatrWarnICnsOutOfRng_HVEAHLIN18Fr02_Lin1_Error, data=Lin1ComRxSignalsSR.COMRXL_AirHeatrWarnICnsOutOfRng_HVEAHLIN18Fr02_Lin1
      data received event DRECOMRXL_AirHeatrDmgIntHwProtn_HVEAHLIN18Fr02_Lin1: start-on-event=COMRXL_AirHeatrDmgIntHwProtn_HVEAHLIN18Fr02_Lin1_Received, data=Lin1ComRxSignalsSR.COMRXL_AirHeatrDmgIntHwProtn_HVEAHLIN18Fr02_Lin1
      data receive error event DEECOMRXL_AirHeatrDmgIntHwProtn_HVEAHLIN18Fr02_Lin1: start-on-event=COMRXL_AirHeatrDmgIntHwProtn_HVEAHLIN18Fr02_Lin1_Error, data=Lin1ComRxSignalsSR.COMRXL_AirHeatrDmgIntHwProtn_HVEAHLIN18Fr02_Lin1
      data received event DRECOMRXL_AirHeatrDmgPCBTmpSnsrFlt_HVEAHLIN18Fr02_Lin1: start-on-event=COMRXL_AirHeatrDmgPCBTmpSnsrFlt_HVEAHLIN18Fr02_Lin1_Received, data=Lin1ComRxSignalsSR.COMRXL_AirHeatrDmgPCBTmpSnsrFlt_HVEAHLIN18Fr02_Lin1
      data receive error event DEECOMRXL_AirHeatrDmgPCBTmpSnsrFlt_HVEAHLIN18Fr02_Lin1: start-on-event=COMRXL_AirHeatrDmgPCBTmpSnsrFlt_HVEAHLIN18Fr02_Lin1_Error, data=Lin1ComRxSignalsSR.COMRXL_AirHeatrDmgPCBTmpSnsrFlt_HVEAHLIN18Fr02_Lin1
      data received event DRECOMRXL_AirHeatrDmgCircForDrvrShoOrOpen_HVEAHLIN18Fr02_Lin1: start-on-event=COMRXL_AirHeatrDmgCircForDrvrShoOrOpen_HVEAHLIN18Fr02_Lin1_Received, data=Lin1ComRxSignalsSR.COMRXL_AirHeatrDmgCircForDrvrShoOrOpen_HVEAHLIN18Fr02_Lin1
      data receive error event DEECOMRXL_AirHeatrDmgCircForDrvrShoOrOpen_HVEAHLIN18Fr02_Lin1: start-on-event=COMRXL_AirHeatrDmgCircForDrvrShoOrOpen_HVEAHLIN18Fr02_Lin1_Error, data=Lin1ComRxSignalsSR.COMRXL_AirHeatrDmgCircForDrvrShoOrOpen_HVEAHLIN18Fr02_Lin1
      data received event DRECOMRXL_AirHeatrDmgHVISnsrFlt_HVEAHLIN18Fr02_Lin1: start-on-event=COMRXL_AirHeatrDmgHVISnsrFlt_HVEAHLIN18Fr02_Lin1_Received, data=Lin1ComRxSignalsSR.COMRXL_AirHeatrDmgHVISnsrFlt_HVEAHLIN18Fr02_Lin1
      data receive error event DEECOMRXL_AirHeatrDmgHVISnsrFlt_HVEAHLIN18Fr02_Lin1: start-on-event=COMRXL_AirHeatrDmgHVISnsrFlt_HVEAHLIN18Fr02_Lin1_Error, data=Lin1ComRxSignalsSR.COMRXL_AirHeatrDmgHVISnsrFlt_HVEAHLIN18Fr02_Lin1
      data received event DRECOMRXL_AirHeatrDmgMemErr_HVEAHLIN18Fr02_Lin1: start-on-event=COMRXL_AirHeatrDmgMemErr_HVEAHLIN18Fr02_Lin1_Received, data=Lin1ComRxSignalsSR.COMRXL_AirHeatrDmgMemErr_HVEAHLIN18Fr02_Lin1
      data receive error event DEECOMRXL_AirHeatrDmgMemErr_HVEAHLIN18Fr02_Lin1: start-on-event=COMRXL_AirHeatrDmgMemErr_HVEAHLIN18Fr02_Lin1_Error, data=Lin1ComRxSignalsSR.COMRXL_AirHeatrDmgMemErr_HVEAHLIN18Fr02_Lin1
      data received event DRECOMRXL_AirHeatrDmgHtrCoreTmpSnsrFlt_HVEAHLIN18Fr02_Lin1: start-on-event=COMRXL_AirHeatrDmgHtrCoreTmpSnsrFlt_HVEAHLIN18Fr02_Lin1_Received, data=Lin1ComRxSignalsSR.COMRXL_AirHeatrDmgHtrCoreTmpSnsrFlt_HVEAHLIN18Fr02_Lin1
      data receive error event DEECOMRXL_AirHeatrDmgHtrCoreTmpSnsrFlt_HVEAHLIN18Fr02_Lin1: start-on-event=COMRXL_AirHeatrDmgHtrCoreTmpSnsrFlt_HVEAHLIN18Fr02_Lin1_Error, data=Lin1ComRxSignalsSR.COMRXL_AirHeatrDmgHtrCoreTmpSnsrFlt_HVEAHLIN18Fr02_Lin1
      data received event DRECOMRXL_AirHeatrWarnPCBOvrTmp_HVEAHLIN18Fr02_Lin1: start-on-event=COMRXL_AirHeatrWarnPCBOvrTmp_HVEAHLIN18Fr02_Lin1_Received, data=Lin1ComRxSignalsSR.COMRXL_AirHeatrWarnPCBOvrTmp_HVEAHLIN18Fr02_Lin1
      data receive error event DEECOMRXL_AirHeatrWarnPCBOvrTmp_HVEAHLIN18Fr02_Lin1: start-on-event=COMRXL_AirHeatrWarnPCBOvrTmp_HVEAHLIN18Fr02_Lin1_Error, data=Lin1ComRxSignalsSR.COMRXL_AirHeatrWarnPCBOvrTmp_HVEAHLIN18Fr02_Lin1
      data received event DRECOMRXL_AirHeatrWarnHtrCoreOvrTmp_HVEAHLIN18Fr02_Lin1: start-on-event=COMRXL_AirHeatrWarnHtrCoreOvrTmp_HVEAHLIN18Fr02_Lin1_Received, data=Lin1ComRxSignalsSR.COMRXL_AirHeatrWarnHtrCoreOvrTmp_HVEAHLIN18Fr02_Lin1
      data receive error event DEECOMRXL_AirHeatrWarnHtrCoreOvrTmp_HVEAHLIN18Fr02_Lin1: start-on-event=COMRXL_AirHeatrWarnHtrCoreOvrTmp_HVEAHLIN18Fr02_Lin1_Error, data=Lin1ComRxSignalsSR.COMRXL_AirHeatrWarnHtrCoreOvrTmp_HVEAHLIN18Fr02_Lin1
      data received event DRECOMRXL_EOPA_RPM_TGT_EOPA_STAT_Lin1: start-on-event=COMRXL_EOPA_RPM_TGT_EOPA_STAT_Lin1_Received, data=Lin1ComRxSignalsSR.COMRXL_EOPA_RPM_TGT_EOPA_STAT_Lin1
      data receive error event DEECOMRXL_EOPA_RPM_TGT_EOPA_STAT_Lin1: start-on-event=COMRXL_EOPA_RPM_TGT_EOPA_STAT_Lin1_Error, data=Lin1ComRxSignalsSR.COMRXL_EOPA_RPM_TGT_EOPA_STAT_Lin1
      data received event DRECOMRXL_EOPA_RPM_ACTL_EOPA_STAT_Lin1: start-on-event=COMRXL_EOPA_RPM_ACTL_EOPA_STAT_Lin1_Received, data=Lin1ComRxSignalsSR.COMRXL_EOPA_RPM_ACTL_EOPA_STAT_Lin1
      data receive error event DEECOMRXL_EOPA_RPM_ACTL_EOPA_STAT_Lin1: start-on-event=COMRXL_EOPA_RPM_ACTL_EOPA_STAT_Lin1_Error, data=Lin1ComRxSignalsSR.COMRXL_EOPA_RPM_ACTL_EOPA_STAT_Lin1
      data received event DRECOMRXL_EOPA_VLTG_EOPA_STAT_Lin1: start-on-event=COMRXL_EOPA_VLTG_EOPA_STAT_Lin1_Received, data=Lin1ComRxSignalsSR.COMRXL_EOPA_VLTG_EOPA_STAT_Lin1
      data receive error event DEECOMRXL_EOPA_VLTG_EOPA_STAT_Lin1: start-on-event=COMRXL_EOPA_VLTG_EOPA_STAT_Lin1_Error, data=Lin1ComRxSignalsSR.COMRXL_EOPA_VLTG_EOPA_STAT_Lin1
      data received event DRECOMRXL_EOPA_TEMP_EOPA_STAT_Lin1: start-on-event=COMRXL_EOPA_TEMP_EOPA_STAT_Lin1_Received, data=Lin1ComRxSignalsSR.COMRXL_EOPA_TEMP_EOPA_STAT_Lin1
      data receive error event DEECOMRXL_EOPA_TEMP_EOPA_STAT_Lin1: start-on-event=COMRXL_EOPA_TEMP_EOPA_STAT_Lin1_Error, data=Lin1ComRxSignalsSR.COMRXL_EOPA_TEMP_EOPA_STAT_Lin1
      data received event DRECOMRXL_EOPA_CURR_EOPA_STAT_Lin1: start-on-event=COMRXL_EOPA_CURR_EOPA_STAT_Lin1_Received, data=Lin1ComRxSignalsSR.COMRXL_EOPA_CURR_EOPA_STAT_Lin1
      data receive error event DEECOMRXL_EOPA_CURR_EOPA_STAT_Lin1: start-on-event=COMRXL_EOPA_CURR_EOPA_STAT_Lin1_Error, data=Lin1ComRxSignalsSR.COMRXL_EOPA_CURR_EOPA_STAT_Lin1
      data received event DRECOMRXL_EOPA_LOW_TMP_STAT_EOPA_STAT_Lin1: start-on-event=COMRXL_EOPA_LOW_TMP_STAT_EOPA_STAT_Lin1_Received, data=Lin1ComRxSignalsSR.COMRXL_EOPA_LOW_TMP_STAT_EOPA_STAT_Lin1
      data receive error event DEECOMRXL_EOPA_LOW_TMP_STAT_EOPA_STAT_Lin1: start-on-event=COMRXL_EOPA_LOW_TMP_STAT_EOPA_STAT_Lin1_Error, data=Lin1ComRxSignalsSR.COMRXL_EOPA_LOW_TMP_STAT_EOPA_STAT_Lin1
      data received event DRECOMRXL_EOPA_MONTRNG_RPM_EOPA_STAT_Lin1: start-on-event=COMRXL_EOPA_MONTRNG_RPM_EOPA_STAT_Lin1_Received, data=Lin1ComRxSignalsSR.COMRXL_EOPA_MONTRNG_RPM_EOPA_STAT_Lin1
      data receive error event DEECOMRXL_EOPA_MONTRNG_RPM_EOPA_STAT_Lin1: start-on-event=COMRXL_EOPA_MONTRNG_RPM_EOPA_STAT_Lin1_Error, data=Lin1ComRxSignalsSR.COMRXL_EOPA_MONTRNG_RPM_EOPA_STAT_Lin1
      data received event DRECOMRXL_EOPA_LMP_HM_AN_ON_EOPA_STAT_Lin1: start-on-event=COMRXL_EOPA_LMP_HM_AN_ON_EOPA_STAT_Lin1_Received, data=Lin1ComRxSignalsSR.COMRXL_EOPA_LMP_HM_AN_ON_EOPA_STAT_Lin1
      data receive error event DEECOMRXL_EOPA_LMP_HM_AN_ON_EOPA_STAT_Lin1: start-on-event=COMRXL_EOPA_LMP_HM_AN_ON_EOPA_STAT_Lin1_Error, data=Lin1ComRxSignalsSR.COMRXL_EOPA_LMP_HM_AN_ON_EOPA_STAT_Lin1
      data received event DRECOMRXL_EOPA_OV_TMP_ER_EOPA_STAT_Lin1: start-on-event=COMRXL_EOPA_OV_TMP_ER_EOPA_STAT_Lin1_Received, data=Lin1ComRxSignalsSR.COMRXL_EOPA_OV_TMP_ER_EOPA_STAT_Lin1
      data receive error event DEECOMRXL_EOPA_OV_TMP_ER_EOPA_STAT_Lin1: start-on-event=COMRXL_EOPA_OV_TMP_ER_EOPA_STAT_Lin1_Error, data=Lin1ComRxSignalsSR.COMRXL_EOPA_OV_TMP_ER_EOPA_STAT_Lin1
      data received event DRECOMRXL_EOPA_OV_CUR_ER_EOPA_STAT_Lin1: start-on-event=COMRXL_EOPA_OV_CUR_ER_EOPA_STAT_Lin1_Received, data=Lin1ComRxSignalsSR.COMRXL_EOPA_OV_CUR_ER_EOPA_STAT_Lin1
      data receive error event DEECOMRXL_EOPA_OV_CUR_ER_EOPA_STAT_Lin1: start-on-event=COMRXL_EOPA_OV_CUR_ER_EOPA_STAT_Lin1_Error, data=Lin1ComRxSignalsSR.COMRXL_EOPA_OV_CUR_ER_EOPA_STAT_Lin1
      data received event DRECOMRXL_EOPA_DR_RN_ER_EOPA_STAT_Lin1: start-on-event=COMRXL_EOPA_DR_RN_ER_EOPA_STAT_Lin1_Received, data=Lin1ComRxSignalsSR.COMRXL_EOPA_DR_RN_ER_EOPA_STAT_Lin1
      data receive error event DEECOMRXL_EOPA_DR_RN_ER_EOPA_STAT_Lin1: start-on-event=COMRXL_EOPA_DR_RN_ER_EOPA_STAT_Lin1_Error, data=Lin1ComRxSignalsSR.COMRXL_EOPA_DR_RN_ER_EOPA_STAT_Lin1
      data received event DRECOMRXL_EOPA_VLTG_ER_EOPA_STAT_Lin1: start-on-event=COMRXL_EOPA_VLTG_ER_EOPA_STAT_Lin1_Received, data=Lin1ComRxSignalsSR.COMRXL_EOPA_VLTG_ER_EOPA_STAT_Lin1
      data receive error event DEECOMRXL_EOPA_VLTG_ER_EOPA_STAT_Lin1: start-on-event=COMRXL_EOPA_VLTG_ER_EOPA_STAT_Lin1_Error, data=Lin1ComRxSignalsSR.COMRXL_EOPA_VLTG_ER_EOPA_STAT_Lin1
      data received event DRECOMRXL_EOPA_Stall_Event_EOPA_STAT_Lin1: start-on-event=COMRXL_EOPA_Stall_Event_EOPA_STAT_Lin1_Received, data=Lin1ComRxSignalsSR.COMRXL_EOPA_Stall_Event_EOPA_STAT_Lin1
      data receive error event DEECOMRXL_EOPA_Stall_Event_EOPA_STAT_Lin1: start-on-event=COMRXL_EOPA_Stall_Event_EOPA_STAT_Lin1_Error, data=Lin1ComRxSignalsSR.COMRXL_EOPA_Stall_Event_EOPA_STAT_Lin1
      data received event DRECOMRXL_EOPA_POST_RUN_STAT_EOPA_STAT_Lin1: start-on-event=COMRXL_EOPA_POST_RUN_STAT_EOPA_STAT_Lin1_Received, data=Lin1ComRxSignalsSR.COMRXL_EOPA_POST_RUN_STAT_EOPA_STAT_Lin1
      data receive error event DEECOMRXL_EOPA_POST_RUN_STAT_EOPA_STAT_Lin1: start-on-event=COMRXL_EOPA_POST_RUN_STAT_EOPA_STAT_Lin1_Error, data=Lin1ComRxSignalsSR.COMRXL_EOPA_POST_RUN_STAT_EOPA_STAT_Lin1
      data received event DRECOMRXL_RsErr_EOPA_EOPA_STAT_Lin1: start-on-event=COMRXL_RsErr_EOPA_EOPA_STAT_Lin1_Received, data=Lin1ComRxSignalsSR.COMRXL_RsErr_EOPA_EOPA_STAT_Lin1
      data receive error event DEECOMRXL_RsErr_EOPA_EOPA_STAT_Lin1: start-on-event=COMRXL_RsErr_EOPA_EOPA_STAT_Lin1_Error, data=Lin1ComRxSignalsSR.COMRXL_RsErr_EOPA_EOPA_STAT_Lin1
      data received event DRECOMRXL_EOPA_OIL_TEMP_EOPA_STAT2_Lin1: start-on-event=COMRXL_EOPA_OIL_TEMP_EOPA_STAT2_Lin1_Received, data=Lin1ComRxSignalsSR.COMRXL_EOPA_OIL_TEMP_EOPA_STAT2_Lin1
      data receive error event DEECOMRXL_EOPA_OIL_TEMP_EOPA_STAT2_Lin1: start-on-event=COMRXL_EOPA_OIL_TEMP_EOPA_STAT2_Lin1_Error, data=Lin1ComRxSignalsSR.COMRXL_EOPA_OIL_TEMP_EOPA_STAT2_Lin1
      data received event DRECOMRXL_EOPA_HW_VER_EOPA_VER_Lin1: start-on-event=COMRXL_EOPA_HW_VER_EOPA_VER_Lin1_Received, data=Lin1ComRxSignalsSR.COMRXL_EOPA_HW_VER_EOPA_VER_Lin1
      data receive error event DEECOMRXL_EOPA_HW_VER_EOPA_VER_Lin1: start-on-event=COMRXL_EOPA_HW_VER_EOPA_VER_Lin1_Error, data=Lin1ComRxSignalsSR.COMRXL_EOPA_HW_VER_EOPA_VER_Lin1
      data received event DRECOMRXL_EOPA_SW_VER_EOPA_VER_Lin1: start-on-event=COMRXL_EOPA_SW_VER_EOPA_VER_Lin1_Received, data=Lin1ComRxSignalsSR.COMRXL_EOPA_SW_VER_EOPA_VER_Lin1
      data receive error event DEECOMRXL_EOPA_SW_VER_EOPA_VER_Lin1: start-on-event=COMRXL_EOPA_SW_VER_EOPA_VER_Lin1_Error, data=Lin1ComRxSignalsSR.COMRXL_EOPA_SW_VER_EOPA_VER_Lin1
      data received event DRECOMRXL_LTRBV_PosAct_LTRBV_STAT_Lin1: start-on-event=COMRXL_LTRBV_PosAct_LTRBV_STAT_Lin1_Received, data=Lin1ComRxSignalsSR.COMRXL_LTRBV_PosAct_LTRBV_STAT_Lin1
      data receive error event DEECOMRXL_LTRBV_PosAct_LTRBV_STAT_Lin1: start-on-event=COMRXL_LTRBV_PosAct_LTRBV_STAT_Lin1_Error, data=Lin1ComRxSignalsSR.COMRXL_LTRBV_PosAct_LTRBV_STAT_Lin1
      data received event DRECOMRXL_LTRBV_ERR_LTRBV_STAT_Lin1: start-on-event=COMRXL_LTRBV_ERR_LTRBV_STAT_Lin1_Received, data=Lin1ComRxSignalsSR.COMRXL_LTRBV_ERR_LTRBV_STAT_Lin1
      data receive error event DEECOMRXL_LTRBV_ERR_LTRBV_STAT_Lin1: start-on-event=COMRXL_LTRBV_ERR_LTRBV_STAT_Lin1_Error, data=Lin1ComRxSignalsSR.COMRXL_LTRBV_ERR_LTRBV_STAT_Lin1
      data received event DRECOMRXL_LTRBV_MotorVolt_LTRBV_STAT_Lin1: start-on-event=COMRXL_LTRBV_MotorVolt_LTRBV_STAT_Lin1_Received, data=Lin1ComRxSignalsSR.COMRXL_LTRBV_MotorVolt_LTRBV_STAT_Lin1
      data receive error event DEECOMRXL_LTRBV_MotorVolt_LTRBV_STAT_Lin1: start-on-event=COMRXL_LTRBV_MotorVolt_LTRBV_STAT_Lin1_Error, data=Lin1ComRxSignalsSR.COMRXL_LTRBV_MotorVolt_LTRBV_STAT_Lin1
      data received event DRECOMRXL_LTRBV_Sts_LTRBV_STAT_Lin1: start-on-event=COMRXL_LTRBV_Sts_LTRBV_STAT_Lin1_Received, data=Lin1ComRxSignalsSR.COMRXL_LTRBV_Sts_LTRBV_STAT_Lin1
      data receive error event DEECOMRXL_LTRBV_Sts_LTRBV_STAT_Lin1: start-on-event=COMRXL_LTRBV_Sts_LTRBV_STAT_Lin1_Error, data=Lin1ComRxSignalsSR.COMRXL_LTRBV_Sts_LTRBV_STAT_Lin1
      data received event DRECOMRXL_RsErr_LTRBV_LTRBV_STAT_Lin1: start-on-event=COMRXL_RsErr_LTRBV_LTRBV_STAT_Lin1_Received, data=Lin1ComRxSignalsSR.COMRXL_RsErr_LTRBV_LTRBV_STAT_Lin1
      data receive error event DEECOMRXL_RsErr_LTRBV_LTRBV_STAT_Lin1: start-on-event=COMRXL_RsErr_LTRBV_LTRBV_STAT_Lin1_Error, data=Lin1ComRxSignalsSR.COMRXL_RsErr_LTRBV_LTRBV_STAT_Lin1
      17 x data received event:
        DRESendLINR_AAD_PosRq: start-on-event=SendLINR_AAD_PosRq, data=SendLINR_AAD_PosRq.SendLINR_AAD_PosRq
        DRESendLINR_AAD_CalRq: start-on-event=SendLINR_AAD_CalRq, data=SendLINR_AAD_CalRq.SendLINR_AAD_CalRq
        DRESendLINR_AAD_InitialIP_CalRq: start-on-event=SendLINR_AAD_InitialIP_CalRq, data=SendLINR_AAD_InitialIP_CalRq.SendLINR_AAD_InitialIP_CalRq
        DRESendLINR_BCP_RPM_REQ: start-on-event=SendLINR_BCP_RPM_REQ, data=SendLINR_BCP_RPM_REQ.SendLINR_BCP_RPM_REQ
        DRESendLINR_BCP_POST_RUN_REQ: start-on-event=SendLINR_BCP_POST_RUN_REQ, data=SendLINR_BCP_POST_RUN_REQ.SendLINR_BCP_POST_RUN_REQ
        DRESendLINR_BCP_FL_SAFE_ACTVT: start-on-event=SendLINR_BCP_FL_SAFE_ACTVT, data=SendLINR_BCP_FL_SAFE_ACTVT.SendLINR_BCP_FL_SAFE_ACTVT
        DRESendLINR_CPV_PosRq: start-on-event=SendLINR_CPV_PosRq, data=SendLINR_CPV_PosRq.SendLINR_CPV_PosRq
        DRESendLINR_CPV_PosSv: start-on-event=SendLINR_CPV_PosSv, data=SendLINR_CPV_PosSv.SendLINR_CPV_PosSv
        DRESendLINR_CPV_CalRq: start-on-event=SendLINR_CPV_CalRq, data=SendLINR_CPV_CalRq.SendLINR_CPV_CalRq
        DRESendLINR_AirHeatrPwrTgt: start-on-event=SendLINR_AirHeatrPwrTgt, data=SendLINR_AirHeatrPwrTgt.SendLINR_AirHeatrPwrTgt
        DRESendLINR_AirHeatrEnad: start-on-event=SendLINR_AirHeatrEnad, data=SendLINR_AirHeatrEnad.SendLINR_AirHeatrEnad
        DRESendLINR_EOPA_RPM_COM: start-on-event=SendLINR_EOPA_RPM_COM, data=SendLINR_EOPA_RPM_COM.SendLINR_EOPA_RPM_COM
        DRESendLINR_EOPA_POST_RUN_COM: start-on-event=SendLINR_EOPA_POST_RUN_COM, data=SendLINR_EOPA_POST_RUN_COM.SendLINR_EOPA_POST_RUN_COM
        DRESendLINR_LTRBV_PosRq: start-on-event=SendLINR_LTRBV_PosRq, data=SendLINR_LTRBV_PosRq.SendLINR_LTRBV_PosRq
        DRESendLINR_LTRBV_PosSv: start-on-event=SendLINR_LTRBV_PosSv, data=SendLINR_LTRBV_PosSv.SendLINR_LTRBV_PosSv
        DRESendLINR_LTRBV_CalRq: start-on-event=SendLINR_LTRBV_CalRq, data=SendLINR_LTRBV_CalRq.SendLINR_LTRBV_CalRq
        DRECOMRXL_CPV_MotorVolt_CPV_STAT_V2_Lin1: start-on-event=COMRXL_CPV_MotorVolt_CPV_STAT_V2_Lin1_Received, data=Lin1ComRxSignalsSR.COMRXL_CPV_MotorVolt_CPV_STAT_V2_Lin1
      data receive error event DEECOMRXL_CPV_MotorVolt_CPV_STAT_V2_Lin1: start-on-event=COMRXL_CPV_MotorVolt_CPV_STAT_V2_Lin1_Error, data=Lin1ComRxSignalsSR.COMRXL_CPV_MotorVolt_CPV_STAT_V2_Lin1
      data received event DRECOMRXL_CPV_CalStat_CPV_STAT_V2_Lin1: start-on-event=COMRXL_CPV_CalStat_CPV_STAT_V2_Lin1_Received, data=Lin1ComRxSignalsSR.COMRXL_CPV_CalStat_CPV_STAT_V2_Lin1
      data receive error event DEECOMRXL_CPV_CalStat_CPV_STAT_V2_Lin1: start-on-event=COMRXL_CPV_CalStat_CPV_STAT_V2_Lin1_Error, data=Lin1ComRxSignalsSR.COMRXL_CPV_CalStat_CPV_STAT_V2_Lin1
      data received event DRECOMRXL_AirHeatrSts_HVEAHLIN18Fr01_Lin1: start-on-event=COMRXL_AirHeatrSts_HVEAHLIN18Fr01_Lin1_Received, data=Lin1ComRxSignalsSR.COMRXL_AirHeatrSts_HVEAHLIN18Fr01_Lin1
      data receive error event DEECOMRXL_AirHeatrSts_HVEAHLIN18Fr01_Lin1: start-on-event=COMRXL_AirHeatrSts_HVEAHLIN18Fr01_Lin1_Error, data=Lin1ComRxSignalsSR.COMRXL_AirHeatrSts_HVEAHLIN18Fr01_Lin1
      data received event DRECOMRXL_AirHeatrPwrCns_HVEAHLIN18Fr01_Lin1: start-on-event=COMRXL_AirHeatrPwrCns_HVEAHLIN18Fr01_Lin1_Received, data=Lin1ComRxSignalsSR.COMRXL_AirHeatrPwrCns_HVEAHLIN18Fr01_Lin1
      data receive error event DEECOMRXL_AirHeatrPwrCns_HVEAHLIN18Fr01_Lin1: start-on-event=COMRXL_AirHeatrPwrCns_HVEAHLIN18Fr01_Lin1_Error, data=Lin1ComRxSignalsSR.COMRXL_AirHeatrPwrCns_HVEAHLIN18Fr01_Lin1
      data received event DRECOMRXL_EEXV_PosAct_EEXV_STAT_Lin1: start-on-event=COMRXL_EEXV_PosAct_EEXV_STAT_Lin1_Received, data=Lin1ComRxSignalsSR.COMRXL_EEXV_PosAct_EEXV_STAT_Lin1
      data receive error event DEECOMRXL_EEXV_PosAct_EEXV_STAT_Lin1: start-on-event=COMRXL_EEXV_PosAct_EEXV_STAT_Lin1_Error, data=Lin1ComRxSignalsSR.COMRXL_EEXV_PosAct_EEXV_STAT_Lin1
      data received event DRECOMRXL_EEXV_CalStat_EEXV_STAT_Lin1: start-on-event=COMRXL_EEXV_CalStat_EEXV_STAT_Lin1_Received, data=Lin1ComRxSignalsSR.COMRXL_EEXV_CalStat_EEXV_STAT_Lin1
      data receive error event DEECOMRXL_EEXV_CalStat_EEXV_STAT_Lin1: start-on-event=COMRXL_EEXV_CalStat_EEXV_STAT_Lin1_Error, data=Lin1ComRxSignalsSR.COMRXL_EEXV_CalStat_EEXV_STAT_Lin1
      data received event DRECOMRXL_EEXV_CalRq_EEXV_STAT_Lin1: start-on-event=COMRXL_EEXV_CalRq_EEXV_STAT_Lin1_Received, data=Lin1ComRxSignalsSR.COMRXL_EEXV_CalRq_EEXV_STAT_Lin1
      data receive error event DEECOMRXL_EEXV_CalRq_EEXV_STAT_Lin1: start-on-event=COMRXL_EEXV_CalRq_EEXV_STAT_Lin1_Error, data=Lin1ComRxSignalsSR.COMRXL_EEXV_CalRq_EEXV_STAT_Lin1
      data received event DRECOMRXL_RsErr_EEXV_EEXV_STAT_Lin1: start-on-event=COMRXL_RsErr_EEXV_EEXV_STAT_Lin1_Received, data=Lin1ComRxSignalsSR.COMRXL_RsErr_EEXV_EEXV_STAT_Lin1
      data receive error event DEECOMRXL_RsErr_EEXV_EEXV_STAT_Lin1: start-on-event=COMRXL_RsErr_EEXV_EEXV_STAT_Lin1_Error, data=Lin1ComRxSignalsSR.COMRXL_RsErr_EEXV_EEXV_STAT_Lin1
      data received event DRECOMRXL_EEXV_Sts_EEXV_STAT_Lin1: start-on-event=COMRXL_EEXV_Sts_EEXV_STAT_Lin1_Received, data=Lin1ComRxSignalsSR.COMRXL_EEXV_Sts_EEXV_STAT_Lin1
      data receive error event DEECOMRXL_EEXV_Sts_EEXV_STAT_Lin1: start-on-event=COMRXL_EEXV_Sts_EEXV_STAT_Lin1_Error, data=Lin1ComRxSignalsSR.COMRXL_EEXV_Sts_EEXV_STAT_Lin1
      data received event DRECOMRXL_EEXV_ERR_EEXV_STAT_Lin1: start-on-event=COMRXL_EEXV_ERR_EEXV_STAT_Lin1_Received, data=Lin1ComRxSignalsSR.COMRXL_EEXV_ERR_EEXV_STAT_Lin1
      data receive error event DEECOMRXL_EEXV_ERR_EEXV_STAT_Lin1: start-on-event=COMRXL_EEXV_ERR_EEXV_STAT_Lin1_Error, data=Lin1ComRxSignalsSR.COMRXL_EEXV_ERR_EEXV_STAT_Lin1
      data received event DRECOMRXL_EEXV_SupplyVolt_EEXV_STAT_Lin1: start-on-event=COMRXL_EEXV_SupplyVolt_EEXV_STAT_Lin1_Received, data=Lin1ComRxSignalsSR.COMRXL_EEXV_SupplyVolt_EEXV_STAT_Lin1
      data receive error event DEECOMRXL_EEXV_SupplyVolt_EEXV_STAT_Lin1: start-on-event=COMRXL_EEXV_SupplyVolt_EEXV_STAT_Lin1_Error, data=Lin1ComRxSignalsSR.COMRXL_EEXV_SupplyVolt_EEXV_STAT_Lin1
      data received event DRECOMRXL_EEXV_Refrigerant_Pressure_EEXV_STAT_Lin1: start-on-event=COMRXL_EEXV_Refrigerant_Pressure_EEXV_STAT_Lin1_Received, data=Lin1ComRxSignalsSR.COMRXL_EEXV_Refrigerant_Pressure_EEXV_STAT_Lin1
      data receive error event DEECOMRXL_EEXV_Refrigerant_Pressure_EEXV_STAT_Lin1: start-on-event=COMRXL_EEXV_Refrigerant_Pressure_EEXV_STAT_Lin1_Error, data=Lin1ComRxSignalsSR.COMRXL_EEXV_Refrigerant_Pressure_EEXV_STAT_Lin1
      data received event DRECOMRXL_EEXV_Board_Temp_EEXV_STAT_Lin1: start-on-event=COMRXL_EEXV_Board_Temp_EEXV_STAT_Lin1_Received, data=Lin1ComRxSignalsSR.COMRXL_EEXV_Board_Temp_EEXV_STAT_Lin1
      data receive error event DEECOMRXL_EEXV_Board_Temp_EEXV_STAT_Lin1: start-on-event=COMRXL_EEXV_Board_Temp_EEXV_STAT_Lin1_Error, data=Lin1ComRxSignalsSR.COMRXL_EEXV_Board_Temp_EEXV_STAT_Lin1
      data received event DRECOMRXL_EEXV_Refrigerant_Temp_EEXV_STAT_Lin1: start-on-event=COMRXL_EEXV_Refrigerant_Temp_EEXV_STAT_Lin1_Received, data=Lin1ComRxSignalsSR.COMRXL_EEXV_Refrigerant_Temp_EEXV_STAT_Lin1
      data receive error event DEECOMRXL_EEXV_Refrigerant_Temp_EEXV_STAT_Lin1: start-on-event=COMRXL_EEXV_Refrigerant_Temp_EEXV_STAT_Lin1_Error, data=Lin1ComRxSignalsSR.COMRXL_EEXV_Refrigerant_Temp_EEXV_STAT_Lin1
      data received event DRECOMRXL_EXVM_PosAct_EXVM_STAT_Lin1: start-on-event=COMRXL_EXVM_PosAct_EXVM_STAT_Lin1_Received, data=Lin1ComRxSignalsSR.COMRXL_EXVM_PosAct_EXVM_STAT_Lin1
      data receive error event DEECOMRXL_EXVM_PosAct_EXVM_STAT_Lin1: start-on-event=COMRXL_EXVM_PosAct_EXVM_STAT_Lin1_Error, data=Lin1ComRxSignalsSR.COMRXL_EXVM_PosAct_EXVM_STAT_Lin1
      data received event DRECOMRXL_EXVM_CalStat_EXVM_STAT_Lin1: start-on-event=COMRXL_EXVM_CalStat_EXVM_STAT_Lin1_Received, data=Lin1ComRxSignalsSR.COMRXL_EXVM_CalStat_EXVM_STAT_Lin1
      data receive error event DEECOMRXL_EXVM_CalStat_EXVM_STAT_Lin1: start-on-event=COMRXL_EXVM_CalStat_EXVM_STAT_Lin1_Error, data=Lin1ComRxSignalsSR.COMRXL_EXVM_CalStat_EXVM_STAT_Lin1
      data received event DRECOMRXL_EXVM_CalRq_EXVM_STAT_Lin1: start-on-event=COMRXL_EXVM_CalRq_EXVM_STAT_Lin1_Received, data=Lin1ComRxSignalsSR.COMRXL_EXVM_CalRq_EXVM_STAT_Lin1
      data receive error event DEECOMRXL_EXVM_CalRq_EXVM_STAT_Lin1: start-on-event=COMRXL_EXVM_CalRq_EXVM_STAT_Lin1_Error, data=Lin1ComRxSignalsSR.COMRXL_EXVM_CalRq_EXVM_STAT_Lin1
      data received event DRECOMRXL_RsErr_EXVM_EXVM_STAT_Lin1: start-on-event=COMRXL_RsErr_EXVM_EXVM_STAT_Lin1_Received, data=Lin1ComRxSignalsSR.COMRXL_RsErr_EXVM_EXVM_STAT_Lin1
      data receive error event DEECOMRXL_RsErr_EXVM_EXVM_STAT_Lin1: start-on-event=COMRXL_RsErr_EXVM_EXVM_STAT_Lin1_Error, data=Lin1ComRxSignalsSR.COMRXL_RsErr_EXVM_EXVM_STAT_Lin1
      data received event DRECOMRXL_EXVM_Sts_EXVM_STAT_Lin1: start-on-event=COMRXL_EXVM_Sts_EXVM_STAT_Lin1_Received, data=Lin1ComRxSignalsSR.COMRXL_EXVM_Sts_EXVM_STAT_Lin1
      data receive error event DEECOMRXL_EXVM_Sts_EXVM_STAT_Lin1: start-on-event=COMRXL_EXVM_Sts_EXVM_STAT_Lin1_Error, data=Lin1ComRxSignalsSR.COMRXL_EXVM_Sts_EXVM_STAT_Lin1
      data received event DRECOMRXL_EXVM_ERR_EXVM_STAT_Lin1: start-on-event=COMRXL_EXVM_ERR_EXVM_STAT_Lin1_Received, data=Lin1ComRxSignalsSR.COMRXL_EXVM_ERR_EXVM_STAT_Lin1
      data receive error event DEECOMRXL_EXVM_ERR_EXVM_STAT_Lin1: start-on-event=COMRXL_EXVM_ERR_EXVM_STAT_Lin1_Error, data=Lin1ComRxSignalsSR.COMRXL_EXVM_ERR_EXVM_STAT_Lin1
      data received event DRECOMRXL_EXVM_SupplyVolt_EXVM_STAT_Lin1: start-on-event=COMRXL_EXVM_SupplyVolt_EXVM_STAT_Lin1_Received, data=Lin1ComRxSignalsSR.COMRXL_EXVM_SupplyVolt_EXVM_STAT_Lin1
      data receive error event DEECOMRXL_EXVM_SupplyVolt_EXVM_STAT_Lin1: start-on-event=COMRXL_EXVM_SupplyVolt_EXVM_STAT_Lin1_Error, data=Lin1ComRxSignalsSR.COMRXL_EXVM_SupplyVolt_EXVM_STAT_Lin1
      data received event DRECOMRXL_EXVM_Refrigerant_Pressure_EXVM_STAT_Lin1: start-on-event=COMRXL_EXVM_Refrigerant_Pressure_EXVM_STAT_Lin1_Received, data=Lin1ComRxSignalsSR.COMRXL_EXVM_Refrigerant_Pressure_EXVM_STAT_Lin1
      data receive error event DEECOMRXL_EXVM_Refrigerant_Pressure_EXVM_STAT_Lin1: start-on-event=COMRXL_EXVM_Refrigerant_Pressure_EXVM_STAT_Lin1_Error, data=Lin1ComRxSignalsSR.COMRXL_EXVM_Refrigerant_Pressure_EXVM_STAT_Lin1
      data received event DRECOMRXL_EXVM_Board_Temp_EXVM_STAT_Lin1: start-on-event=COMRXL_EXVM_Board_Temp_EXVM_STAT_Lin1_Received, data=Lin1ComRxSignalsSR.COMRXL_EXVM_Board_Temp_EXVM_STAT_Lin1
      data receive error event DEECOMRXL_EXVM_Board_Temp_EXVM_STAT_Lin1: start-on-event=COMRXL_EXVM_Board_Temp_EXVM_STAT_Lin1_Error, data=Lin1ComRxSignalsSR.COMRXL_EXVM_Board_Temp_EXVM_STAT_Lin1
      data received event DRECOMRXL_EXVM_Refrigerant_Temp_EXVM_STAT_Lin1: start-on-event=COMRXL_EXVM_Refrigerant_Temp_EXVM_STAT_Lin1_Received, data=Lin1ComRxSignalsSR.COMRXL_EXVM_Refrigerant_Temp_EXVM_STAT_Lin1
      data receive error event DEECOMRXL_EXVM_Refrigerant_Temp_EXVM_STAT_Lin1: start-on-event=COMRXL_EXVM_Refrigerant_Temp_EXVM_STAT_Lin1_Error, data=Lin1ComRxSignalsSR.COMRXL_EXVM_Refrigerant_Temp_EXVM_STAT_Lin1
      data received event DRECOMRXL_LTRBV_CalStat_LTRBV_STAT_Lin1: start-on-event=COMRXL_LTRBV_CalStat_LTRBV_STAT_Lin1_Received, data=Lin1ComRxSignalsSR.COMRXL_LTRBV_CalStat_LTRBV_STAT_Lin1
      data receive error event DEECOMRXL_LTRBV_CalStat_LTRBV_STAT_Lin1: start-on-event=COMRXL_LTRBV_CalStat_LTRBV_STAT_Lin1_Error, data=Lin1ComRxSignalsSR.COMRXL_LTRBV_CalStat_LTRBV_STAT_Lin1
      5 x data received event:
        DRESendLINR_EEXV_PosRq: start-on-event=SendLINR_EEXV_PosRq, data=SendLINR_EEXV_PosRq.SendLINR_EEXV_PosRq
        DRESendLINR_EEXV_CalCmd: start-on-event=SendLINR_EEXV_CalCmd, data=SendLINR_EEXV_CalCmd.SendLINR_EEXV_CalCmd
        DRESendLINR_EXVM_PosRq: start-on-event=SendLINR_EXVM_PosRq, data=SendLINR_EXVM_PosRq.SendLINR_EXVM_PosRq
        DRESendLINR_EXVM_CalCmd: start-on-event=SendLINR_EXVM_CalCmd, data=SendLINR_EXVM_CalCmd.SendLINR_EXVM_CalCmd
        DRECOMRXL_CoolantValve_ErrLinCom_CoolantValve_Com_Lin1: start-on-event=COMRXL_CoolantValve_ErrLinCom_CoolantValve_Com_Lin1_Received, data=Lin1ComRxSignalsSR.COMRXL_CoolantValve_ErrLinCom_CoolantValve_Com_Lin1
      data receive error event DEECOMRXL_CoolantValve_ErrLinCom_CoolantValve_Com_Lin1: start-on-event=COMRXL_CoolantValve_ErrLinCom_CoolantValve_Com_Lin1_Error, data=Lin1ComRxSignalsSR.COMRXL_CoolantValve_ErrLinCom_CoolantValve_Com_Lin1
      data received event DRECOMRXL_CoolantValve_ErrPosition_CoolantValve_Com_Lin1: start-on-event=COMRXL_CoolantValve_ErrPosition_CoolantValve_Com_Lin1_Received, data=Lin1ComRxSignalsSR.COMRXL_CoolantValve_ErrPosition_CoolantValve_Com_Lin1
      data receive error event DEECOMRXL_CoolantValve_ErrPosition_CoolantValve_Com_Lin1: start-on-event=COMRXL_CoolantValve_ErrPosition_CoolantValve_Com_Lin1_Error, data=Lin1ComRxSignalsSR.COMRXL_CoolantValve_ErrPosition_CoolantValve_Com_Lin1
      data received event DRECOMRXL_CoolantValve_SelfCalReq_CoolantValve_Com_Lin1: start-on-event=COMRXL_CoolantValve_SelfCalReq_CoolantValve_Com_Lin1_Received, data=Lin1ComRxSignalsSR.COMRXL_CoolantValve_SelfCalReq_CoolantValve_Com_Lin1
      data receive error event DEECOMRXL_CoolantValve_SelfCalReq_CoolantValve_Com_Lin1: start-on-event=COMRXL_CoolantValve_SelfCalReq_CoolantValve_Com_Lin1_Error, data=Lin1ComRxSignalsSR.COMRXL_CoolantValve_SelfCalReq_CoolantValve_Com_Lin1
      data received event DRECOMRXL_CoolantValve_SystemState_CoolantValve_Com_Lin1: start-on-event=COMRXL_CoolantValve_SystemState_CoolantValve_Com_Lin1_Received, data=Lin1ComRxSignalsSR.COMRXL_CoolantValve_SystemState_CoolantValve_Com_Lin1
      data receive error event DEECOMRXL_CoolantValve_SystemState_CoolantValve_Com_Lin1: start-on-event=COMRXL_CoolantValve_SystemState_CoolantValve_Com_Lin1_Error, data=Lin1ComRxSignalsSR.COMRXL_CoolantValve_SystemState_CoolantValve_Com_Lin1
      data received event DRECOMRXL_CoolantValve_EcuVoltage_CoolantValve_Com_Lin1: start-on-event=COMRXL_CoolantValve_EcuVoltage_CoolantValve_Com_Lin1_Received, data=Lin1ComRxSignalsSR.COMRXL_CoolantValve_EcuVoltage_CoolantValve_Com_Lin1
      data receive error event DEECOMRXL_CoolantValve_EcuVoltage_CoolantValve_Com_Lin1: start-on-event=COMRXL_CoolantValve_EcuVoltage_CoolantValve_Com_Lin1_Error, data=Lin1ComRxSignalsSR.COMRXL_CoolantValve_EcuVoltage_CoolantValve_Com_Lin1
      data received event DRECOMRXL_CoolantValve_ActuatorPositionTrgt_CoolantValve_Com_Lin1: start-on-event=COMRXL_CoolantValve_ActuatorPositionTrgt_CoolantValve_Com_Lin1_Received, data=Lin1ComRxSignalsSR.COMRXL_CoolantValve_ActuatorPositionTrgt_CoolantValve_Com_Lin1
      data receive error event DEECOMRXL_CoolantValve_ActuatorPositionTrgt_CoolantValve_Com_Lin1: start-on-event=COMRXL_CoolantValve_ActuatorPositionTrgt_CoolantValve_Com_Lin1_Error, data=Lin1ComRxSignalsSR.COMRXL_CoolantValve_ActuatorPositionTrgt_CoolantValve_Com_Lin1
      data received event DRECOMRXL_CoolantValve_ActuatorPositionAct_CoolantValve_Com_Lin1: start-on-event=COMRXL_CoolantValve_ActuatorPositionAct_CoolantValve_Com_Lin1_Received, data=Lin1ComRxSignalsSR.COMRXL_CoolantValve_ActuatorPositionAct_CoolantValve_Com_Lin1
      data receive error event DEECOMRXL_CoolantValve_ActuatorPositionAct_CoolantValve_Com_Lin1: start-on-event=COMRXL_CoolantValve_ActuatorPositionAct_CoolantValve_Com_Lin1_Error, data=Lin1ComRxSignalsSR.COMRXL_CoolantValve_ActuatorPositionAct_CoolantValve_Com_Lin1
      data received event DRECOMRXL_CoolantValve_EcuTemperatur_CoolantValve_Com_Lin1: start-on-event=COMRXL_CoolantValve_EcuTemperatur_CoolantValve_Com_Lin1_Received, data=Lin1ComRxSignalsSR.COMRXL_CoolantValve_EcuTemperatur_CoolantValve_Com_Lin1
      data receive error event DEECOMRXL_CoolantValve_EcuTemperatur_CoolantValve_Com_Lin1: start-on-event=COMRXL_CoolantValve_EcuTemperatur_CoolantValve_Com_Lin1_Error, data=Lin1ComRxSignalsSR.COMRXL_CoolantValve_EcuTemperatur_CoolantValve_Com_Lin1
      data received event DRECOMRXL_CoolantValve_Err_Motor_CoolantValve_Com_Lin1: start-on-event=COMRXL_CoolantValve_Err_Motor_CoolantValve_Com_Lin1_Received, data=Lin1ComRxSignalsSR.COMRXL_CoolantValve_Err_Motor_CoolantValve_Com_Lin1
      data receive error event DEECOMRXL_CoolantValve_Err_Motor_CoolantValve_Com_Lin1: start-on-event=COMRXL_CoolantValve_Err_Motor_CoolantValve_Com_Lin1_Error, data=Lin1ComRxSignalsSR.COMRXL_CoolantValve_Err_Motor_CoolantValve_Com_Lin1
      data received event DRECOMRXL_CoolantValve_Err_Voltage_CoolantValve_Com_Lin1: start-on-event=COMRXL_CoolantValve_Err_Voltage_CoolantValve_Com_Lin1_Received, data=Lin1ComRxSignalsSR.COMRXL_CoolantValve_Err_Voltage_CoolantValve_Com_Lin1
      data receive error event DEECOMRXL_CoolantValve_Err_Voltage_CoolantValve_Com_Lin1: start-on-event=COMRXL_CoolantValve_Err_Voltage_CoolantValve_Com_Lin1_Error, data=Lin1ComRxSignalsSR.COMRXL_CoolantValve_Err_Voltage_CoolantValve_Com_Lin1
      data received event DRECOMRXL_CoolantValve_Err_Ecu_CoolantValve_Com_Lin1: start-on-event=COMRXL_CoolantValve_Err_Ecu_CoolantValve_Com_Lin1_Received, data=Lin1ComRxSignalsSR.COMRXL_CoolantValve_Err_Ecu_CoolantValve_Com_Lin1
      data receive error event DEECOMRXL_CoolantValve_Err_Ecu_CoolantValve_Com_Lin1: start-on-event=COMRXL_CoolantValve_Err_Ecu_CoolantValve_Com_Lin1_Error, data=Lin1ComRxSignalsSR.COMRXL_CoolantValve_Err_Ecu_CoolantValve_Com_Lin1
      data received event DRECOMRXL_CoolantValve_ResponseError_CoolantValve_Com_Lin1: start-on-event=COMRXL_CoolantValve_ResponseError_CoolantValve_Com_Lin1_Received, data=Lin1ComRxSignalsSR.COMRXL_CoolantValve_ResponseError_CoolantValve_Com_Lin1
      data receive error event DEECOMRXL_CoolantValve_ResponseError_CoolantValve_Com_Lin1: start-on-event=COMRXL_CoolantValve_ResponseError_CoolantValve_Com_Lin1_Error, data=Lin1ComRxSignalsSR.COMRXL_CoolantValve_ResponseError_CoolantValve_Com_Lin1
      10 x data received event:
        DRESendLINR_Control_TargetPos: start-on-event=SendLINR_Control_TargetPos, data=SendLINR_Control_TargetPos.SendLINR_Control_TargetPos
        DRESendLINR_Control_Reserved1: start-on-event=SendLINR_Control_Reserved1, data=SendLINR_Control_Reserved1.SendLINR_Control_Reserved1
        DRESendLINR_Control_BlockDetEnbl: start-on-event=SendLINR_Control_BlockDetEnbl, data=SendLINR_Control_BlockDetEnbl.SendLINR_Control_BlockDetEnbl
        DRESendLINR_Control_DiagFunctnVal: start-on-event=SendLINR_Control_DiagFunctnVal, data=SendLINR_Control_DiagFunctnVal.SendLINR_Control_DiagFunctnVal
        DRESendLINR_Control_Reserved{2..6}: start-on-event=SendLINR_Control_Reserved{2..6}, data=SendLINR_Control_Reserved{2..6}.SendLINR_Control_Reserved{2..6}
        DRESignalLINR_HTRBV_RdyForSleep: start-on-event=SignalLINR_HTRBV_RdyForSleep, data=SignalLINR_HTRBV_RdyForSleep.SignalLINR_HTRBV_RdyForSleep
          disabled-mode:
            MdulPwrMod.AppMode_MDGP_ESH_Mode.RUN
            MdulPwrMod.AppMode_MDGP_ESH_Mode.STARTUP
            MdulPwrMod.AppMode_MDGP_ESH_Mode.SHUTDOWN
            MdulPwrMod.AppMode_MDGP_ESH_Mode.WAKEUP
      explicit-inter-runnable-variables:
        data VeLINR_d_LIN_SlavePrsnt_LIN1: type=uint16, init-value=Value:0  # Each bit inidicates whether a LIN slave is present (equipped or learned). 0 = not present, 1 = present.
        data VeLINR_d_LIN_SlaveRdyToSleep_LIN1: type=uint16, init-value=Value:0  # Each bit indicates whether a LIN slave is ready to sleep. 0 = not ready, 1 = ready
        data VeLINR_d_LIN_SysSts_LIN1: type=uint16, init-value=Value:0  # Bits which indicate LIN system status.
